VERSION "Version"

NS_ :

BS_:

BU_: Tester IBCS EPS ADC CCU CCU_CCURT1 CCU_CCURT2 EPB_IBCS EBB ZCUF ZCUL ZCUR ZCUT EMS IDM DCDC IPS NIDU NIDUF DCUR OBC OPC LPC CPC EMCM GCU DCUF IPU BMS EOPF EOPR EVCC DCDC2 EDL SRS ECS EPB RBM ICM IID IDC PHUDD AMP WHUD IMR INU IFC FAPA RRR RLR PAS PCS SCMR SCMRL SCMRR HVSMR SCMRM MFS WSM DRM IDU FCP LBMSAD AVAS ATSS DLPFL FBLCM FLISD FLLCM FRLCM RLLCMA RLLCMB RRLCMA RRLCMB RLISD DLPML DLPMR TRM PSDL PSDR HVSPRL HVSPRR RFR SBM WCM ETC TBOX2 TBOX CCURT1 CCURT2 RT1_C0 RT1_C1 RT2_C3 CBM RAS TMC SCMT PLGM LBMS RLBMS IDUR OTAWL RCICP WCMFR WCMRL LPC2 SAS CD RCP RRISD

BO_ 371 ADC_13_B: 64 ADC
 SG_ ADC_13_B_CRC : 7|16@0+ (1,0) [0|65535] ""  CCU,EPS,IBCS
 SG_ ADC_13_B_Counter : 23|8@0+ (1,0) [0|255] ""  CCU,EPS,IBCS
 SG_ ADC_DycEscTarTq : 63|16@0+ (1,-32768) [-32768|32767] "Nm"  IBCS
 SG_ ADC_DycEscTarTqfactor : 79|8@0+ (0.01,0) [0|1] ""  IBCS
 SG_ ADC_SteerTqReq : 87|12@0+ (0.01,-20) [-20|20] "Nm"  EPS
 SG_ ADC_SteerTqSt : 157|2@0+ (1,0) [0|3] ""  EPS
 SG_ ADC_TqEvsSteerReq : 152|1@0+ (1,0) [0|1] ""  EPS
 SG_ ADC_SteerTqAvl : 153|1@0+ (1,0) [0|1] ""  EPS
 SG_ ADC_DycEscTarTqVld : 166|1@0+ (1,0) [0|1] ""  IBCS
 SG_ ADC_DycEscTarTqEna : 167|1@0+ (1,0) [0|1] ""  IBCS
 SG_ ADC_RoadTyp : 162|3@0+ (1,0) [0|7] ""  CCU,ECS
 SG_ ADC_LeWhlLgtDst : 175|12@0+ (0.01,0) [0|30] "m"  CCU,ECS
 SG_ ADC_LeWhlRoadHei : 179|12@0+ (0.001,-0.5) [-0.5|0.523] "m"  CCU,ECS
 SG_ ADC_RiWhlLgtDst : 199|12@0+ (0.01,0) [0|30] "m"  CCU,ECS
 SG_ ADC_RiWhlRoadHei : 203|12@0+ (0.001,-0.5) [-0.5|0.523] "m"  CCU,ECS
 SG_ ADC_RiWhlRoadFeature : 223|5@0+ (1,0) [0|15] ""  CCU,ECS
 SG_ ADC_SuspensionStatus : 218|3@0+ (1,0) [0|7] ""  CCU,ECS
 SG_ ADC_LeWhlRoadSts : 231|2@0+ (1,0) [0|3] ""  CCU,ECS
 SG_ ADC_LeWhlRoadFeature : 229|4@0+ (1,0) [0|15] ""  CCU,ECS
 SG_ ADC_RiWhlRoadSts : 225|2@0+ (1,0) [0|3] ""  CCU,ECS
 SG_ ADC_CDCCtrlEnable : 239|1@0+ (1,0) [0|1] ""  CCU,ECS
 SG_ ADC_RoadInfoAvl : 238|1@0+ (1,0) [0|1] ""  CCU,ECS
 SG_ ADC_RoadFeatureDetFalutSts : 295|1@0+ (1,0) [0|1] ""  CCU,ECS
 SG_ ADC_RoadFeatureDetWorkSts : 247|2@0+ (1,0) [0|3] ""  CCU,ECS
 SG_ ADC_LeWhlRoadFeature2 : 251|4@0+ (1,0) [0|15] ""  CCU,ECS
 SG_ ADC_LeWhlRoadFeature3 : 255|4@0+ (1,0) [0|15] ""  CCU,ECS
 SG_ ADC_RiWhlRoadFeature2 : 259|4@0+ (1,0) [0|15] ""  CCU,ECS
 SG_ ADC_RiWhlRoadFeature3 : 263|4@0+ (1,0) [0|15] ""  CCU,ECS
 SG_ ADC_LeWhlRoadHei2 : 271|3@0+ (1,0) [0|7] ""  CCU,ECS
 SG_ ADC_LeWhlRoadHei3 : 268|3@0+ (1,0) [0|7] ""  CCU,ECS
 SG_ ADC_RiWhlRoadHei2 : 265|3@0+ (1,0) [0|7] ""  CCU,ECS
 SG_ ADC_RiWhlRoadHei3 : 278|3@0+ (1,0) [0|7] ""  CCU,ECS
 SG_ ADC_LeWhlLgtDst2 : 237|6@0+ (0.25,0) [0|15] "m"  CCU,ECS
 SG_ ADC_LeWhlLgtDst3 : 245|6@0+ (0.25,0) [0|15] "m"  CCU,ECS
 SG_ ADC_RiWhlLgtDst2 : 275|6@0+ (0.25,0) [0|15] "m"  CCU,ECS
 SG_ ADC_RiWhlLgtDst3 : 285|6@0+ (0.25,0) [0|15] "m"  CCU,ECS
 SG_ ADC_AS_SuspHeiAdj : 290|3@0+ (1,0) [0|7] ""  CCU,ECS
 SG_ ADC_AS_SuspHeiAdjVld : 291|1@0+ (1,0) [0|1] ""  CCU,ECS
 SG_ ADC_AS_SusStfnAdj : 300|3@0+ (1,0) [0|7] ""  CCU,ECS
 SG_ ADC_AS_SusStfnAdjVld : 292|1@0+ (1,0) [0|1] ""  CCU,ECS
 SG_ ADC_CDCModReq : 303|3@0+ (1,0) [0|7] ""  CCU,ECS
 SG_ ADC_CDCModReqVld : 294|1@0+ (1,0) [0|1] ""  CCU,ECS
 SG_ ADC_AS_LevelingAdj : 297|2@0+ (1,0) [0|3] ""  CCU,ECS
 SG_ ADC_AS_LevelingAdjVld : 293|1@0+ (1,0) [0|1] ""  CCU,ECS
 SG_ ADC_SdcPreAdjFL1 : 306|3@0+ (1,0) [0|7] ""  CCU,ECS
 SG_ ADC_SdcPreAdjFR1 : 314|3@0+ (1,0) [0|7] ""  CCU,ECS
 SG_ ADC_SdcPreAdjVld : 311|1@0+ (1,0) [0|1] ""  CCU,ECS
 SG_ ADC_SteerGainLevelTqCtrl : 359|8@0+ (1,0) [0|254] "%"  EPS

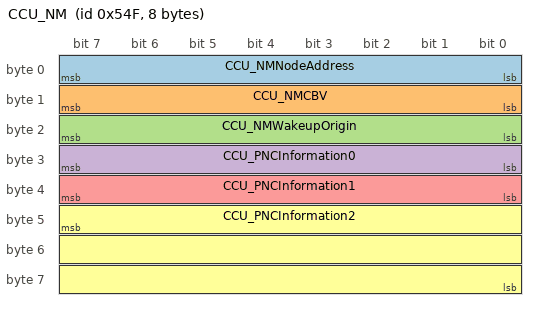
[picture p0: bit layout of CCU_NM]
BO_ 1359 CCU_NM: 8 CCU
 SG_ CCU_NMNodeAddress : 7|8@0+ (1,0) [0|255] ""  CCURT1,TMC,ZCUF,ZCUL,ZCUR,ZCUT,EMS,IPS,NIDU,NIDUF,BMS,EVCC,ECS,CBM,EPB,RBM,IBCS,ICM,IID,IDC,PHUDD,AMP,ADC,FAPA,SCMR,SCMRL,SCMRR,SCMRM,SCMT,IDU,LBMSAD,PLGM,TRM,PSDL,PSDR,LBMS,RLBMS,TBOX
 SG_ CCU_NMCBV : 15|8@0+ (1,0) [0|0] ""  CCURT1,TMC,ZCUF,ZCUL,ZCUR,ZCUT,EMS,IPS,NIDU,NIDUF,BMS,EVCC,ECS,CBM,EPB,RBM,IBCS,ICM,IID,IDC,PHUDD,AMP,ADC,FAPA,SCMR,SCMRL,SCMRR,SCMRM,SCMT,IDU,LBMSAD,PLGM,TRM,PSDL,PSDR,LBMS,RLBMS,TBOX
 SG_ CCU_NMWakeupOrigin : 23|8@0+ (1,0) [0|255] ""  CCURT1,TMC,ZCUF,ZCUL,ZCUR,ZCUT,EMS,IPS,NIDU,NIDUF,BMS,EVCC,ECS,CBM,RBM,IBCS,ICM,IID,IDC,PHUDD,AMP,ADC,FAPA,SCMR,SCMRL,SCMRR,SCMRM,SCMT,IDU,LBMSAD,PLGM,TRM,PSDL,PSDR,LBMS,RLBMS,TBOX
 SG_ CCU_PNCInformation0 : 31|8@0+ (1,0) [0|255] ""  CCURT1,TMC,ZCUF,ZCUL,ZCUR,ZCUT,EMS,IPS,NIDU,NIDUF,BMS,EVCC,ECS,CBM,EPB,RBM,IBCS,ICM,IID,IDC,PHUDD,AMP,ADC,FAPA,SCMR,SCMRL,SCMRR,SCMRM,SCMT,IDU,LBMSAD,PLGM,TRM,PSDL,PSDR,LBMS,RLBMS,TBOX
 SG_ CCU_PNCInformation1 : 39|8@0+ (1,0) [0|255] ""  CCURT1,TMC,ZCUF,ZCUL,ZCUR,ZCUT,EMS,IPS,NIDU,NIDUF,BMS,EVCC,ECS,CBM,EPB,RBM,IBCS,ICM,IID,IDC,PHUDD,AMP,ADC,FAPA,SCMR,SCMRL,SCMRR,SCMRM,SCMT,IDU,LBMSAD,PLGM,TRM,PSDL,PSDR,LBMS,RLBMS,TBOX
 SG_ CCU_PNCInformation2 : 47|24@0+ (1,0) [0|0] ""  CCURT1,TMC,ZCUF,ZCUL,ZCUR,ZCUT,EMS,IPS,NIDU,NIDUF,BMS,EVCC,ECS,CBM,EPB,RBM,IBCS,ICM,IID,IDC,PHUDD,AMP,ADC,FAPA,SCMR,SCMRL,SCMRR,SCMRM,SCMT,IDU,LBMSAD,PLGM,TRM,PSDL,PSDR,LBMS,RLBMS,TBOX

BO_ 905 CCU_IDC_ICM_1: 64 CCU
 SG_ ICM_SetIACCSt : 27|1@0+ (1,0) [0|1] ""  ADC,IFC,FAPA
 SG_ ICM_TotalOdometer : 35|20@0+ (1,0) [0|999999] "km"  ZCUF,ZCUL,ZCUR,ZCUT,EMS,NIDU,NIDUF,DCUR,IDUR,GCU,DCUF,IPU,ECS,EPS,EPB,IBCS,ADC,IFC,FAPA,RRR,RLR,PCS
 SG_ ICM_VehInsSpd : 103|8@0+ (1,0) [0|254] "km/h"  ADC,IFC,FAPA,RRR,RLR
 SG_ ICM_VehInsSpd_accurate : 272|11@0+ (0.1,0) [0|204.6] "km/h"  ECS,WHUD,ADC,IFC,FAPA,RRR,RLR
 SG_ ICM_FuelAvaibleDriveDistance : 311|11@0+ (1,0) [0|2046] "km"  ADC,FAPA
 SG_ ICM_TotalAvaibleDriveDistance : 316|11@0+ (1,0) [0|2046] "km"  ADC,FAPA

BO_ 516 CCU_VCU_9: 64 CCU_CCURT1
 SG_ VCU_9_CRC : 7|16@0+ (1,0) [0|65535] ""  CCURT2,RT2_C3,ZCUF,ZCUL,ZCUR,ZCUT,EMS,NIDU,DCUR,IDUR,EDL,ECS,EPB,IBCS,ICM,IDC,INU,ADC,IFC,FAPA,RRR,RLR,PAS
 SG_ VCU_9_Counter : 23|8@0+ (1,0) [0|255] ""  CCURT2,RT2_C3,ZCUF,ZCUL,ZCUR,ZCUT,EMS,NIDU,DCUR,IDUR,EDL,ECS,EPB,IBCS,ICM,IDC,INU,ADC,IFC,FAPA,RRR,RLR,PAS
 SG_ VCU_MaxDriveTorqVD : 25|1@0+ (1,0) [0|1] ""  ADC,IFC,FAPA
 SG_ VCU_RecpTorqVD : 74|1@0+ (1,0) [0|1] ""  IBCS,ADC,IFC,FAPA
 SG_ VCU_MaxRecpTorqVD : 72|1@0+ (1,0) [0|1] ""  IBCS,ADC,IFC,FAPA
 SG_ VCU_CrntGearLvl : 92|3@0+ (1,0) [0|7] ""  CCURT2,RT2_C3,OTAWL,ZCUF,ZCUL,ZCUR,ZCUT,NIDU,NIDUF,DCUR,IDUR,DCUF,IPU,SRS,ECS,RAS,EPS,EPB,IBCS,IDC,AMP,INU,ADC,IFC,FAPA,RRR,RLR,PAS,WSM,DLPML,DLPMR,TBOX
 SG_ VCU_CrntGearLvlVD : 88|1@0+ (1,0) [0|1] ""  ZCUF,ZCUL,ZCUR,ZCUT,SRS,ECS,EPS,EPB,IBCS,AMP,INU,ADC,IFC,FAPA,RRR,RLR,PAS
 SG_ VCU_BrkPedPstVD : 89|1@0+ (1,0) [0|1] ""  CCURT2,RT2_C3,NIDU,DCUR,IDUR,SRS,ECS,IBCS,IDC,ADC,IFC,FAPA,TBOX
 SG_ VCU_BrkPedPst : 103|8@0+ (0.392,0) [0|99.96] "%"  CCURT2,RT2_C3,NIDU,DCUR,IDUR,SRS,ECS,IBCS,IDC,ADC,IFC,FAPA,TBOX
 SG_ VCU_GearIntervern : 137|1@0+ (1,0) [0|1] ""  IBCS,ADC,IFC,FAPA
 SG_ VCU_AccPedalVirtPstVD : 136|1@0+ (1,0) [0|1] ""  CCURT2,RT2_C3,EMS,NIDU,DCUR,IDUR,SRS,ECS,IBCS,IDC,AMP,ADC,IFC,FAPA,TBOX
 SG_ VCU_ActVehWheelTorq : 378|15@0+ (1,-16000) [-16000|16000] "Nm"  ECS,IBCS,AMP,ADC
 SG_ VCU_MaxRecpTorq : 135|14@0+ (1,0) [0|16000] "Nm"  IBCS,ADC,IFC,FAPA
 SG_ VCU_AccPedalVirtPst : 146|9@0+ (0.2,0) [0|100] "%"  CCURT2,RT2_C3,EMS,NIDU,DCUR,IDUR,SRS,ECS,IBCS,IDC,AMP,ADC,IFC,FAPA,RRR,RLR,TBOX
 SG_ VCU_BrkPedalSt : 189|1@0+ (1,0) [0|1] ""  CCURT2,RT2_C3,EMS,SRS,ECS,IDC,ADC,IFC,FAPA,RRR,RLR,TBOX
 SG_ VCU_BrkPedalStVD : 188|1@0+ (1,0) [0|1] ""  CCURT2,RT2_C3,EMS,SRS,ECS,IDC,ADC,IFC,FAPA,TBOX
 SG_ VCU_ACCLimitOperatingSt : 186|1@0+ (1,0) [0|1] ""  ADC,IFC,FAPA
 SG_ VCU_AccButtInfo : 199|8@0+ (1,0) [0|255] ""  IDC,ADC,IFC,FAPA
 SG_ VCU_ACCmaxSpdLimit : 215|4@0+ (1,0) [0|15] ""  ADC,IFC,FAPA
 SG_ VCU_RecpTorqFAVD : 208|1@0+ (1,0) [0|1] ""  IBCS,ADC,IFC,FAPA
 SG_ VCU_RecpTorqRAVD : 209|1@0+ (1,0) [0|1] ""  IBCS,ADC,IFC,FAPA
 SG_ VCU_MaxRecpTorqFAVD : 152|1@0+ (1,0) [0|1] ""  IBCS,ADC,IFC,FAPA
 SG_ VCU_MaxRecpTorqRAVD : 153|1@0+ (1,0) [0|1] ""  IBCS,ADC,IFC,FAPA
 SG_ VCU_RecpTorq : 359|14@0+ (1,0) [0|16000] "Nm"  IBCS,ADC,IFC,FAPA
 SG_ VCU_MaxDriveTorq : 167|14@0+ (1,0) [0|16000] "Nm"  ECS,IBCS,ADC,IFC,FAPA
 SG_ VCU_RecpTorqFA : 231|14@0+ (1,0) [0|16000] "Nm"  IBCS,ADC,IFC,FAPA
 SG_ VCU_RecpTorqRA : 233|14@0+ (1,0) [0|16000] "Nm"  IBCS,ADC,IFC,FAPA
 SG_ VCU_MaxRecpTorqFA : 251|14@0+ (1,0) [0|16000] "Nm"  IBCS,ADC,IFC,FAPA
 SG_ VCU_MaxRecpTorqRA : 269|14@0+ (1,0) [0|16000] "Nm"  IBCS,ADC,IFC,FAPA
 SG_ VCU_BcsDecelEnable : 305|1@0+ (1,0) [0|1] ""  IBCS,IDC,ADC,IFC,FAPA
 SG_ VCU_CrntGearNoTrans : 317|3@0+ (1,0) [0|7] ""  ADC,IFC,FAPA
 SG_ VCU_EzTSt : 314|2@0+ (1,0) [0|3] ""  IBCS,IDC,ADC,FAPA
 SG_ VCU_ITASSt : 444|3@0+ (1,0) [0|7] ""  IBCS,IDC,ADC,FAPA

BO_ 909 CCU_ZCU_1: 64 CCU_CCURT2
 SG_ LCK_HoodAjarSt : 37|1@0+ (1,0) [0|1] ""  OTAWL,ZCUR,EMS,ECS,ICM,IID,IDC,PHUDD,AMP,ADC,IFC,FAPA,RRR,RLR,PCS
 SG_ LCK_FrontLeftDoorAjarSt : 36|1@0+ (1,0) [0|1] ""  OTAWL,ZCUF,ZCUR,ZCUT,EPB,IBCS,ICM,IID,IDC,PHUDD,AMP,IMR,ADC,IFC,FAPA,RRR,RLR,WSM,DLPML,DLPMR,PLGM
 SG_ LCK_FrontRightDoorAjarSt : 35|1@0+ (1,0) [0|1] ""  ZCUT,IBCS,ICM,IID,IDC,PHUDD,AMP,IMR,ADC,IFC,FAPA,RRR,RLR,WSM,DLPML,DLPMR,PLGM
 SG_ LCK_RearLeftDoorAjarSt : 34|1@0+ (1,0) [0|1] ""  OTAWL,ZCUL,ZCUR,ECS,IBCS,ICM,IID,IDC,PHUDD,AMP,IMR,ADC,IFC,FAPA,RRR,RLR,PCS,SCMR,SCMRL,SCMRR,SCMRM,DLPML,DLPMR,PLGM
 SG_ LCK_RearRightDoorAjarSt : 33|1@0+ (1,0) [0|1] ""  OTAWL,ZCUL,ZCUR,ECS,IBCS,ICM,IID,IDC,PHUDD,AMP,IMR,ADC,IFC,FAPA,RRR,RLR,PCS,SCMR,SCMRL,SCMRR,SCMRM,DLPML,DLPMR,PLGM
 SG_ LCK_TrunkAjarSt : 32|1@0+ (1,0) [0|1] ""  OTAWL,ZCUF,ZCUL,ZCUR,ECS,ICM,IID,IDC,PHUDD,AMP,IMR,ADC,IFC,FAPA,RRR,RLR,PCS
 SG_ LCK_FrontLeftDoorLockSt : 47|1@0+ (1,0) [0|1] ""  OTAWL,ZCUR,CBM,ICM,IDC,ADC,IFC,FAPA,RRR,RLR
 SG_ LCK_FrontRightDoorLockSt : 46|1@0+ (1,0) [0|1] ""  CBM,ICM,IDC,ADC,IFC,FAPA,RRR,RLR
 SG_ LCK_RearLeftDoorLockSt : 45|1@0+ (1,0) [0|1] ""  OTAWL,ZCUL,ZCUR,ECS,CBM,ICM,IDC,ADC,IFC,FAPA,RRR,RLR
 SG_ LCK_RearRightDoorLockSt : 44|1@0+ (1,0) [0|1] ""  OTAWL,ZCUL,ZCUR,ECS,CBM,ICM,IDC,ADC,IFC,FAPA,RRR,RLR
 SG_ LCK_RearLeftChildSaftyLockSt : 43|1@0+ (1,0) [0|1] ""  ZCUL,ZCUR,CBM,ICM,IDC,ADC,IFC,FAPA,RRR,RLR
 SG_ LCK_RearRightChildSaftyLockSt : 42|1@0+ (1,0) [0|1] ""  OTAWL,ZCUL,ZCUR,CBM,ICM,IDC,ADC,IFC,FAPA,RRR,RLR
 SG_ EMS_EngStForPHEV : 79|3@0+ (1,0) [0|7] ""  NIDU,BMS,IDC,ADC,FAPA
 SG_ WCM_Reminder : 103|1@0+ (1,0) [0|1] ""  ADC,FAPA
 SG_ WCM_ChargingSt : 89|2@0+ (1,0) [0|3] ""  ADC,FAPA
 SG_ LCK_FrontLeftDoorHandlePosition : 135|8@0+ (1,0) [0|255] ""  CBM,ICM,IDC,ADC,FAPA
 SG_ LCK_FrontRightDoorHandlePosition : 143|8@0+ (1,0) [0|255] ""  CBM,ICM,IDC,ADC,FAPA
 SG_ LCK_RearLeftDoorHandlePosition : 151|8@0+ (1,0) [0|255] ""  ZCUL,ZCUR,CBM,ICM,IDC,ADC,FAPA
 SG_ LCK_RearRightDoorHandlePosition : 159|8@0+ (1,0) [0|255] ""  ZCUL,ZCUR,CBM,ICM,IDC,ADC,FAPA
 SG_ WW_RWPMotorSt : 226|3@0+ (1,0) [0|7] ""  ADC,IFC,FAPA
 SG_ LCK_FillerCapASt : 239|1@0+ (1,0) [0|1] ""  ZCUL,ZCUR,EMS,ICM,IDC,ADC,FAPA
 SG_ LCK_FillerCapBSt : 238|1@0+ (1,0) [0|1] ""  ZCUL,ZCUR,EMS,ICM,IDC,ADC,FAPA
 SG_ MR_LeftMirrorFoldUnfoldSt : 233|2@0+ (1,0) [0|3] ""  ADC,IFC,FAPA,RRR,RLR,PCS,WSM,DLPML,DLPMR
 SG_ SBM_SwapHvBattModeSt : 247|4@0+ (1,0) [0|15] ""  ADC,FAPA
 SG_ SBM_SwapStaDiagCode : 243|4@0+ (1,0) [0|15] ""  ADC,FAPA
 SG_ SBM_SwapVehDiagCode : 255|4@0+ (1,0) [0|15] ""  ADC,FAPA
 SG_ SBM_SwapHvBattModeFaultSt : 251|3@0+ (1,0) [0|7] ""  ADC,FAPA
 SG_ IPDS_HDMapPowerSt : 271|1@0+ (1,0) [0|1] ""  ADC,IFC,FAPA
 SG_ IPDS_KL15L1PowerSt : 270|1@0+ (1,0) [0|1] ""  EBB,IBCS,ADC,IFC,FAPA,RRR,RLR
 SG_ IPDS_SRSECUPowerSt : 269|1@0+ (1,0) [0|1] ""  EPS,IBCS,ADC,IFC,FAPA
 SG_ IPDS_HODPowerSt : 268|1@0+ (1,0) [0|1] ""  ADC,IFC,FAPA
 SG_ KAE_BLEOption : 265|1@0+ (1,0) [0|1] ""  ADC,FAPA
 SG_ KAE_UWBOption : 264|1@0+ (1,0) [0|1] ""  ADC,FAPA
 SG_ PWL_WinCurrentPos_FLWinPst : 470|8@0+ (0.5,0) [0|100] "%"  ZCUT,ADC,FAPA,PLGM
 SG_ UINM_FrontLeftPowerReleaseReq : 456|1@0+ (1,0) [0|1] ""  ADC,FAPA
 SG_ UINM_FrontLeftPowerReleaseFaultSt : 457|1@0+ (1,0) [0|1] ""  ADC,FAPA
 SG_ UINM_FrontRightPowerReleaseReq : 458|1@0+ (1,0) [0|1] ""  ADC,FAPA
 SG_ UINM_FrontRightPowerReleaseFaultSt : 459|1@0+ (1,0) [0|1] ""  ADC,FAPA
 SG_ UINM_RearLeftPowerReleaseFaultSt : 460|1@0+ (1,0) [0|1] ""  ADC,FAPA
 SG_ UINM_RearLeftPowerReleaseReq : 461|1@0+ (1,0) [0|1] ""  ADC,FAPA
 SG_ UINM_RearRightPowerReleaseFaultSt : 462|1@0+ (1,0) [0|1] ""  ADC,FAPA
 SG_ UINM_RearRightPowerReleaseReq : 471|1@0+ (1,0) [0|1] ""  ADC,FAPA
 SG_ BMS_BattSOCAccurate : 478|14@0+ (0.01,0) [0|100] "%"  ADC,FAPA
 SG_ PWL_WinCurrentPos_RRWinPst : 503|8@0+ (0.5,0) [0|100] "％"  IDC,RCICP,AMP,IMR,ADC,FAPA,PLGM,HVSPRL,HVSPRR
 SG_ PWL_WinCurrentPos_RLWinPst : 511|8@0+ (0.5,0) [0|100] "％"  ZCUR,IDC,RCICP,AMP,IMR,ADC,FAPA,PLGM,HVSPRL,HVSPRR
 SG_ ACEleclocksSt : 282|3@0+ (1,0) [0|7] ""  ADC,FAPA
 SG_ DSASBM_MotResp : 375|4@0+ (1,0) [0|15] ""  ADC,FAPA

BO_ 792 CCU_ZCU_4: 64 CCU_CCURT2
 SG_ UMM_SecondRHSeatSt : 37|2@0+ (1,0) [0|3] ""  ICM,IDC,ADC,IFC
 SG_ UMM_SecondLHSeatSt : 39|2@0+ (1,0) [0|3] ""  ICM,IDC,ADC,IFC
 SG_ LCK_PowerFillerCapAngle : 103|8@0+ (1,0) [0|255] "deg"  ICM,IDC,ADC,FAPA
 SG_ EL_ReverseLightSt : 111|1@0+ (1,0) [0|1] ""  IDC,ADC,IFC,FAPA,PCS
 SG_ EL_ReverseLightFaultSt : 110|1@0+ (1,0) [0|1] ""  ICM,IDC,ADC,IFC,FAPA
 SG_ EL_RLPositionLightSt : 105|1@0+ (1,0) [0|1] ""  ICM,IDC,ADC,IFC,FAPA
 SG_ EL_RLPositionLightFaultSt : 104|1@0+ (1,0) [0|1] ""  ICM,IDC,ADC,IFC,FAPA
 SG_ EL_RRPositionLightSt : 119|1@0+ (1,0) [0|1] ""  ICM,IDC,ADC,IFC,FAPA
 SG_ EL_RRPositionLightFaultSt : 118|1@0+ (1,0) [0|1] ""  ICM,IDC,ADC,IFC,FAPA
 SG_ EL_RearFogLightSt : 117|1@0+ (1,0) [0|1] ""  ICM,IDC,ADC,IFC,FAPA
 SG_ EL_RearFogLightFaultSt : 116|1@0+ (1,0) [0|1] ""  ICM,IDC,ADC,IFC,FAPA

BO_ 860 CCU_VCU_7: 64 CCU_CCURT1
 SG_ VCU_7_CRC : 7|16@0+ (1,0) [0|65535] ""  CCURT2,RT2_C3,ZCUF,ZCUL,ZCUR,ZCUT,EPB,IDC,ADC,IFC,FAPA,RRR,RLR,DRM
 SG_ VCU_7_Counter : 23|8@0+ (1,0) [0|255] ""  CCURT2,RT2_C3,ZCUF,ZCUL,ZCUR,ZCUT,EPB,IDC,ADC,IFC,FAPA,RRR,RLR,DRM
 SG_ VCU_RoadMod : 27|3@0+ (1,0) [0|7] ""  ECS,IBCS,IDC,ADC,FAPA
 SG_ VCU_GearLvl : 31|4@0+ (1,0) [0|15] ""  CCURT2,RT2_C3,ZCUF,ZCUL,ZCUR,ZCUT,EMS,EPB,IBCS,ADC,IFC,FAPA,RRR,RLR,DRM
 SG_ VCU_VehDrvMod : 38|3@0+ (1,0) [0|7] ""  ZCUL,ZCUR,EMS,ECS,IBCS,ICM,IDC,AMP,ADC,IFC,FAPA,ATSS,WCM,WCMFR,WCMRL
 SG_ VCU_VehRdySt : 39|1@0+ (1,0) [0|1] ""  CCURT2,RT2_C3,OTAWL,ZCUF,ZCUL,ZCUR,ZCUT,EMS,IDM,IPS,NIDU,NIDUF,DCUR,IDUR,OBC,GCU,DCUF,IPU,BMS,ECS,EPB,IBCS,ICM,IID,IDC,PHUDD,ADC,IFC,FAPA,RRR,RLR,TBOX
 SG_ VCU_PlgConnSt : 91|1@0+ (1,0) [0|1] ""  CCURT2,RT2_C3,ZCUR,ZCUT,NIDU,NIDUF,DCUR,IDUR,GCU,DCUF,IPU,ECS,ICM,IID,IDC,PHUDD,ADC,IFC,FAPA
 SG_ VCU_GearLvlDisp : 155|4@0+ (1,0) [0|15] ""  ICM,IID,IDC,PHUDD,WHUD,IMR,ADC,IFC,FAPA,PCS
 SG_ VCU_SuspModeReq : 257|2@0+ (1,0) [0|3] ""  ECS,ADC,IFC,FAPA
 SG_ VCU_SuspModeReqEnable : 316|1@0+ (1,0) [0|1] ""  ECS,ADC,IFC,FAPA
 SG_ VCU_GearPosition : 315|3@0+ (1,0) [0|7] ""  CCURT2,RT2_C3,BMS,ADC,IFC,FAPA
 SG_ VCU_EcoPlusMod : 341|2@0+ (1,0) [0|3] ""  CCURT2,RT2_C3,IDC,WHUD,ADC
 SG_ ICC_RoadMod : 339|4@0+ (1,0) [0|8] ""  CCURT2,RT2_C3,NIDU,BMS,ECS,IBCS,IDC,AMP,ADC,WSM,ATSS
 SG_ VCU_TrailerModeSt : 396|3@0+ (1,0) [0|7] ""  ECS,IBCS,IDC,ADC
 SG_ VCU_BMS_BattSocDisp : 405|14@0+ (0.01,0) [0|100] "%"  CCURT2,RT2_C3,ZCUL,ZCUR,EMS,BMS,ICM,IID,IDC,PHUDD,ADC
 SG_ VCU_VehElcConspAccumAvg : 429|10@0+ (0.1,-51) [-51|51.2] "kWh/100km"  CCURT2,RT2_C3,BMS,IDC,ADC
 SG_ ICC_360Switch : 435|2@0+ (1,0) [0|3] ""  IDC,ADC

BO_ 431 CCU_VCU_8: 64 CCU_CCURT1
 SG_ VCU_TargetRecpTorqVD : 132|1@0+ (1,0) [0|1] ""  IBCS,ADC,IFC,FAPA
 SG_ VCU_AccDriverOrvd : 150|1@0+ (1,0) [0|1] ""  ADC,IFC,FAPA
 SG_ VCU_AccDriverOrvdVD : 154|1@0+ (1,0) [0|1] ""  IBCS,ADC
 SG_ VCU_TargetRecpTorq : 423|14@0+ (1,0) [0|16000] "Nm"  IBCS,ADC,IFC,FAPA
 SG_ VCU_TargetRecpTorqFA : 153|14@0+ (1,0) [0|16000] "Nm"  IBCS,ADC,IFC,FAPA
 SG_ VCU_TargetRecpTorqRA : 171|14@0+ (1,0) [0|16000] "Nm"  IBCS,ADC,IFC,FAPA
 SG_ VCU_TorqDriverReqFA : 189|14@0+ (1,0) [0|16000] "Nm"  ECS,IBCS,ADC,IFC,FAPA
 SG_ VCU_TorqDriverReqRA : 207|14@0+ (1,0) [0|16000] "Nm"  ECS,IBCS,ADC,IFC,FAPA
 SG_ VCU_VehActDrvTorqFA : 209|14@0+ (1,0) [0|16000] "Nm"  ECS,EPS,IBCS,IDC,ADC,IFC,FAPA
 SG_ VCU_VehActDrvTorqRA : 227|14@0+ (1,0) [0|16000] "Nm"  IDM,ECS,EPS,IBCS,IDC,ADC,IFC,FAPA
 SG_ VCU_TargetRecpTorqFAVD : 104|1@0+ (1,0) [0|1] ""  IBCS,ADC,IFC,FAPA
 SG_ VCU_TargetRecpTorqRAVD : 105|1@0+ (1,0) [0|1] ""  IBCS,ADC,IFC,FAPA
 SG_ VCU_TorqDriverReqFAVD : 128|1@0+ (1,0) [0|1] ""  ECS,IBCS,ADC,IFC,FAPA
 SG_ VCU_TorqDriverReqRAVD : 129|1@0+ (1,0) [0|1] ""  ECS,IBCS,ADC,IFC,FAPA
 SG_ VCU_VehActDrvTorqFAVD : 244|1@0+ (1,0) [0|1] ""  ECS,EPS,IBCS,ADC,IFC,FAPA
 SG_ VCU_VehActDrvTorqRAVD : 245|1@0+ (1,0) [0|1] ""  IDM,ECS,EPS,IBCS,ADC,IFC,FAPA
 SG_ VCU_BcsDecelReq : 243|4@0+ (0.066,-0.99) [-0.99|0] "m/s2"  IBCS,ADC,IFC,FAPA
 SG_ VCU_BcsDecelVD : 255|1@0+ (1,0) [0|1] ""  IBCS,ADC,IFC,FAPA
 SG_ VCU_RecpTorqRL : 261|14@0+ (1,0) [0|16000] ""  IBCS,ADC,FAPA
 SG_ VCU_RecpTorqRLVD : 262|1@0+ (1,0) [0|1] ""  IBCS,ADC,FAPA
 SG_ VCU_RecpTorqRR : 277|14@0+ (1,0) [0|16000] ""  IBCS,ADC,FAPA
 SG_ VCU_RecpTorqRRVD : 278|1@0+ (1,0) [0|1] ""  IBCS,ADC,FAPA
 SG_ VCU_ADSNetErrorFb : 159|3@0+ (1,0) [0|7] ""  ADC,IFC,FAPA
 SG_ VCU_NetModeResp : 156|2@0+ (1,0) [0|3] ""  ADC,FAPA
 SG_ VCU_PwrLimDrv_kW : 322|11@0+ (1,-1024) [-1024|1023] "kW"  ADC
 SG_ VCU_PwrLimRegen_kW : 343|11@0+ (1,-1024) [-1024|1023] "kW"  ADC
 SG_ VCU_PwrLimDrv_kWVD : 346|1@0+ (1,0) [0|1] ""  ADC
 SG_ VCU_PwrLimRegen_kWVD : 347|1@0+ (1,0) [0|1] ""  ADC
 SG_ VCU_PtTqActvStsFL : 348|1@0+ (1,0) [0|1] ""  ADC
 SG_ VCU_PtTqActvStsFR : 441|1@0+ (1,0) [0|1] ""  ADC
 SG_ VCU_PtTqActvStsRL : 442|1@0+ (1,0) [0|1] ""  ADC
 SG_ VCU_PtTqActvStsRR : 443|1@0+ (1,0) [0|1] ""  ADC

BO_ 430 CCU_SRS_1: 64 CCU
 SG_ SRS_1_CRC_1 : 7|16@0+ (1,0) [0|65535] ""  ZCUF,ZCUL,ZCUR,ZCUT,EMS,CBM,EPS,EPB,IDC,ADC,IFC,FAPA,RRR,RLR,LBMSAD,PSDL,PSDR,LBMS,TBOX2,TBOX
 SG_ SRS_1_Counter_1 : 23|8@0+ (1,0) [0|255] ""  ZCUF,ZCUL,ZCUR,ZCUT,EMS,CBM,EPS,EPB,IDC,ADC,IFC,FAPA,RRR,RLR,LBMSAD,PSDL,PSDR,LBMS,TBOX2,TBOX
 SG_ SRS_CrashOutputSt : 31|8@0+ (1,0) [0|160] ""  ZCUF,ZCUL,ZCUR,ZCUT,EMS,CBM,IDC,ADC,IFC,FAPA,LBMSAD,PSDL,PSDR,LBMS,TBOX2,TBOX
 SG_ SRS_Front_CrashOutputSt : 39|1@0+ (1,0) [0|1] ""  ZCUF,ZCUL,ZCUR,IDC,ADC,IFC,FAPA,PSDL,PSDR,TBOX2,TBOX
 SG_ SRS_DriverSide_CrashOutputSt : 38|1@0+ (1,0) [0|1] ""  ZCUF,ZCUL,ZCUR,IDC,ADC,IFC,FAPA,PSDL,PSDR,TBOX2,TBOX
 SG_ SRS_PassengerSide_CrashOutputSt : 37|1@0+ (1,0) [0|1] ""  ZCUF,ZCUL,ZCUR,IDC,ADC,IFC,FAPA,PSDL,PSDR,TBOX2,TBOX
 SG_ SRS_Rear_CrashOutputSt : 36|1@0+ (1,0) [0|1] ""  ZCUF,ZCUL,ZCUR,IDC,ADC,IFC,FAPA,PSDL,PSDR,TBOX2,TBOX
 SG_ SRS_RolloverCrashOutputSt : 35|1@0+ (1,0) [0|1] ""  ZCUF,ZCUL,ZCUR,IDC,ADC,IFC,FAPA,PSDL,PSDR,TBOX2,TBOX
 SG_ SRS_NearCrashOutputSt : 34|1@0+ (1,0) [0|1] ""  ZCUF,ZCUL,ZCUR,IDC,ADC,IFC,FAPA,PSDL,PSDR,TBOX2,TBOX
 SG_ SRS_YawSnsCalibSt : 135|1@0+ (1,0) [0|1] ""  ZCUF,ZCUL,ZCUR,IDC,ADC,IFC,FAPA,RRR,RLR,TBOX
 SG_ SRS_VehLongAccelVD : 134|2@0+ (1,0) [0|3] ""  ZCUF,ZCUL,ZCUR,ZCUT,EPS,EPB,IDC,ADC,IFC,FAPA,RRR,RLR,PCS,TBOX
 SG_ SRS_VehLatrlAccelVD : 132|2@0+ (1,0) [0|3] ""  ZCUF,ZCUL,ZCUR,EPS,IDC,ADC,IFC,FAPA,RRR,RLR,PCS,TBOX
 SG_ SRS_YawRateVD : 130|2@0+ (1,0) [0|3] ""  ZCUF,ZCUL,ZCUR,EPS,IDC,ADC,IFC,FAPA,RRR,RLR,PCS,TBOX
 SG_ SRS_VehLongAccel : 143|12@0+ (0.001,-2) [-2|2] "g"  ZCUF,ZCUL,ZCUR,ZCUT,EPS,EPB,IDC,ADC,IFC,FAPA,RRR,RLR,PCS,TBOX
 SG_ SRS_VehLatrlAccel : 147|12@0+ (0.001,-2) [-2|2] "g"  ZCUF,ZCUL,ZCUR,EPS,IDC,ADC,IFC,FAPA,RRR,RLR,PCS,TBOX
 SG_ SRS_YawRate : 167|16@0+ (0.01,-180) [-180|180] "deg/s"  ZCUF,ZCUL,ZCUR,EPS,IDC,ADC,IFC,FAPA,RRR,RLR,PCS,TBOX

BO_ 831 CCU_VCU_4_New: 64 CCU_CCURT1
 SG_ VCU_ChgActiveSt : 183|1@0+ (1,0) [0|1] ""  ZCUL,ICM,IDC,ADC

BO_ 290 CCU_PowerOn: 64 CCU_CCURT1
 SG_ IPDS_FrontRadarPowerSup : 33|2@0+ (1,0) [0|3] ""  CCURT2,RT2_C3,ZCUF,ZCUL,ADC
 SG_ IPDS_FLRadarPowerSup : 47|2@0+ (1,0) [0|3] ""  CCURT2,RT2_C3,ZCUF,ZCUL,ADC
 SG_ IPDS_FRRadarPowerSup : 45|2@0+ (1,0) [0|3] ""  CCURT2,RT2_C3,ZCUF,ZCUL,ADC
 SG_ IPDS_HDMapPowerSup : 79|2@0+ (1,0) [0|3] ""  CCURT2,RT2_C3,ZCUL,ADC
 SG_ IPDS_Lidar1PowerSup : 77|2@0+ (1,0) [0|3] ""  CCURT2,RT2_C3,ZCUL,ADC
 SG_ IPDS_RearRadarPowerSup : 129|2@0+ (1,0) [0|3] ""  CCURT2,RT2_C3,ZCUR,ZCUT,ADC

CM_ SG_ 371 ADC_13_B_CRC "E2E Profile 5 CRC";
CM_ SG_ 371 ADC_13_B_Counter "E2E Profile 5 Counter";
CM_ SG_ 371 ADC_DycEscTarTq "The total target torque of the DYC(Direct  yaw moment control).";
CM_ SG_ 371 ADC_DycEscTarTqfactor "Partition coefficient of  total target torque of the DYC:front axle/total";
CM_ SG_ 371 ADC_SteerTqReq "Steering torque request value";
CM_ SG_ 371 ADC_SteerTqSt "Steering torque request  enable state";
CM_ SG_ 371 ADC_TqEvsSteerReq "Emergency Collision avoidance steering mode request";
CM_ SG_ 371 ADC_SteerTqAvl "Steering torque request avaliable state";
CM_ SG_ 371 ADC_DycEscTarTqVld "The validity of total target torque of the DYC.";
CM_ SG_ 371 ADC_DycEscTarTqEna "The enable status  of total target torque of the DYC.";
CM_ SG_ 371 ADC_RoadTyp "Pavement condition type";
CM_ SG_ 371 ADC_LeWhlLgtDst "The distance from the projection point of the left front wheel center on the ground to the edge of the road feature area";
CM_ SG_ 371 ADC_LeWhlRoadHei "Left front wheel front feature road bump height (or dip depth)";
CM_ SG_ 371 ADC_RiWhlLgtDst "The distance from the projection point of the right front wheel center on the ground to the edge of the road feature area";
CM_ SG_ 371 ADC_RiWhlRoadHei "Right front wheel front feature road bump height (or dip depth)";
CM_ SG_ 371 ADC_RiWhlRoadFeature "Right wheel single road feature type";
CM_ SG_ 371 ADC_SuspensionStatus "ADS air suspension status request";
CM_ SG_ 371 ADC_LeWhlRoadSts "Left wheel pavement uneven (concave/convex) condition";
CM_ SG_ 371 ADC_LeWhlRoadFeature "Left-wheel single road feature type";
CM_ SG_ 371 ADC_RiWhlRoadSts "Uneven (concave/convex) condition of the right wheel pavement";
CM_ SG_ 371 ADC_CDCCtrlEnable "ADS Enable signal";
CM_ SG_ 371 ADC_RoadInfoAvl "Road information significance";
CM_ SG_ 371 ADC_RoadFeatureDetFalutSts "Road feature Dettion Fault Status";
CM_ SG_ 371 ADC_RoadFeatureDetWorkSts "Road feature Dettion Work Status";
CM_ SG_ 371 ADC_LeWhlRoadFeature2 "Left-wheel single road feature2 type";
CM_ SG_ 371 ADC_LeWhlRoadFeature3 "Left-wheel single road feature3 type";
CM_ SG_ 371 ADC_RiWhlRoadFeature2 "Right wheel single road feature2 type";
CM_ SG_ 371 ADC_RiWhlRoadFeature3 "Right wheel single road feature3 type";
CM_ SG_ 371 ADC_LeWhlRoadHei2 "Left front wheel front feature2 road bump height (or dip depth)";
CM_ SG_ 371 ADC_LeWhlRoadHei3 "Left front wheel front feature3 road bump height (or dip depth)";
CM_ SG_ 371 ADC_RiWhlRoadHei2 "Right front wheel front feature2 road bump height (or dip depth)";
CM_ SG_ 371 ADC_RiWhlRoadHei3 "Right front wheel front feature3 road bump height (or dip depth)";
CM_ SG_ 371 ADC_LeWhlLgtDst2 "The distance from the projection point of the left front wheel center on the ground to the edge of the road feature2 area";
CM_ SG_ 371 ADC_LeWhlLgtDst3 "The distance from the projection point of the left front wheel center on the ground to the edge of the road feature3 area";
CM_ SG_ 371 ADC_RiWhlLgtDst2 "The distance from the projection point of the right front wheel center on the ground to the edge of the road feature2 area";
CM_ SG_ 371 ADC_RiWhlLgtDst3 "The distance from the projection point of the right front wheel center on the ground to the edge of the road feature3 area";
CM_ SG_ 371 ADC_AS_SuspHeiAdj "Request suspension adjustment control signal";
CM_ SG_ 371 ADC_AS_SuspHeiAdjVld "Request?suspension?adjustment?control?significant?signal";
CM_ SG_ 371 ADC_AS_SusStfnAdj "Request suspension stiffness adjustment control signal";
CM_ SG_ 371 ADC_AS_SusStfnAdjVld "Request suspension stiffness adjustment to control the significant signal";
CM_ SG_ 371 ADC_CDCModReq "Request?shock?absorber?damper?adjustment?control?signal";
CM_ SG_ 371 ADC_CDCModReqVld "Request damper damper regulation control significant signal";
CM_ SG_ 371 ADC_AS_LevelingAdj "ADS requests dynamic leveling of the suspension";
CM_ SG_ 371 ADC_AS_LevelingAdjVld "ADS requests dynamic leveling of the suspension significant?signal";
CM_ SG_ 371 ADC_SdcPreAdjFL1 "Based on the unevenness of the road ahead, ADC sends a pre-adjustment gear signal, and the actuator adjusts the damping according to the pre-adjustment gear signal from ADC.";
CM_ SG_ 371 ADC_SdcPreAdjFR1 "Based on the unevenness of the road ahead, ADC sends a pre-adjustment gear signal, and the actuator adjusts the damping according to the pre-adjustment gear signal from ADC.";
CM_ SG_ 371 ADC_SdcPreAdjVld "The valid bit signal of the pre-regulation function";
CM_ SG_ 371 ADC_SteerGainLevelTqCtrl "Driver steering torque gain request value";
CM_ SG_ 1359 CCU_NMNodeAddress "CCU node address";
CM_ SG_ 1359 CCU_NMCBV "CCU Network management control bit vector";
CM_ SG_ 1359 CCU_NMWakeupOrigin "Origin of the wake up";
CM_ SG_ 1359 CCU_PNCInformation0 "PNC Information";
CM_ SG_ 1359 CCU_PNCInformation1 "PNC Information";
CM_ SG_ 1359 CCU_PNCInformation2 "PNC Information";
CM_ SG_ 905 ICM_SetIACCSt "ICM set IACC status";
CM_ SG_ 905 ICM_TotalOdometer "Total odometer";
CM_ SG_ 905 ICM_VehInsSpd "Vehicle instantaneous speed";
CM_ SG_ 905 ICM_VehInsSpd_accurate "Vehicle instantaneous speed";
CM_ SG_ 905 ICM_FuelAvaibleDriveDistance "The available driving distance according to the fuel";
CM_ SG_ 905 ICM_TotalAvaibleDriveDistance "The available driving distance according to the total";
CM_ SG_ 516 VCU_9_CRC "E2E Profile 5 CRC";
CM_ SG_ 516 VCU_9_Counter "E2E Profile 5 Counter";
CM_ SG_ 516 VCU_MaxDriveTorqVD "Actual effective maximum adjustable torque on wheel level validity";
CM_ SG_ 516 VCU_RecpTorqVD "Status of recuperation torque of generator";
CM_ SG_ 516 VCU_MaxRecpTorqVD "Status of target recuperation torque request by BCS to generator";
CM_ SG_ 516 VCU_CrntGearLvl "VCU current carry out gear level";
CM_ SG_ 516 VCU_CrntGearLvlVD "Valid bit for ActualGearPosition.";
CM_ SG_ 516 VCU_BrkPedPstVD "Current brake pedal position valid data";
CM_ SG_ 516 VCU_BrkPedPst "Current brake pedal position";
CM_ SG_ 516 VCU_GearIntervern "During parking, If there is a request from GSM to change the gearlevel, this signal will be set to 1:with intervention (GSM gearlevel invalid will also be regard as a gearlevel request)";
CM_ SG_ 516 VCU_AccPedalVirtPstVD "Current accelerate pedal actual position validity";
CM_ SG_ 516 VCU_ActVehWheelTorq "Actual effective engine torque on wheel level";
CM_ SG_ 516 VCU_MaxRecpTorq "Current maximum available recuperation torque of generator";
CM_ SG_ 516 VCU_AccPedalVirtPst "Current accelerate pedal actual position";
CM_ SG_ 516 VCU_BrkPedalSt " Brake pedal status";
CM_ SG_ 516 VCU_BrkPedalStVD "VCU_EMS_BrakePedSt valid data";
CM_ SG_ 516 VCU_ACCLimitOperatingSt "Operation status of ACC Limit mode, When VCU Enter the power-saving mode";
CM_ SG_ 516 VCU_AccButtInfo "ACC Button Information";
CM_ SG_ 516 VCU_ACCmaxSpdLimit "When VCU Enter the power-saving mode，the maximum ACC target speed limited by VCU";
CM_ SG_ 516 VCU_RecpTorqFAVD "Status of front axel maximum recuperation torque of generator";
CM_ SG_ 516 VCU_RecpTorqRAVD "Status of rear axel maximum recuperation torque of generator";
CM_ SG_ 516 VCU_MaxRecpTorqFAVD "Status of front axel maximum recuperation torque of generator";
CM_ SG_ 516 VCU_MaxRecpTorqRAVD "Status of front axel maximum recuperation torque of generator";
CM_ SG_ 516 VCU_RecpTorq "Current recuperation torque of generator";
CM_ SG_ 516 VCU_MaxDriveTorq "Actual effective maximum adjustable torque on wheel level";
CM_ SG_ 516 VCU_RecpTorqFA "Current recuperation torque of generator FA";
CM_ SG_ 516 VCU_RecpTorqRA "Current recuperation torque of generator RA";
CM_ SG_ 516 VCU_MaxRecpTorqFA "Current maximum available recuperation torque of generator FA";
CM_ SG_ 516 VCU_MaxRecpTorqRA "Current maximum available recuperation torque of generator RA";
CM_ SG_ 516 VCU_BcsDecelEnable "AVDC deceleration to BCS enable";
CM_ SG_ 516 VCU_CrntGearNoTrans "VCU Gear Lever send to ADS without trans";
CM_ SG_ 516 VCU_EzTSt "This signal indicates VCU-Easy turn state";
CM_ SG_ 516 VCU_ITASSt "This signal indicates VCU state that can enter iTAS or not";
CM_ SG_ 909 LCK_HoodAjarSt "HoodAjarSt";
CM_ SG_ 909 LCK_FrontLeftDoorAjarSt "FrontLeftDoorAjarSt";
CM_ SG_ 909 LCK_FrontRightDoorAjarSt "FrontRightDoorAjarSt";
CM_ SG_ 909 LCK_RearLeftDoorAjarSt "RearLeftDoorAjarSt";
CM_ SG_ 909 LCK_RearRightDoorAjarSt "RearRightDoorAjarSt";
CM_ SG_ 909 LCK_TrunkAjarSt "TrunkAjarSt";
CM_ SG_ 909 LCK_FrontLeftDoorLockSt "FrontLeftDoorLockSt";
CM_ SG_ 909 LCK_FrontRightDoorLockSt "FrontRightDoorLockSt";
CM_ SG_ 909 LCK_RearLeftDoorLockSt "RearLeftDoorLockSt";
CM_ SG_ 909 LCK_RearRightDoorLockSt "RearRightDoorLockSt";
CM_ SG_ 909 LCK_RearLeftChildSaftyLockSt "RearLeftChildSaftyLockSt";
CM_ SG_ 909 LCK_RearRightChildSaftyLockSt "RearRightChildSaftyLockSt";
CM_ SG_ 909 EMS_EngStForPHEV "Engine running status for PHEV";
CM_ SG_ 909 WCM_Reminder "Reminder the Phone lft";
CM_ SG_ 909 WCM_ChargingSt "Changing is ongoing or stopped";
CM_ SG_ 909 LCK_FrontLeftDoorHandlePosition "FrontLeftDoorHandlePosition";
CM_ SG_ 909 LCK_FrontRightDoorHandlePosition "FrontRightDoorHandlePosition";
CM_ SG_ 909 LCK_RearLeftDoorHandlePosition "RearLeftDoorHandlePosition";
CM_ SG_ 909 LCK_RearRightDoorHandlePosition "RearRightDoorHandlePosition";
CM_ SG_ 909 WW_RWPMotorSt "RearWiper Motor status";
CM_ SG_ 909 LCK_FillerCapASt "FillerCapASt";
CM_ SG_ 909 LCK_FillerCapBSt "FillerCapBSt";
CM_ SG_ 909 MR_LeftMirrorFoldUnfoldSt "Left Mirror Fold Unfold Status";
CM_ SG_ 909 SBM_SwapHvBattModeSt "Swap station mode statue";
CM_ SG_ 909 SBM_SwapStaDiagCode "Swap station erroe";
CM_ SG_ 909 SBM_SwapVehDiagCode "vehicl erroe in swap station";
CM_ SG_ 909 SBM_SwapHvBattModeFaultSt "Swap station mode fault statue";
CM_ SG_ 909 IPDS_HDMapPowerSt "HD map power state";
CM_ SG_ 909 IPDS_KL15L1PowerSt "KL15 L1 power state";
CM_ SG_ 909 IPDS_SRSECUPowerSt "SRS ECU power state";
CM_ SG_ 909 IPDS_HODPowerSt "HOD power state";
CM_ SG_ 909 KAE_BLEOption "BLEOption";
CM_ SG_ 909 KAE_UWBOption "UWB Option";
CM_ SG_ 909 PWL_WinCurrentPos_FLWinPst "Window Current Position Front left Window";
CM_ SG_ 909 UINM_FrontLeftPowerReleaseReq "FrontLeftPowerReleaseReq";
CM_ SG_ 909 UINM_FrontLeftPowerReleaseFaultSt "Front Left Power Release Swtich fault state";
CM_ SG_ 909 UINM_FrontRightPowerReleaseReq "FrontRightPowerReleaseReq";
CM_ SG_ 909 UINM_FrontRightPowerReleaseFaultSt "Front Right Power Release Swtich fault state";
CM_ SG_ 909 UINM_RearLeftPowerReleaseFaultSt "RearLeftPowerReleaseReq";
CM_ SG_ 909 UINM_RearLeftPowerReleaseReq "RearLeftPowerReleaseReq";
CM_ SG_ 909 UINM_RearRightPowerReleaseFaultSt "RearRightPowerReleaseReq";
CM_ SG_ 909 UINM_RearRightPowerReleaseReq "RearRightPowerReleaseReq";
CM_ SG_ 909 BMS_BattSOCAccurate "Accurate SOC Value sent to other contoller";
CM_ SG_ 909 PWL_WinCurrentPos_RRWinPst "Rear Right Window Current Position";
CM_ SG_ 909 PWL_WinCurrentPos_RLWinPst "Rear Left Window Current Position";
CM_ SG_ 909 ACEleclocksSt "AC gun electronic lock status feedback";
CM_ SG_ 909 DSASBM_MotResp "Driver Side Active Seat Belt Motor Response";
CM_ SG_ 792 UMM_SecondRHSeatSt "Second Right Seat Sensor Status";
CM_ SG_ 792 UMM_SecondLHSeatSt "Second Left Seat Sensor Status";
CM_ SG_ 792 LCK_PowerFillerCapAngle "PowerFillerCapOpenAngle";
CM_ SG_ 792 EL_ReverseLightSt "Reverse light status";
CM_ SG_ 792 EL_ReverseLightFaultSt "Reverse light fault status";
CM_ SG_ 792 EL_RLPositionLightSt "Rear left position light status";
CM_ SG_ 792 EL_RLPositionLightFaultSt "Rear left position light fault status";
CM_ SG_ 792 EL_RRPositionLightSt "Rear right position light status";
CM_ SG_ 792 EL_RRPositionLightFaultSt "Rear right position light fault status";
CM_ SG_ 792 EL_RearFogLightSt "Rear fog light status";
CM_ SG_ 792 EL_RearFogLightFaultSt "Rear fog light fault status";
CM_ SG_ 860 VCU_7_CRC "E2E Profile 5 CRC";
CM_ SG_ 860 VCU_7_Counter "E2E Profile 5 Counter";
CM_ SG_ 860 VCU_RoadMod "Road mode for display";
CM_ SG_ 860 VCU_GearLvl "Gear lever for PEPS";
CM_ SG_ 860 VCU_VehDrvMod "Drive mode for display";
CM_ SG_ 860 VCU_VehRdySt "HEV system ready status";
CM_ SG_ 860 VCU_PlgConnSt "Charge connector  connected Status";
CM_ SG_ 860 VCU_GearLvlDisp "Gear lever for display";
CM_ SG_ 860 VCU_SuspModeReq "VCU to SDC  AVDC mode request ";
CM_ SG_ 860 VCU_SuspModeReqEnable "VCU to SDC AVDC  mode request enable status ";
CM_ SG_ 860 VCU_GearPosition "Gear lever for PEPS TCC";
CM_ SG_ 860 VCU_EcoPlusMod "EcoPlus mode is activated";
CM_ SG_ 860 ICC_RoadMod "Cross-Country Road Mode for Display";
CM_ SG_ 860 VCU_TrailerModeSt "VCU Trailer Mode Status";
CM_ SG_ 860 VCU_BMS_BattSocDisp "Average SOC of battery pack for display";
CM_ SG_ 860 VCU_VehElcConspAccumAvg "Accumulated average electric consumption to A";
CM_ SG_ 860 ICC_360Switch "Switch of 360 under off-road terrain";
CM_ SG_ 431 VCU_TargetRecpTorqVD "Status of  Target cuperation torque of generator";
CM_ SG_ 431 VCU_AccDriverOrvd "Indicating the torque demanded by the driver is higher than the torque demanded by ACC";
CM_ SG_ 431 VCU_AccDriverOrvdVD "Indicating the torque demanded by the driver is higher than the torque demanded by ACC.";
CM_ SG_ 431 VCU_TargetRecpTorq "Current target recuperation torque of generator";
CM_ SG_ 431 VCU_TargetRecpTorqFA "Target cuperation torque of generator for front axel";
CM_ SG_ 431 VCU_TargetRecpTorqRA "Target cuperation torque of generator for rear axel";
CM_ SG_ 431 VCU_TorqDriverReqFA "the driver torque request for front axel";
CM_ SG_ 431 VCU_TorqDriverReqRA "the driver torque request for rear axel or left rear wheel hub motor";
CM_ SG_ 431 VCU_VehActDrvTorqFA "Vehicle actual drive torque for front axel";
CM_ SG_ 431 VCU_VehActDrvTorqRA "Vehicle actual drive torque for  rear axel or  left rear wheel hub motor";
CM_ SG_ 431 VCU_TargetRecpTorqFAVD "Status of? Target cuperation torque of generator for front axel";
CM_ SG_ 431 VCU_TargetRecpTorqRAVD "Status of? Target cuperation torque of generator for rear axel";
CM_ SG_ 431 VCU_TorqDriverReqFAVD "Status of the driver torque request for front axel";
CM_ SG_ 431 VCU_TorqDriverReqRAVD "Status of the driver torque request for rear axel or  left rear wheel hub motor";
CM_ SG_ 431 VCU_VehActDrvTorqFAVD "Vehicle actual drive torque valid data for front axel";
CM_ SG_ 431 VCU_VehActDrvTorqRAVD "Vehicle actual drive torque valid data for rear axel or  left rear wheel hub motor";
CM_ SG_ 431 VCU_BcsDecelReq "target deceleration to BCS by AVDC";
CM_ SG_ 431 VCU_BcsDecelVD "Quality/Fault of AVDC deceleration to BCS";
CM_ SG_ 431 VCU_RecpTorqRL "Current recuperation torque of left rear wheel hub motor";
CM_ SG_ 431 VCU_RecpTorqRLVD "Status ofCurrent recuperation torque of left rear wheel hub motor";
CM_ SG_ 431 VCU_RecpTorqRR "Current recuperation torque of Right rear wheel hub motor";
CM_ SG_ 431 VCU_RecpTorqRRVD "Status ofCurrent recuperation torque of Right rear wheel hub motor";
CM_ SG_ 431 VCU_ADSNetErrorFb "ADS Net Error Feedback";
CM_ SG_ 431 VCU_NetModeResp "VCU Use Net Feedback";
CM_ SG_ 431 VCU_PwrLimDrv_kW "整车分配给驱动系统的最大驱动功率限制（电池可用功率扣除非动力系统功率后的总功率）";
CM_ SG_ 431 VCU_PwrLimRegen_kW "整车分配给驱动系统的最大回馈功率限制（电池可用功率扣除非动力系统功率后的总功率）";
CM_ SG_ 431 VCU_PwrLimDrv_kWVD "整车分配给驱动系统的最大驱动功率限制（电池可用功率扣除非动力系统功率后的总功率）";
CM_ SG_ 431 VCU_PwrLimRegen_kWVD "整车分配给驱动系统的最大回馈功率限制（电池可用功率扣除非动力系统功率后的总功率）";
CM_ SG_ 431 VCU_PtTqActvStsFL "VCU扭矩响应状态";
CM_ SG_ 431 VCU_PtTqActvStsFR "VCU扭矩响应状态";
CM_ SG_ 431 VCU_PtTqActvStsRL "VCU扭矩响应状态";
CM_ SG_ 431 VCU_PtTqActvStsRR "VCU扭矩响应状态";
CM_ SG_ 430 SRS_1_CRC_1 "E2E Profile 5 CRC";
CM_ SG_ 430 SRS_1_Counter_1 "E2E Profile 5 Counter";
CM_ SG_ 430 SRS_CrashOutputSt "To inform there's crash event happened in last 2 seconds.After 2 seconds, the signal will turn to 0(crash here means any one of the 5 status defined below)";
CM_ SG_ 430 SRS_Front_CrashOutputSt "To inform there's front crash event happened in last 2 seconds. After 2 seconds, the signal will turn to 0.";
CM_ SG_ 430 SRS_DriverSide_CrashOutputSt "To inform there's driver side crash event happened in last 2 seconds. After 2 seconds, the signal will turn to 0.(Driver side is the left side for the left-hand-drive vehicle, the right side for the right-hand-drive one. )";
CM_ SG_ 430 SRS_PassengerSide_CrashOutputSt "To inform there's passenger side crash event happened in last 2 seconds. After 2 seconds, the signal will turn to 0.(Passenger side is the right side for the left-hand-drive vehicle, the left side for the right-hand-drive one. )";
CM_ SG_ 430 SRS_Rear_CrashOutputSt "To inform there's rear crash event happened in last 2 seconds. After 2 seconds, the signal will turn to 0.";
CM_ SG_ 430 SRS_RolloverCrashOutputSt "To inform there's rollover crash event happened in last 2 seconds. After 2 seconds, the signal will turn to 0.";
CM_ SG_ 430 SRS_NearCrashOutputSt "To inform there's near crash event happened in last 2 seconds.After 2 seconds, the signal will turn to 0";
CM_ SG_ 430 SRS_YawSnsCalibSt "To indicates  yaw sensor calibration state";
CM_ SG_ 430 SRS_VehLongAccelVD "To indicate vehicle longitudinal acceleration valid state";
CM_ SG_ 430 SRS_VehLatrlAccelVD "To indicate vehicle lateral acceleration valid state";
CM_ SG_ 430 SRS_YawRateVD "To indicate yaw rate valid state";
CM_ SG_ 430 SRS_VehLongAccel "To indicate vehicle longitudinal acceleration";
CM_ SG_ 430 SRS_VehLatrlAccel "To indicate vehicle lateral acceleration";
CM_ SG_ 430 SRS_YawRate "To indicate vehicle yaw rate";
CM_ SG_ 831 VCU_ChgActiveSt "Charge active status";
CM_ SG_ 290 IPDS_FrontRadarPowerSup "Front radar power supply";
CM_ SG_ 290 IPDS_FLRadarPowerSup "Front left radar power supply";
CM_ SG_ 290 IPDS_FRRadarPowerSup "Front right radar power supply";
CM_ SG_ 290 IPDS_HDMapPowerSup "HD map power supply";
CM_ SG_ 290 IPDS_Lidar1PowerSup "Lidar1 power supply";
CM_ SG_ 290 IPDS_RearRadarPowerSup "Rear radar power supply";

BA_DEF_ BO_  "GenMsgCycleTime" INT 0 0;
BA_DEF_ BO_  "GenMsgCycleTimeFast" INT 0 0;
BA_DEF_ BO_  "GenMsgSendType" ENUM  "Periodic","Event","IfActive","POE","PA","FixedPeriodic","Event","EnabledPeriodic","NotUsed","NotUsed","EventPeriodic","NotUsed","NotUsed","NoMsgSendType";
BA_DEF_ BO_  "VFrameFormat" ENUM  "StandardCAN","ExtendedCAN","reserved","reserved","reserved","reserved","reserved","reserved","reserved","reserved","reserved","reserved","reserved","reserved","StandardCAN_FD","ExtendedCAN_FD";
BA_DEF_ BO_  "CANFD_BRS" ENUM  "0","1";
BA_DEF_ SG_  "EventCommandSignal" ENUM  "No","Yes";
BA_DEF_ SG_  "GatewayedSignals" ENUM  "No","Yes";
BA_DEF_ SG_  "GenSigInactiveValue" HEX 0 0;
BA_DEF_ SG_  "GenSigInvalidValue" HEX 0 0;
BA_DEF_ SG_  "GenSigSendType" ENUM  "Trigger","Passive","Cyclic","OnWrite","OnWriteWithRepetition","OnChange","OnChangeWithRepetition","IfActive","IfActiveWithRepetition","NoSigSendType";
BA_DEF_ SG_  "GenSigStartValue" HEX 0 0;
BA_DEF_ SG_  "GenSigTimeoutValue" HEX 0 0;
BA_DEF_ SG_  "Remark" STRING ;
BA_ "GenMsgCycleTime" BO_ 371 10;
BA_ "GenMsgCycleTimeFast" BO_ 371 0;
BA_ "GenMsgSendType" BO_ 371 0;
BA_ "VFrameFormat" BO_ 371 14;
BA_ "CANFD_BRS" BO_ 371 1;
BA_ "GenMsgCycleTime" BO_ 371 10;
BA_ "GenMsgCycleTimeFast" BO_ 371 0;
BA_ "GenMsgSendType" BO_ 371 0;
BA_ "VFrameFormat" BO_ 371 14;
BA_ "CANFD_BRS" BO_ 371 1;
BA_ "GenMsgCycleTime" BO_ 371 10;
BA_ "GenMsgCycleTimeFast" BO_ 371 0;
BA_ "GenMsgSendType" BO_ 371 0;
BA_ "VFrameFormat" BO_ 371 14;
BA_ "CANFD_BRS" BO_ 371 1;
BA_ "GenMsgCycleTime" BO_ 371 10;
BA_ "GenMsgCycleTimeFast" BO_ 371 0;
BA_ "GenMsgSendType" BO_ 371 0;
BA_ "VFrameFormat" BO_ 371 14;
BA_ "CANFD_BRS" BO_ 371 1;
BA_ "GenMsgCycleTime" BO_ 371 10;
BA_ "GenMsgCycleTimeFast" BO_ 371 0;
BA_ "GenMsgSendType" BO_ 371 0;
BA_ "VFrameFormat" BO_ 371 14;
BA_ "CANFD_BRS" BO_ 371 1;
BA_ "GenMsgCycleTime" BO_ 371 10;
BA_ "GenMsgCycleTimeFast" BO_ 371 0;
BA_ "GenMsgSendType" BO_ 371 0;
BA_ "VFrameFormat" BO_ 371 14;
BA_ "CANFD_BRS" BO_ 371 1;
BA_ "GenMsgCycleTime" BO_ 371 10;
BA_ "GenMsgCycleTimeFast" BO_ 371 0;
BA_ "GenMsgSendType" BO_ 371 0;
BA_ "VFrameFormat" BO_ 371 14;
BA_ "CANFD_BRS" BO_ 371 1;
BA_ "GenMsgCycleTime" BO_ 371 10;
BA_ "GenMsgCycleTimeFast" BO_ 371 0;
BA_ "GenMsgSendType" BO_ 371 0;
BA_ "VFrameFormat" BO_ 371 14;
BA_ "CANFD_BRS" BO_ 371 1;
BA_ "GenMsgCycleTime" BO_ 371 10;
BA_ "GenMsgCycleTimeFast" BO_ 371 0;
BA_ "GenMsgSendType" BO_ 371 0;
BA_ "VFrameFormat" BO_ 371 14;
BA_ "CANFD_BRS" BO_ 371 1;
BA_ "GenMsgCycleTime" BO_ 371 10;
BA_ "GenMsgCycleTimeFast" BO_ 371 0;
BA_ "GenMsgSendType" BO_ 371 0;
BA_ "VFrameFormat" BO_ 371 14;
BA_ "CANFD_BRS" BO_ 371 1;
BA_ "GenMsgCycleTime" BO_ 371 10;
BA_ "GenMsgCycleTimeFast" BO_ 371 0;
BA_ "GenMsgSendType" BO_ 371 0;
BA_ "VFrameFormat" BO_ 371 14;
BA_ "CANFD_BRS" BO_ 371 1;
BA_ "GenMsgCycleTime" BO_ 371 10;
BA_ "GenMsgCycleTimeFast" BO_ 371 0;
BA_ "GenMsgSendType" BO_ 371 0;
BA_ "VFrameFormat" BO_ 371 14;
BA_ "CANFD_BRS" BO_ 371 1;
BA_ "GenMsgCycleTime" BO_ 371 10;
BA_ "GenMsgCycleTimeFast" BO_ 371 0;
BA_ "GenMsgSendType" BO_ 371 0;
BA_ "VFrameFormat" BO_ 371 14;
BA_ "CANFD_BRS" BO_ 371 1;
BA_ "GenMsgCycleTime" BO_ 371 10;
BA_ "GenMsgCycleTimeFast" BO_ 371 0;
BA_ "GenMsgSendType" BO_ 371 0;
BA_ "VFrameFormat" BO_ 371 14;
BA_ "CANFD_BRS" BO_ 371 1;
BA_ "GenMsgCycleTime" BO_ 371 10;
BA_ "GenMsgCycleTimeFast" BO_ 371 0;
BA_ "GenMsgSendType" BO_ 371 0;
BA_ "VFrameFormat" BO_ 371 14;
BA_ "CANFD_BRS" BO_ 371 1;
BA_ "GenMsgCycleTime" BO_ 371 10;
BA_ "GenMsgCycleTimeFast" BO_ 371 0;
BA_ "GenMsgSendType" BO_ 371 0;
BA_ "VFrameFormat" BO_ 371 14;
BA_ "CANFD_BRS" BO_ 371 1;
BA_ "GenMsgCycleTime" BO_ 371 10;
BA_ "GenMsgCycleTimeFast" BO_ 371 0;
BA_ "GenMsgSendType" BO_ 371 0;
BA_ "VFrameFormat" BO_ 371 14;
BA_ "CANFD_BRS" BO_ 371 1;
BA_ "GenMsgCycleTime" BO_ 371 10;
BA_ "GenMsgCycleTimeFast" BO_ 371 0;
BA_ "GenMsgSendType" BO_ 371 0;
BA_ "VFrameFormat" BO_ 371 14;
BA_ "CANFD_BRS" BO_ 371 1;
BA_ "GenMsgCycleTime" BO_ 371 10;
BA_ "GenMsgCycleTimeFast" BO_ 371 0;
BA_ "GenMsgSendType" BO_ 371 0;
BA_ "VFrameFormat" BO_ 371 14;
BA_ "CANFD_BRS" BO_ 371 1;
BA_ "GenMsgCycleTime" BO_ 371 10;
BA_ "GenMsgCycleTimeFast" BO_ 371 0;
BA_ "GenMsgSendType" BO_ 371 0;
BA_ "VFrameFormat" BO_ 371 14;
BA_ "CANFD_BRS" BO_ 371 1;
BA_ "GenMsgCycleTime" BO_ 371 10;
BA_ "GenMsgCycleTimeFast" BO_ 371 0;
BA_ "GenMsgSendType" BO_ 371 0;
BA_ "VFrameFormat" BO_ 371 14;
BA_ "CANFD_BRS" BO_ 371 1;
BA_ "GenMsgCycleTime" BO_ 371 10;
BA_ "GenMsgCycleTimeFast" BO_ 371 0;
BA_ "GenMsgSendType" BO_ 371 0;
BA_ "VFrameFormat" BO_ 371 14;
BA_ "CANFD_BRS" BO_ 371 1;
BA_ "GenMsgCycleTime" BO_ 371 10;
BA_ "GenMsgCycleTimeFast" BO_ 371 0;
BA_ "GenMsgSendType" BO_ 371 0;
BA_ "VFrameFormat" BO_ 371 14;
BA_ "CANFD_BRS" BO_ 371 1;
BA_ "GenMsgCycleTime" BO_ 371 10;
BA_ "GenMsgCycleTimeFast" BO_ 371 0;
BA_ "GenMsgSendType" BO_ 371 0;
BA_ "VFrameFormat" BO_ 371 14;
BA_ "CANFD_BRS" BO_ 371 1;
BA_ "GenMsgCycleTime" BO_ 371 10;
BA_ "GenMsgCycleTimeFast" BO_ 371 0;
BA_ "GenMsgSendType" BO_ 371 0;
BA_ "VFrameFormat" BO_ 371 14;
BA_ "CANFD_BRS" BO_ 371 1;
BA_ "GenMsgCycleTime" BO_ 371 10;
BA_ "GenMsgCycleTimeFast" BO_ 371 0;
BA_ "GenMsgSendType" BO_ 371 0;
BA_ "VFrameFormat" BO_ 371 14;
BA_ "CANFD_BRS" BO_ 371 1;
BA_ "GenMsgCycleTime" BO_ 371 10;
BA_ "GenMsgCycleTimeFast" BO_ 371 0;
BA_ "GenMsgSendType" BO_ 371 0;
BA_ "VFrameFormat" BO_ 371 14;
BA_ "CANFD_BRS" BO_ 371 1;
BA_ "GenMsgCycleTime" BO_ 371 10;
BA_ "GenMsgCycleTimeFast" BO_ 371 0;
BA_ "GenMsgSendType" BO_ 371 0;
BA_ "VFrameFormat" BO_ 371 14;
BA_ "CANFD_BRS" BO_ 371 1;
BA_ "GenMsgCycleTime" BO_ 371 10;
BA_ "GenMsgCycleTimeFast" BO_ 371 0;
BA_ "GenMsgSendType" BO_ 371 0;
BA_ "VFrameFormat" BO_ 371 14;
BA_ "CANFD_BRS" BO_ 371 1;
BA_ "GenMsgCycleTime" BO_ 371 10;
BA_ "GenMsgCycleTimeFast" BO_ 371 0;
BA_ "GenMsgSendType" BO_ 371 0;
BA_ "VFrameFormat" BO_ 371 14;
BA_ "CANFD_BRS" BO_ 371 1;
BA_ "GenMsgCycleTime" BO_ 371 10;
BA_ "GenMsgCycleTimeFast" BO_ 371 0;
BA_ "GenMsgSendType" BO_ 371 0;
BA_ "VFrameFormat" BO_ 371 14;
BA_ "CANFD_BRS" BO_ 371 1;
BA_ "GenMsgCycleTime" BO_ 371 10;
BA_ "GenMsgCycleTimeFast" BO_ 371 0;
BA_ "GenMsgSendType" BO_ 371 0;
BA_ "VFrameFormat" BO_ 371 14;
BA_ "CANFD_BRS" BO_ 371 1;
BA_ "GenMsgCycleTime" BO_ 371 10;
BA_ "GenMsgCycleTimeFast" BO_ 371 0;
BA_ "GenMsgSendType" BO_ 371 0;
BA_ "VFrameFormat" BO_ 371 14;
BA_ "CANFD_BRS" BO_ 371 1;
BA_ "GenMsgCycleTime" BO_ 371 10;
BA_ "GenMsgCycleTimeFast" BO_ 371 0;
BA_ "GenMsgSendType" BO_ 371 0;
BA_ "VFrameFormat" BO_ 371 14;
BA_ "CANFD_BRS" BO_ 371 1;
BA_ "GenMsgCycleTime" BO_ 371 10;
BA_ "GenMsgCycleTimeFast" BO_ 371 0;
BA_ "GenMsgSendType" BO_ 371 0;
BA_ "VFrameFormat" BO_ 371 14;
BA_ "CANFD_BRS" BO_ 371 1;
BA_ "GenMsgCycleTime" BO_ 371 10;
BA_ "GenMsgCycleTimeFast" BO_ 371 0;
BA_ "GenMsgSendType" BO_ 371 0;
BA_ "VFrameFormat" BO_ 371 14;
BA_ "CANFD_BRS" BO_ 371 1;
BA_ "GenMsgCycleTime" BO_ 371 10;
BA_ "GenMsgCycleTimeFast" BO_ 371 0;
BA_ "GenMsgSendType" BO_ 371 0;
BA_ "VFrameFormat" BO_ 371 14;
BA_ "CANFD_BRS" BO_ 371 1;
BA_ "GenMsgCycleTime" BO_ 371 10;
BA_ "GenMsgCycleTimeFast" BO_ 371 0;
BA_ "GenMsgSendType" BO_ 371 0;
BA_ "VFrameFormat" BO_ 371 14;
BA_ "CANFD_BRS" BO_ 371 1;
BA_ "GenMsgCycleTime" BO_ 371 10;
BA_ "GenMsgCycleTimeFast" BO_ 371 0;
BA_ "GenMsgSendType" BO_ 371 0;
BA_ "VFrameFormat" BO_ 371 14;
BA_ "CANFD_BRS" BO_ 371 1;
BA_ "GenMsgCycleTime" BO_ 371 10;
BA_ "GenMsgCycleTimeFast" BO_ 371 0;
BA_ "GenMsgSendType" BO_ 371 0;
BA_ "VFrameFormat" BO_ 371 14;
BA_ "CANFD_BRS" BO_ 371 1;
BA_ "GenMsgCycleTime" BO_ 371 10;
BA_ "GenMsgCycleTimeFast" BO_ 371 0;
BA_ "GenMsgSendType" BO_ 371 0;
BA_ "VFrameFormat" BO_ 371 14;
BA_ "CANFD_BRS" BO_ 371 1;
BA_ "GenMsgCycleTime" BO_ 371 10;
BA_ "GenMsgCycleTimeFast" BO_ 371 0;
BA_ "GenMsgSendType" BO_ 371 0;
BA_ "VFrameFormat" BO_ 371 14;
BA_ "CANFD_BRS" BO_ 371 1;
BA_ "GenMsgCycleTime" BO_ 371 10;
BA_ "GenMsgCycleTimeFast" BO_ 371 0;
BA_ "GenMsgSendType" BO_ 371 0;
BA_ "VFrameFormat" BO_ 371 14;
BA_ "CANFD_BRS" BO_ 371 1;
BA_ "GenMsgCycleTime" BO_ 371 10;
BA_ "GenMsgCycleTimeFast" BO_ 371 0;
BA_ "GenMsgSendType" BO_ 371 0;
BA_ "VFrameFormat" BO_ 371 14;
BA_ "CANFD_BRS" BO_ 371 1;
BA_ "GenMsgCycleTime" BO_ 371 10;
BA_ "GenMsgCycleTimeFast" BO_ 371 0;
BA_ "GenMsgSendType" BO_ 371 0;
BA_ "VFrameFormat" BO_ 371 14;
BA_ "CANFD_BRS" BO_ 371 1;
BA_ "GenMsgCycleTime" BO_ 371 10;
BA_ "GenMsgCycleTimeFast" BO_ 371 0;
BA_ "GenMsgSendType" BO_ 371 0;
BA_ "VFrameFormat" BO_ 371 14;
BA_ "CANFD_BRS" BO_ 371 1;
BA_ "GenMsgCycleTime" BO_ 371 10;
BA_ "GenMsgCycleTimeFast" BO_ 371 0;
BA_ "GenMsgSendType" BO_ 371 0;
BA_ "VFrameFormat" BO_ 371 14;
BA_ "CANFD_BRS" BO_ 371 1;
BA_ "GenMsgCycleTime" BO_ 371 10;
BA_ "GenMsgCycleTimeFast" BO_ 371 0;
BA_ "GenMsgSendType" BO_ 371 0;
BA_ "VFrameFormat" BO_ 371 14;
BA_ "CANFD_BRS" BO_ 371 1;
BA_ "GenMsgCycleTime" BO_ 1359 200;
BA_ "GenMsgCycleTimeFast" BO_ 1359 0;
BA_ "GenMsgSendType" BO_ 1359 0;
BA_ "VFrameFormat" BO_ 1359 0;
BA_ "CANFD_BRS" BO_ 1359 1;
BA_ "GenMsgCycleTime" BO_ 1359 200;
BA_ "GenMsgCycleTimeFast" BO_ 1359 0;
BA_ "GenMsgSendType" BO_ 1359 0;
BA_ "VFrameFormat" BO_ 1359 0;
BA_ "CANFD_BRS" BO_ 1359 1;
BA_ "GenMsgCycleTime" BO_ 1359 200;
BA_ "GenMsgCycleTimeFast" BO_ 1359 0;
BA_ "GenMsgSendType" BO_ 1359 0;
BA_ "VFrameFormat" BO_ 1359 0;
BA_ "CANFD_BRS" BO_ 1359 1;
BA_ "GenMsgCycleTime" BO_ 1359 200;
BA_ "GenMsgCycleTimeFast" BO_ 1359 0;
BA_ "GenMsgSendType" BO_ 1359 0;
BA_ "VFrameFormat" BO_ 1359 0;
BA_ "CANFD_BRS" BO_ 1359 1;
BA_ "GenMsgCycleTime" BO_ 1359 200;
BA_ "GenMsgCycleTimeFast" BO_ 1359 0;
BA_ "GenMsgSendType" BO_ 1359 0;
BA_ "VFrameFormat" BO_ 1359 0;
BA_ "CANFD_BRS" BO_ 1359 1;
BA_ "GenMsgCycleTime" BO_ 1359 200;
BA_ "GenMsgCycleTimeFast" BO_ 1359 0;
BA_ "GenMsgSendType" BO_ 1359 0;
BA_ "VFrameFormat" BO_ 1359 0;
BA_ "CANFD_BRS" BO_ 1359 1;
BA_ "GenMsgCycleTime" BO_ 905 100;
BA_ "GenMsgCycleTimeFast" BO_ 905 0;
BA_ "GenMsgSendType" BO_ 905 0;
BA_ "VFrameFormat" BO_ 905 14;
BA_ "CANFD_BRS" BO_ 905 1;
BA_ "GenMsgCycleTime" BO_ 905 100;
BA_ "GenMsgCycleTimeFast" BO_ 905 0;
BA_ "GenMsgSendType" BO_ 905 0;
BA_ "VFrameFormat" BO_ 905 14;
BA_ "CANFD_BRS" BO_ 905 1;
BA_ "GenMsgCycleTime" BO_ 905 100;
BA_ "GenMsgCycleTimeFast" BO_ 905 0;
BA_ "GenMsgSendType" BO_ 905 0;
BA_ "VFrameFormat" BO_ 905 14;
BA_ "CANFD_BRS" BO_ 905 1;
BA_ "GenMsgCycleTime" BO_ 905 100;
BA_ "GenMsgCycleTimeFast" BO_ 905 0;
BA_ "GenMsgSendType" BO_ 905 0;
BA_ "VFrameFormat" BO_ 905 14;
BA_ "CANFD_BRS" BO_ 905 1;
BA_ "GenMsgCycleTime" BO_ 905 100;
BA_ "GenMsgCycleTimeFast" BO_ 905 0;
BA_ "GenMsgSendType" BO_ 905 0;
BA_ "VFrameFormat" BO_ 905 14;
BA_ "CANFD_BRS" BO_ 905 1;
BA_ "GenMsgCycleTime" BO_ 905 100;
BA_ "GenMsgCycleTimeFast" BO_ 905 0;
BA_ "GenMsgSendType" BO_ 905 0;
BA_ "VFrameFormat" BO_ 905 14;
BA_ "CANFD_BRS" BO_ 905 1;
BA_ "GenMsgCycleTime" BO_ 516 20;
BA_ "GenMsgCycleTimeFast" BO_ 516 0;
BA_ "GenMsgSendType" BO_ 516 0;
BA_ "VFrameFormat" BO_ 516 14;
BA_ "CANFD_BRS" BO_ 516 1;
BA_ "GenMsgCycleTime" BO_ 516 20;
BA_ "GenMsgCycleTimeFast" BO_ 516 0;
BA_ "GenMsgSendType" BO_ 516 0;
BA_ "VFrameFormat" BO_ 516 14;
BA_ "CANFD_BRS" BO_ 516 1;
BA_ "GenMsgCycleTime" BO_ 516 20;
BA_ "GenMsgCycleTimeFast" BO_ 516 0;
BA_ "GenMsgSendType" BO_ 516 0;
BA_ "VFrameFormat" BO_ 516 14;
BA_ "CANFD_BRS" BO_ 516 1;
BA_ "GenMsgCycleTime" BO_ 516 20;
BA_ "GenMsgCycleTimeFast" BO_ 516 0;
BA_ "GenMsgSendType" BO_ 516 0;
BA_ "VFrameFormat" BO_ 516 14;
BA_ "CANFD_BRS" BO_ 516 1;
BA_ "GenMsgCycleTime" BO_ 516 20;
BA_ "GenMsgCycleTimeFast" BO_ 516 0;
BA_ "GenMsgSendType" BO_ 516 0;
BA_ "VFrameFormat" BO_ 516 14;
BA_ "CANFD_BRS" BO_ 516 1;
BA_ "GenMsgCycleTime" BO_ 516 20;
BA_ "GenMsgCycleTimeFast" BO_ 516 0;
BA_ "GenMsgSendType" BO_ 516 0;
BA_ "VFrameFormat" BO_ 516 14;
BA_ "CANFD_BRS" BO_ 516 1;
BA_ "GenMsgCycleTime" BO_ 516 20;
BA_ "GenMsgCycleTimeFast" BO_ 516 0;
BA_ "GenMsgSendType" BO_ 516 0;
BA_ "VFrameFormat" BO_ 516 14;
BA_ "CANFD_BRS" BO_ 516 1;
BA_ "GenMsgCycleTime" BO_ 516 20;
BA_ "GenMsgCycleTimeFast" BO_ 516 0;
BA_ "GenMsgSendType" BO_ 516 0;
BA_ "VFrameFormat" BO_ 516 14;
BA_ "CANFD_BRS" BO_ 516 1;
BA_ "GenMsgCycleTime" BO_ 516 20;
BA_ "GenMsgCycleTimeFast" BO_ 516 0;
BA_ "GenMsgSendType" BO_ 516 0;
BA_ "VFrameFormat" BO_ 516 14;
BA_ "CANFD_BRS" BO_ 516 1;
BA_ "GenMsgCycleTime" BO_ 516 20;
BA_ "GenMsgCycleTimeFast" BO_ 516 0;
BA_ "GenMsgSendType" BO_ 516 0;
BA_ "VFrameFormat" BO_ 516 14;
BA_ "CANFD_BRS" BO_ 516 1;
BA_ "GenMsgCycleTime" BO_ 516 20;
BA_ "GenMsgCycleTimeFast" BO_ 516 0;
BA_ "GenMsgSendType" BO_ 516 0;
BA_ "VFrameFormat" BO_ 516 14;
BA_ "CANFD_BRS" BO_ 516 1;
BA_ "GenMsgCycleTime" BO_ 516 20;
BA_ "GenMsgCycleTimeFast" BO_ 516 0;
BA_ "GenMsgSendType" BO_ 516 0;
BA_ "VFrameFormat" BO_ 516 14;
BA_ "CANFD_BRS" BO_ 516 1;
BA_ "GenMsgCycleTime" BO_ 516 20;
BA_ "GenMsgCycleTimeFast" BO_ 516 0;
BA_ "GenMsgSendType" BO_ 516 0;
BA_ "VFrameFormat" BO_ 516 14;
BA_ "CANFD_BRS" BO_ 516 1;
BA_ "GenMsgCycleTime" BO_ 516 20;
BA_ "GenMsgCycleTimeFast" BO_ 516 0;
BA_ "GenMsgSendType" BO_ 516 0;
BA_ "VFrameFormat" BO_ 516 14;
BA_ "CANFD_BRS" BO_ 516 1;
BA_ "GenMsgCycleTime" BO_ 516 20;
BA_ "GenMsgCycleTimeFast" BO_ 516 0;
BA_ "GenMsgSendType" BO_ 516 0;
BA_ "VFrameFormat" BO_ 516 14;
BA_ "CANFD_BRS" BO_ 516 1;
BA_ "GenMsgCycleTime" BO_ 516 20;
BA_ "GenMsgCycleTimeFast" BO_ 516 0;
BA_ "GenMsgSendType" BO_ 516 0;
BA_ "VFrameFormat" BO_ 516 14;
BA_ "CANFD_BRS" BO_ 516 1;
BA_ "GenMsgCycleTime" BO_ 516 20;
BA_ "GenMsgCycleTimeFast" BO_ 516 0;
BA_ "GenMsgSendType" BO_ 516 0;
BA_ "VFrameFormat" BO_ 516 14;
BA_ "CANFD_BRS" BO_ 516 1;
BA_ "GenMsgCycleTime" BO_ 516 20;
BA_ "GenMsgCycleTimeFast" BO_ 516 0;
BA_ "GenMsgSendType" BO_ 516 0;
BA_ "VFrameFormat" BO_ 516 14;
BA_ "CANFD_BRS" BO_ 516 1;
BA_ "GenMsgCycleTime" BO_ 516 20;
BA_ "GenMsgCycleTimeFast" BO_ 516 0;
BA_ "GenMsgSendType" BO_ 516 0;
BA_ "VFrameFormat" BO_ 516 14;
BA_ "CANFD_BRS" BO_ 516 1;
BA_ "GenMsgCycleTime" BO_ 516 20;
BA_ "GenMsgCycleTimeFast" BO_ 516 0;
BA_ "GenMsgSendType" BO_ 516 0;
BA_ "VFrameFormat" BO_ 516 14;
BA_ "CANFD_BRS" BO_ 516 1;
BA_ "GenMsgCycleTime" BO_ 516 20;
BA_ "GenMsgCycleTimeFast" BO_ 516 0;
BA_ "GenMsgSendType" BO_ 516 0;
BA_ "VFrameFormat" BO_ 516 14;
BA_ "CANFD_BRS" BO_ 516 1;
BA_ "GenMsgCycleTime" BO_ 516 20;
BA_ "GenMsgCycleTimeFast" BO_ 516 0;
BA_ "GenMsgSendType" BO_ 516 0;
BA_ "VFrameFormat" BO_ 516 14;
BA_ "CANFD_BRS" BO_ 516 1;
BA_ "GenMsgCycleTime" BO_ 516 20;
BA_ "GenMsgCycleTimeFast" BO_ 516 0;
BA_ "GenMsgSendType" BO_ 516 0;
BA_ "VFrameFormat" BO_ 516 14;
BA_ "CANFD_BRS" BO_ 516 1;
BA_ "GenMsgCycleTime" BO_ 516 20;
BA_ "GenMsgCycleTimeFast" BO_ 516 0;
BA_ "GenMsgSendType" BO_ 516 0;
BA_ "VFrameFormat" BO_ 516 14;
BA_ "CANFD_BRS" BO_ 516 1;
BA_ "GenMsgCycleTime" BO_ 516 20;
BA_ "GenMsgCycleTimeFast" BO_ 516 0;
BA_ "GenMsgSendType" BO_ 516 0;
BA_ "VFrameFormat" BO_ 516 14;
BA_ "CANFD_BRS" BO_ 516 1;
BA_ "GenMsgCycleTime" BO_ 516 20;
BA_ "GenMsgCycleTimeFast" BO_ 516 0;
BA_ "GenMsgSendType" BO_ 516 0;
BA_ "VFrameFormat" BO_ 516 14;
BA_ "CANFD_BRS" BO_ 516 1;
BA_ "GenMsgCycleTime" BO_ 516 20;
BA_ "GenMsgCycleTimeFast" BO_ 516 0;
BA_ "GenMsgSendType" BO_ 516 0;
BA_ "VFrameFormat" BO_ 516 14;
BA_ "CANFD_BRS" BO_ 516 1;
BA_ "GenMsgCycleTime" BO_ 516 20;
BA_ "GenMsgCycleTimeFast" BO_ 516 0;
BA_ "GenMsgSendType" BO_ 516 0;
BA_ "VFrameFormat" BO_ 516 14;
BA_ "CANFD_BRS" BO_ 516 1;
BA_ "GenMsgCycleTime" BO_ 516 20;
BA_ "GenMsgCycleTimeFast" BO_ 516 0;
BA_ "GenMsgSendType" BO_ 516 0;
BA_ "VFrameFormat" BO_ 516 14;
BA_ "CANFD_BRS" BO_ 516 1;
BA_ "GenMsgCycleTime" BO_ 516 20;
BA_ "GenMsgCycleTimeFast" BO_ 516 0;
BA_ "GenMsgSendType" BO_ 516 0;
BA_ "VFrameFormat" BO_ 516 14;
BA_ "CANFD_BRS" BO_ 516 1;
BA_ "GenMsgCycleTime" BO_ 516 20;
BA_ "GenMsgCycleTimeFast" BO_ 516 0;
BA_ "GenMsgSendType" BO_ 516 0;
BA_ "VFrameFormat" BO_ 516 14;
BA_ "CANFD_BRS" BO_ 516 1;
BA_ "GenMsgCycleTime" BO_ 516 20;
BA_ "GenMsgCycleTimeFast" BO_ 516 0;
BA_ "GenMsgSendType" BO_ 516 0;
BA_ "VFrameFormat" BO_ 516 14;
BA_ "CANFD_BRS" BO_ 516 1;
BA_ "GenMsgCycleTime" BO_ 516 20;
BA_ "GenMsgCycleTimeFast" BO_ 516 0;
BA_ "GenMsgSendType" BO_ 516 0;
BA_ "VFrameFormat" BO_ 516 14;
BA_ "CANFD_BRS" BO_ 516 1;
BA_ "GenMsgCycleTime" BO_ 909 100;
BA_ "GenMsgCycleTimeFast" BO_ 909 0;
BA_ "GenMsgSendType" BO_ 909 0;
BA_ "VFrameFormat" BO_ 909 14;
BA_ "CANFD_BRS" BO_ 909 1;
BA_ "GenMsgCycleTime" BO_ 909 100;
BA_ "GenMsgCycleTimeFast" BO_ 909 0;
BA_ "GenMsgSendType" BO_ 909 0;
BA_ "VFrameFormat" BO_ 909 14;
BA_ "CANFD_BRS" BO_ 909 1;
BA_ "GenMsgCycleTime" BO_ 909 100;
BA_ "GenMsgCycleTimeFast" BO_ 909 0;
BA_ "GenMsgSendType" BO_ 909 0;
BA_ "VFrameFormat" BO_ 909 14;
BA_ "CANFD_BRS" BO_ 909 1;
BA_ "GenMsgCycleTime" BO_ 909 100;
BA_ "GenMsgCycleTimeFast" BO_ 909 0;
BA_ "GenMsgSendType" BO_ 909 0;
BA_ "VFrameFormat" BO_ 909 14;
BA_ "CANFD_BRS" BO_ 909 1;
BA_ "GenMsgCycleTime" BO_ 909 100;
BA_ "GenMsgCycleTimeFast" BO_ 909 0;
BA_ "GenMsgSendType" BO_ 909 0;
BA_ "VFrameFormat" BO_ 909 14;
BA_ "CANFD_BRS" BO_ 909 1;
BA_ "GenMsgCycleTime" BO_ 909 100;
BA_ "GenMsgCycleTimeFast" BO_ 909 0;
BA_ "GenMsgSendType" BO_ 909 0;
BA_ "VFrameFormat" BO_ 909 14;
BA_ "CANFD_BRS" BO_ 909 1;
BA_ "GenMsgCycleTime" BO_ 909 100;
BA_ "GenMsgCycleTimeFast" BO_ 909 0;
BA_ "GenMsgSendType" BO_ 909 0;
BA_ "VFrameFormat" BO_ 909 14;
BA_ "CANFD_BRS" BO_ 909 1;
BA_ "GenMsgCycleTime" BO_ 909 100;
BA_ "GenMsgCycleTimeFast" BO_ 909 0;
BA_ "GenMsgSendType" BO_ 909 0;
BA_ "VFrameFormat" BO_ 909 14;
BA_ "CANFD_BRS" BO_ 909 1;
BA_ "GenMsgCycleTime" BO_ 909 100;
BA_ "GenMsgCycleTimeFast" BO_ 909 0;
BA_ "GenMsgSendType" BO_ 909 0;
BA_ "VFrameFormat" BO_ 909 14;
BA_ "CANFD_BRS" BO_ 909 1;
BA_ "GenMsgCycleTime" BO_ 909 100;
BA_ "GenMsgCycleTimeFast" BO_ 909 0;
BA_ "GenMsgSendType" BO_ 909 0;
BA_ "VFrameFormat" BO_ 909 14;
BA_ "CANFD_BRS" BO_ 909 1;
BA_ "GenMsgCycleTime" BO_ 909 100;
BA_ "GenMsgCycleTimeFast" BO_ 909 0;
BA_ "GenMsgSendType" BO_ 909 0;
BA_ "VFrameFormat" BO_ 909 14;
BA_ "CANFD_BRS" BO_ 909 1;
BA_ "GenMsgCycleTime" BO_ 909 100;
BA_ "GenMsgCycleTimeFast" BO_ 909 0;
BA_ "GenMsgSendType" BO_ 909 0;
BA_ "VFrameFormat" BO_ 909 14;
BA_ "CANFD_BRS" BO_ 909 1;
BA_ "GenMsgCycleTime" BO_ 909 100;
BA_ "GenMsgCycleTimeFast" BO_ 909 0;
BA_ "GenMsgSendType" BO_ 909 0;
BA_ "VFrameFormat" BO_ 909 14;
BA_ "CANFD_BRS" BO_ 909 1;
BA_ "GenMsgCycleTime" BO_ 909 100;
BA_ "GenMsgCycleTimeFast" BO_ 909 0;
BA_ "GenMsgSendType" BO_ 909 0;
BA_ "VFrameFormat" BO_ 909 14;
BA_ "CANFD_BRS" BO_ 909 1;
BA_ "GenMsgCycleTime" BO_ 909 100;
BA_ "GenMsgCycleTimeFast" BO_ 909 0;
BA_ "GenMsgSendType" BO_ 909 0;
BA_ "VFrameFormat" BO_ 909 14;
BA_ "CANFD_BRS" BO_ 909 1;
BA_ "GenMsgCycleTime" BO_ 909 100;
BA_ "GenMsgCycleTimeFast" BO_ 909 0;
BA_ "GenMsgSendType" BO_ 909 0;
BA_ "VFrameFormat" BO_ 909 14;
BA_ "CANFD_BRS" BO_ 909 1;
BA_ "GenMsgCycleTime" BO_ 909 100;
BA_ "GenMsgCycleTimeFast" BO_ 909 0;
BA_ "GenMsgSendType" BO_ 909 0;
BA_ "VFrameFormat" BO_ 909 14;
BA_ "CANFD_BRS" BO_ 909 1;
BA_ "GenMsgCycleTime" BO_ 909 100;
BA_ "GenMsgCycleTimeFast" BO_ 909 0;
BA_ "GenMsgSendType" BO_ 909 0;
BA_ "VFrameFormat" BO_ 909 14;
BA_ "CANFD_BRS" BO_ 909 1;
BA_ "GenMsgCycleTime" BO_ 909 100;
BA_ "GenMsgCycleTimeFast" BO_ 909 0;
BA_ "GenMsgSendType" BO_ 909 0;
BA_ "VFrameFormat" BO_ 909 14;
BA_ "CANFD_BRS" BO_ 909 1;
BA_ "GenMsgCycleTime" BO_ 909 100;
BA_ "GenMsgCycleTimeFast" BO_ 909 0;
BA_ "GenMsgSendType" BO_ 909 0;
BA_ "VFrameFormat" BO_ 909 14;
BA_ "CANFD_BRS" BO_ 909 1;
BA_ "GenMsgCycleTime" BO_ 909 100;
BA_ "GenMsgCycleTimeFast" BO_ 909 0;
BA_ "GenMsgSendType" BO_ 909 0;
BA_ "VFrameFormat" BO_ 909 14;
BA_ "CANFD_BRS" BO_ 909 1;
BA_ "GenMsgCycleTime" BO_ 909 100;
BA_ "GenMsgCycleTimeFast" BO_ 909 0;
BA_ "GenMsgSendType" BO_ 909 0;
BA_ "VFrameFormat" BO_ 909 14;
BA_ "CANFD_BRS" BO_ 909 1;
BA_ "GenMsgCycleTime" BO_ 909 100;
BA_ "GenMsgCycleTimeFast" BO_ 909 0;
BA_ "GenMsgSendType" BO_ 909 0;
BA_ "VFrameFormat" BO_ 909 14;
BA_ "CANFD_BRS" BO_ 909 1;
BA_ "GenMsgCycleTime" BO_ 909 100;
BA_ "GenMsgCycleTimeFast" BO_ 909 0;
BA_ "GenMsgSendType" BO_ 909 0;
BA_ "VFrameFormat" BO_ 909 14;
BA_ "CANFD_BRS" BO_ 909 1;
BA_ "GenMsgCycleTime" BO_ 909 100;
BA_ "GenMsgCycleTimeFast" BO_ 909 0;
BA_ "GenMsgSendType" BO_ 909 0;
BA_ "VFrameFormat" BO_ 909 14;
BA_ "CANFD_BRS" BO_ 909 1;
BA_ "GenMsgCycleTime" BO_ 909 100;
BA_ "GenMsgCycleTimeFast" BO_ 909 0;
BA_ "GenMsgSendType" BO_ 909 0;
BA_ "VFrameFormat" BO_ 909 14;
BA_ "CANFD_BRS" BO_ 909 1;
BA_ "GenMsgCycleTime" BO_ 909 100;
BA_ "GenMsgCycleTimeFast" BO_ 909 0;
BA_ "GenMsgSendType" BO_ 909 0;
BA_ "VFrameFormat" BO_ 909 14;
BA_ "CANFD_BRS" BO_ 909 1;
BA_ "GenMsgCycleTime" BO_ 909 100;
BA_ "GenMsgCycleTimeFast" BO_ 909 0;
BA_ "GenMsgSendType" BO_ 909 0;
BA_ "VFrameFormat" BO_ 909 14;
BA_ "CANFD_BRS" BO_ 909 1;
BA_ "GenMsgCycleTime" BO_ 909 100;
BA_ "GenMsgCycleTimeFast" BO_ 909 0;
BA_ "GenMsgSendType" BO_ 909 0;
BA_ "VFrameFormat" BO_ 909 14;
BA_ "CANFD_BRS" BO_ 909 1;
BA_ "GenMsgCycleTime" BO_ 909 100;
BA_ "GenMsgCycleTimeFast" BO_ 909 0;
BA_ "GenMsgSendType" BO_ 909 0;
BA_ "VFrameFormat" BO_ 909 14;
BA_ "CANFD_BRS" BO_ 909 1;
BA_ "GenMsgCycleTime" BO_ 909 100;
BA_ "GenMsgCycleTimeFast" BO_ 909 0;
BA_ "GenMsgSendType" BO_ 909 0;
BA_ "VFrameFormat" BO_ 909 14;
BA_ "CANFD_BRS" BO_ 909 1;
BA_ "GenMsgCycleTime" BO_ 909 100;
BA_ "GenMsgCycleTimeFast" BO_ 909 0;
BA_ "GenMsgSendType" BO_ 909 0;
BA_ "VFrameFormat" BO_ 909 14;
BA_ "CANFD_BRS" BO_ 909 1;
BA_ "GenMsgCycleTime" BO_ 909 100;
BA_ "GenMsgCycleTimeFast" BO_ 909 0;
BA_ "GenMsgSendType" BO_ 909 0;
BA_ "VFrameFormat" BO_ 909 14;
BA_ "CANFD_BRS" BO_ 909 1;
BA_ "GenMsgCycleTime" BO_ 909 100;
BA_ "GenMsgCycleTimeFast" BO_ 909 0;
BA_ "GenMsgSendType" BO_ 909 0;
BA_ "VFrameFormat" BO_ 909 14;
BA_ "CANFD_BRS" BO_ 909 1;
BA_ "GenMsgCycleTime" BO_ 909 100;
BA_ "GenMsgCycleTimeFast" BO_ 909 0;
BA_ "GenMsgSendType" BO_ 909 0;
BA_ "VFrameFormat" BO_ 909 14;
BA_ "CANFD_BRS" BO_ 909 1;
BA_ "GenMsgCycleTime" BO_ 909 100;
BA_ "GenMsgCycleTimeFast" BO_ 909 0;
BA_ "GenMsgSendType" BO_ 909 0;
BA_ "VFrameFormat" BO_ 909 14;
BA_ "CANFD_BRS" BO_ 909 1;
BA_ "GenMsgCycleTime" BO_ 909 100;
BA_ "GenMsgCycleTimeFast" BO_ 909 0;
BA_ "GenMsgSendType" BO_ 909 0;
BA_ "VFrameFormat" BO_ 909 14;
BA_ "CANFD_BRS" BO_ 909 1;
BA_ "GenMsgCycleTime" BO_ 909 100;
BA_ "GenMsgCycleTimeFast" BO_ 909 0;
BA_ "GenMsgSendType" BO_ 909 0;
BA_ "VFrameFormat" BO_ 909 14;
BA_ "CANFD_BRS" BO_ 909 1;
BA_ "GenMsgCycleTime" BO_ 909 100;
BA_ "GenMsgCycleTimeFast" BO_ 909 0;
BA_ "GenMsgSendType" BO_ 909 0;
BA_ "VFrameFormat" BO_ 909 14;
BA_ "CANFD_BRS" BO_ 909 1;
BA_ "GenMsgCycleTime" BO_ 909 100;
BA_ "GenMsgCycleTimeFast" BO_ 909 0;
BA_ "GenMsgSendType" BO_ 909 0;
BA_ "VFrameFormat" BO_ 909 14;
BA_ "CANFD_BRS" BO_ 909 1;
BA_ "GenMsgCycleTime" BO_ 909 100;
BA_ "GenMsgCycleTimeFast" BO_ 909 0;
BA_ "GenMsgSendType" BO_ 909 0;
BA_ "VFrameFormat" BO_ 909 14;
BA_ "CANFD_BRS" BO_ 909 1;
BA_ "GenMsgCycleTime" BO_ 909 100;
BA_ "GenMsgCycleTimeFast" BO_ 909 0;
BA_ "GenMsgSendType" BO_ 909 0;
BA_ "VFrameFormat" BO_ 909 14;
BA_ "CANFD_BRS" BO_ 909 1;
BA_ "GenMsgCycleTime" BO_ 909 100;
BA_ "GenMsgCycleTimeFast" BO_ 909 0;
BA_ "GenMsgSendType" BO_ 909 0;
BA_ "VFrameFormat" BO_ 909 14;
BA_ "CANFD_BRS" BO_ 909 1;
BA_ "GenMsgCycleTime" BO_ 909 100;
BA_ "GenMsgCycleTimeFast" BO_ 909 0;
BA_ "GenMsgSendType" BO_ 909 0;
BA_ "VFrameFormat" BO_ 909 14;
BA_ "CANFD_BRS" BO_ 909 1;
BA_ "GenMsgCycleTime" BO_ 909 100;
BA_ "GenMsgCycleTimeFast" BO_ 909 0;
BA_ "GenMsgSendType" BO_ 909 0;
BA_ "VFrameFormat" BO_ 909 14;
BA_ "CANFD_BRS" BO_ 909 1;
BA_ "GenMsgCycleTime" BO_ 909 100;
BA_ "GenMsgCycleTimeFast" BO_ 909 0;
BA_ "GenMsgSendType" BO_ 909 0;
BA_ "VFrameFormat" BO_ 909 14;
BA_ "CANFD_BRS" BO_ 909 1;
BA_ "GenMsgCycleTime" BO_ 909 100;
BA_ "GenMsgCycleTimeFast" BO_ 909 0;
BA_ "GenMsgSendType" BO_ 909 0;
BA_ "VFrameFormat" BO_ 909 14;
BA_ "CANFD_BRS" BO_ 909 1;
BA_ "GenMsgCycleTime" BO_ 792 100;
BA_ "GenMsgCycleTimeFast" BO_ 792 0;
BA_ "GenMsgSendType" BO_ 792 0;
BA_ "VFrameFormat" BO_ 792 14;
BA_ "CANFD_BRS" BO_ 792 1;
BA_ "GenMsgCycleTime" BO_ 792 100;
BA_ "GenMsgCycleTimeFast" BO_ 792 0;
BA_ "GenMsgSendType" BO_ 792 0;
BA_ "VFrameFormat" BO_ 792 14;
BA_ "CANFD_BRS" BO_ 792 1;
BA_ "GenMsgCycleTime" BO_ 792 100;
BA_ "GenMsgCycleTimeFast" BO_ 792 0;
BA_ "GenMsgSendType" BO_ 792 0;
BA_ "VFrameFormat" BO_ 792 14;
BA_ "CANFD_BRS" BO_ 792 1;
BA_ "GenMsgCycleTime" BO_ 792 100;
BA_ "GenMsgCycleTimeFast" BO_ 792 0;
BA_ "GenMsgSendType" BO_ 792 0;
BA_ "VFrameFormat" BO_ 792 14;
BA_ "CANFD_BRS" BO_ 792 1;
BA_ "GenMsgCycleTime" BO_ 792 100;
BA_ "GenMsgCycleTimeFast" BO_ 792 0;
BA_ "GenMsgSendType" BO_ 792 0;
BA_ "VFrameFormat" BO_ 792 14;
BA_ "CANFD_BRS" BO_ 792 1;
BA_ "GenMsgCycleTime" BO_ 792 100;
BA_ "GenMsgCycleTimeFast" BO_ 792 0;
BA_ "GenMsgSendType" BO_ 792 0;
BA_ "VFrameFormat" BO_ 792 14;
BA_ "CANFD_BRS" BO_ 792 1;
BA_ "GenMsgCycleTime" BO_ 792 100;
BA_ "GenMsgCycleTimeFast" BO_ 792 0;
BA_ "GenMsgSendType" BO_ 792 0;
BA_ "VFrameFormat" BO_ 792 14;
BA_ "CANFD_BRS" BO_ 792 1;
BA_ "GenMsgCycleTime" BO_ 792 100;
BA_ "GenMsgCycleTimeFast" BO_ 792 0;
BA_ "GenMsgSendType" BO_ 792 0;
BA_ "VFrameFormat" BO_ 792 14;
BA_ "CANFD_BRS" BO_ 792 1;
BA_ "GenMsgCycleTime" BO_ 792 100;
BA_ "GenMsgCycleTimeFast" BO_ 792 0;
BA_ "GenMsgSendType" BO_ 792 0;
BA_ "VFrameFormat" BO_ 792 14;
BA_ "CANFD_BRS" BO_ 792 1;
BA_ "GenMsgCycleTime" BO_ 792 100;
BA_ "GenMsgCycleTimeFast" BO_ 792 0;
BA_ "GenMsgSendType" BO_ 792 0;
BA_ "VFrameFormat" BO_ 792 14;
BA_ "CANFD_BRS" BO_ 792 1;
BA_ "GenMsgCycleTime" BO_ 792 100;
BA_ "GenMsgCycleTimeFast" BO_ 792 0;
BA_ "GenMsgSendType" BO_ 792 0;
BA_ "VFrameFormat" BO_ 792 14;
BA_ "CANFD_BRS" BO_ 792 1;
BA_ "GenMsgCycleTime" BO_ 860 100;
BA_ "GenMsgCycleTimeFast" BO_ 860 0;
BA_ "GenMsgSendType" BO_ 860 0;
BA_ "VFrameFormat" BO_ 860 14;
BA_ "CANFD_BRS" BO_ 860 1;
BA_ "GenMsgCycleTime" BO_ 860 100;
BA_ "GenMsgCycleTimeFast" BO_ 860 0;
BA_ "GenMsgSendType" BO_ 860 0;
BA_ "VFrameFormat" BO_ 860 14;
BA_ "CANFD_BRS" BO_ 860 1;
BA_ "GenMsgCycleTime" BO_ 860 100;
BA_ "GenMsgCycleTimeFast" BO_ 860 0;
BA_ "GenMsgSendType" BO_ 860 0;
BA_ "VFrameFormat" BO_ 860 14;
BA_ "CANFD_BRS" BO_ 860 1;
BA_ "GenMsgCycleTime" BO_ 860 100;
BA_ "GenMsgCycleTimeFast" BO_ 860 0;
BA_ "GenMsgSendType" BO_ 860 0;
BA_ "VFrameFormat" BO_ 860 14;
BA_ "CANFD_BRS" BO_ 860 1;
BA_ "GenMsgCycleTime" BO_ 860 100;
BA_ "GenMsgCycleTimeFast" BO_ 860 0;
BA_ "GenMsgSendType" BO_ 860 0;
BA_ "VFrameFormat" BO_ 860 14;
BA_ "CANFD_BRS" BO_ 860 1;
BA_ "GenMsgCycleTime" BO_ 860 100;
BA_ "GenMsgCycleTimeFast" BO_ 860 0;
BA_ "GenMsgSendType" BO_ 860 0;
BA_ "VFrameFormat" BO_ 860 14;
BA_ "CANFD_BRS" BO_ 860 1;
BA_ "GenMsgCycleTime" BO_ 860 100;
BA_ "GenMsgCycleTimeFast" BO_ 860 0;
BA_ "GenMsgSendType" BO_ 860 0;
BA_ "VFrameFormat" BO_ 860 14;
BA_ "CANFD_BRS" BO_ 860 1;
BA_ "GenMsgCycleTime" BO_ 860 100;
BA_ "GenMsgCycleTimeFast" BO_ 860 0;
BA_ "GenMsgSendType" BO_ 860 0;
BA_ "VFrameFormat" BO_ 860 14;
BA_ "CANFD_BRS" BO_ 860 1;
BA_ "GenMsgCycleTime" BO_ 860 100;
BA_ "GenMsgCycleTimeFast" BO_ 860 0;
BA_ "GenMsgSendType" BO_ 860 0;
BA_ "VFrameFormat" BO_ 860 14;
BA_ "CANFD_BRS" BO_ 860 1;
BA_ "GenMsgCycleTime" BO_ 860 100;
BA_ "GenMsgCycleTimeFast" BO_ 860 0;
BA_ "GenMsgSendType" BO_ 860 0;
BA_ "VFrameFormat" BO_ 860 14;
BA_ "CANFD_BRS" BO_ 860 1;
BA_ "GenMsgCycleTime" BO_ 860 100;
BA_ "GenMsgCycleTimeFast" BO_ 860 0;
BA_ "GenMsgSendType" BO_ 860 0;
BA_ "VFrameFormat" BO_ 860 14;
BA_ "CANFD_BRS" BO_ 860 1;
BA_ "GenMsgCycleTime" BO_ 860 100;
BA_ "GenMsgCycleTimeFast" BO_ 860 0;
BA_ "GenMsgSendType" BO_ 860 0;
BA_ "VFrameFormat" BO_ 860 14;
BA_ "CANFD_BRS" BO_ 860 1;
BA_ "GenMsgCycleTime" BO_ 860 100;
BA_ "GenMsgCycleTimeFast" BO_ 860 0;
BA_ "GenMsgSendType" BO_ 860 0;
BA_ "VFrameFormat" BO_ 860 14;
BA_ "CANFD_BRS" BO_ 860 1;
BA_ "GenMsgCycleTime" BO_ 860 100;
BA_ "GenMsgCycleTimeFast" BO_ 860 0;
BA_ "GenMsgSendType" BO_ 860 0;
BA_ "VFrameFormat" BO_ 860 14;
BA_ "CANFD_BRS" BO_ 860 1;
BA_ "GenMsgCycleTime" BO_ 860 100;
BA_ "GenMsgCycleTimeFast" BO_ 860 0;
BA_ "GenMsgSendType" BO_ 860 0;
BA_ "VFrameFormat" BO_ 860 14;
BA_ "CANFD_BRS" BO_ 860 1;
BA_ "GenMsgCycleTime" BO_ 860 100;
BA_ "GenMsgCycleTimeFast" BO_ 860 0;
BA_ "GenMsgSendType" BO_ 860 0;
BA_ "VFrameFormat" BO_ 860 14;
BA_ "CANFD_BRS" BO_ 860 1;
BA_ "GenMsgCycleTime" BO_ 860 100;
BA_ "GenMsgCycleTimeFast" BO_ 860 0;
BA_ "GenMsgSendType" BO_ 860 0;
BA_ "VFrameFormat" BO_ 860 14;
BA_ "CANFD_BRS" BO_ 860 1;
BA_ "GenMsgCycleTime" BO_ 431 10;
BA_ "GenMsgCycleTimeFast" BO_ 431 0;
BA_ "GenMsgSendType" BO_ 431 0;
BA_ "VFrameFormat" BO_ 431 14;
BA_ "CANFD_BRS" BO_ 431 1;
BA_ "GenMsgCycleTime" BO_ 431 10;
BA_ "GenMsgCycleTimeFast" BO_ 431 0;
BA_ "GenMsgSendType" BO_ 431 0;
BA_ "VFrameFormat" BO_ 431 14;
BA_ "CANFD_BRS" BO_ 431 1;
BA_ "GenMsgCycleTime" BO_ 431 10;
BA_ "GenMsgCycleTimeFast" BO_ 431 0;
BA_ "GenMsgSendType" BO_ 431 0;
BA_ "VFrameFormat" BO_ 431 14;
BA_ "CANFD_BRS" BO_ 431 1;
BA_ "GenMsgCycleTime" BO_ 431 10;
BA_ "GenMsgCycleTimeFast" BO_ 431 0;
BA_ "GenMsgSendType" BO_ 431 0;
BA_ "VFrameFormat" BO_ 431 14;
BA_ "CANFD_BRS" BO_ 431 1;
BA_ "GenMsgCycleTime" BO_ 431 10;
BA_ "GenMsgCycleTimeFast" BO_ 431 0;
BA_ "GenMsgSendType" BO_ 431 0;
BA_ "VFrameFormat" BO_ 431 14;
BA_ "CANFD_BRS" BO_ 431 1;
BA_ "GenMsgCycleTime" BO_ 431 10;
BA_ "GenMsgCycleTimeFast" BO_ 431 0;
BA_ "GenMsgSendType" BO_ 431 0;
BA_ "VFrameFormat" BO_ 431 14;
BA_ "CANFD_BRS" BO_ 431 1;
BA_ "GenMsgCycleTime" BO_ 431 10;
BA_ "GenMsgCycleTimeFast" BO_ 431 0;
BA_ "GenMsgSendType" BO_ 431 0;
BA_ "VFrameFormat" BO_ 431 14;
BA_ "CANFD_BRS" BO_ 431 1;
BA_ "GenMsgCycleTime" BO_ 431 10;
BA_ "GenMsgCycleTimeFast" BO_ 431 0;
BA_ "GenMsgSendType" BO_ 431 0;
BA_ "VFrameFormat" BO_ 431 14;
BA_ "CANFD_BRS" BO_ 431 1;
BA_ "GenMsgCycleTime" BO_ 431 10;
BA_ "GenMsgCycleTimeFast" BO_ 431 0;
BA_ "GenMsgSendType" BO_ 431 0;
BA_ "VFrameFormat" BO_ 431 14;
BA_ "CANFD_BRS" BO_ 431 1;
BA_ "GenMsgCycleTime" BO_ 431 10;
BA_ "GenMsgCycleTimeFast" BO_ 431 0;
BA_ "GenMsgSendType" BO_ 431 0;
BA_ "VFrameFormat" BO_ 431 14;
BA_ "CANFD_BRS" BO_ 431 1;
BA_ "GenMsgCycleTime" BO_ 431 10;
BA_ "GenMsgCycleTimeFast" BO_ 431 0;
BA_ "GenMsgSendType" BO_ 431 0;
BA_ "VFrameFormat" BO_ 431 14;
BA_ "CANFD_BRS" BO_ 431 1;
BA_ "GenMsgCycleTime" BO_ 431 10;
BA_ "GenMsgCycleTimeFast" BO_ 431 0;
BA_ "GenMsgSendType" BO_ 431 0;
BA_ "VFrameFormat" BO_ 431 14;
BA_ "CANFD_BRS" BO_ 431 1;
BA_ "GenMsgCycleTime" BO_ 431 10;
BA_ "GenMsgCycleTimeFast" BO_ 431 0;
BA_ "GenMsgSendType" BO_ 431 0;
BA_ "VFrameFormat" BO_ 431 14;
BA_ "CANFD_BRS" BO_ 431 1;
BA_ "GenMsgCycleTime" BO_ 431 10;
BA_ "GenMsgCycleTimeFast" BO_ 431 0;
BA_ "GenMsgSendType" BO_ 431 0;
BA_ "VFrameFormat" BO_ 431 14;
BA_ "CANFD_BRS" BO_ 431 1;
BA_ "GenMsgCycleTime" BO_ 431 10;
BA_ "GenMsgCycleTimeFast" BO_ 431 0;
BA_ "GenMsgSendType" BO_ 431 0;
BA_ "VFrameFormat" BO_ 431 14;
BA_ "CANFD_BRS" BO_ 431 1;
BA_ "GenMsgCycleTime" BO_ 431 10;
BA_ "GenMsgCycleTimeFast" BO_ 431 0;
BA_ "GenMsgSendType" BO_ 431 0;
BA_ "VFrameFormat" BO_ 431 14;
BA_ "CANFD_BRS" BO_ 431 1;
BA_ "GenMsgCycleTime" BO_ 431 10;
BA_ "GenMsgCycleTimeFast" BO_ 431 0;
BA_ "GenMsgSendType" BO_ 431 0;
BA_ "VFrameFormat" BO_ 431 14;
BA_ "CANFD_BRS" BO_ 431 1;
BA_ "GenMsgCycleTime" BO_ 431 10;
BA_ "GenMsgCycleTimeFast" BO_ 431 0;
BA_ "GenMsgSendType" BO_ 431 0;
BA_ "VFrameFormat" BO_ 431 14;
BA_ "CANFD_BRS" BO_ 431 1;
BA_ "GenMsgCycleTime" BO_ 431 10;
BA_ "GenMsgCycleTimeFast" BO_ 431 0;
BA_ "GenMsgSendType" BO_ 431 0;
BA_ "VFrameFormat" BO_ 431 14;
BA_ "CANFD_BRS" BO_ 431 1;
BA_ "GenMsgCycleTime" BO_ 431 10;
BA_ "GenMsgCycleTimeFast" BO_ 431 0;
BA_ "GenMsgSendType" BO_ 431 0;
BA_ "VFrameFormat" BO_ 431 14;
BA_ "CANFD_BRS" BO_ 431 1;
BA_ "GenMsgCycleTime" BO_ 431 10;
BA_ "GenMsgCycleTimeFast" BO_ 431 0;
BA_ "GenMsgSendType" BO_ 431 0;
BA_ "VFrameFormat" BO_ 431 14;
BA_ "CANFD_BRS" BO_ 431 1;
BA_ "GenMsgCycleTime" BO_ 431 10;
BA_ "GenMsgCycleTimeFast" BO_ 431 0;
BA_ "GenMsgSendType" BO_ 431 0;
BA_ "VFrameFormat" BO_ 431 14;
BA_ "CANFD_BRS" BO_ 431 1;
BA_ "GenMsgCycleTime" BO_ 431 10;
BA_ "GenMsgCycleTimeFast" BO_ 431 0;
BA_ "GenMsgSendType" BO_ 431 0;
BA_ "VFrameFormat" BO_ 431 14;
BA_ "CANFD_BRS" BO_ 431 1;
BA_ "GenMsgCycleTime" BO_ 431 10;
BA_ "GenMsgCycleTimeFast" BO_ 431 0;
BA_ "GenMsgSendType" BO_ 431 0;
BA_ "VFrameFormat" BO_ 431 14;
BA_ "CANFD_BRS" BO_ 431 1;
BA_ "GenMsgCycleTime" BO_ 431 10;
BA_ "GenMsgCycleTimeFast" BO_ 431 0;
BA_ "GenMsgSendType" BO_ 431 0;
BA_ "VFrameFormat" BO_ 431 14;
BA_ "CANFD_BRS" BO_ 431 1;
BA_ "GenMsgCycleTime" BO_ 431 10;
BA_ "GenMsgCycleTimeFast" BO_ 431 0;
BA_ "GenMsgSendType" BO_ 431 0;
BA_ "VFrameFormat" BO_ 431 14;
BA_ "CANFD_BRS" BO_ 431 1;
BA_ "GenMsgCycleTime" BO_ 431 10;
BA_ "GenMsgCycleTimeFast" BO_ 431 0;
BA_ "GenMsgSendType" BO_ 431 0;
BA_ "VFrameFormat" BO_ 431 14;
BA_ "CANFD_BRS" BO_ 431 1;
BA_ "GenMsgCycleTime" BO_ 431 10;
BA_ "GenMsgCycleTimeFast" BO_ 431 0;
BA_ "GenMsgSendType" BO_ 431 0;
BA_ "VFrameFormat" BO_ 431 14;
BA_ "CANFD_BRS" BO_ 431 1;
BA_ "GenMsgCycleTime" BO_ 431 10;
BA_ "GenMsgCycleTimeFast" BO_ 431 0;
BA_ "GenMsgSendType" BO_ 431 0;
BA_ "VFrameFormat" BO_ 431 14;
BA_ "CANFD_BRS" BO_ 431 1;
BA_ "GenMsgCycleTime" BO_ 431 10;
BA_ "GenMsgCycleTimeFast" BO_ 431 0;
BA_ "GenMsgSendType" BO_ 431 0;
BA_ "VFrameFormat" BO_ 431 14;
BA_ "CANFD_BRS" BO_ 431 1;
BA_ "GenMsgCycleTime" BO_ 431 10;
BA_ "GenMsgCycleTimeFast" BO_ 431 0;
BA_ "GenMsgSendType" BO_ 431 0;
BA_ "VFrameFormat" BO_ 431 14;
BA_ "CANFD_BRS" BO_ 431 1;
BA_ "GenMsgCycleTime" BO_ 431 10;
BA_ "GenMsgCycleTimeFast" BO_ 431 0;
BA_ "GenMsgSendType" BO_ 431 0;
BA_ "VFrameFormat" BO_ 431 14;
BA_ "CANFD_BRS" BO_ 431 1;
BA_ "GenMsgCycleTime" BO_ 430 10;
BA_ "GenMsgCycleTimeFast" BO_ 430 0;
BA_ "GenMsgSendType" BO_ 430 0;
BA_ "VFrameFormat" BO_ 430 14;
BA_ "CANFD_BRS" BO_ 430 1;
BA_ "GenMsgCycleTime" BO_ 430 10;
BA_ "GenMsgCycleTimeFast" BO_ 430 0;
BA_ "GenMsgSendType" BO_ 430 0;
BA_ "VFrameFormat" BO_ 430 14;
BA_ "CANFD_BRS" BO_ 430 1;
BA_ "GenMsgCycleTime" BO_ 430 10;
BA_ "GenMsgCycleTimeFast" BO_ 430 0;
BA_ "GenMsgSendType" BO_ 430 0;
BA_ "VFrameFormat" BO_ 430 14;
BA_ "CANFD_BRS" BO_ 430 1;
BA_ "GenMsgCycleTime" BO_ 430 10;
BA_ "GenMsgCycleTimeFast" BO_ 430 0;
BA_ "GenMsgSendType" BO_ 430 0;
BA_ "VFrameFormat" BO_ 430 14;
BA_ "CANFD_BRS" BO_ 430 1;
BA_ "GenMsgCycleTime" BO_ 430 10;
BA_ "GenMsgCycleTimeFast" BO_ 430 0;
BA_ "GenMsgSendType" BO_ 430 0;
BA_ "VFrameFormat" BO_ 430 14;
BA_ "CANFD_BRS" BO_ 430 1;
BA_ "GenMsgCycleTime" BO_ 430 10;
BA_ "GenMsgCycleTimeFast" BO_ 430 0;
BA_ "GenMsgSendType" BO_ 430 0;
BA_ "VFrameFormat" BO_ 430 14;
BA_ "CANFD_BRS" BO_ 430 1;
BA_ "GenMsgCycleTime" BO_ 430 10;
BA_ "GenMsgCycleTimeFast" BO_ 430 0;
BA_ "GenMsgSendType" BO_ 430 0;
BA_ "VFrameFormat" BO_ 430 14;
BA_ "CANFD_BRS" BO_ 430 1;
BA_ "GenMsgCycleTime" BO_ 430 10;
BA_ "GenMsgCycleTimeFast" BO_ 430 0;
BA_ "GenMsgSendType" BO_ 430 0;
BA_ "VFrameFormat" BO_ 430 14;
BA_ "CANFD_BRS" BO_ 430 1;
BA_ "GenMsgCycleTime" BO_ 430 10;
BA_ "GenMsgCycleTimeFast" BO_ 430 0;
BA_ "GenMsgSendType" BO_ 430 0;
BA_ "VFrameFormat" BO_ 430 14;
BA_ "CANFD_BRS" BO_ 430 1;
BA_ "GenMsgCycleTime" BO_ 430 10;
BA_ "GenMsgCycleTimeFast" BO_ 430 0;
BA_ "GenMsgSendType" BO_ 430 0;
BA_ "VFrameFormat" BO_ 430 14;
BA_ "CANFD_BRS" BO_ 430 1;
BA_ "GenMsgCycleTime" BO_ 430 10;
BA_ "GenMsgCycleTimeFast" BO_ 430 0;
BA_ "GenMsgSendType" BO_ 430 0;
BA_ "VFrameFormat" BO_ 430 14;
BA_ "CANFD_BRS" BO_ 430 1;
BA_ "GenMsgCycleTime" BO_ 430 10;
BA_ "GenMsgCycleTimeFast" BO_ 430 0;
BA_ "GenMsgSendType" BO_ 430 0;
BA_ "VFrameFormat" BO_ 430 14;
BA_ "CANFD_BRS" BO_ 430 1;
BA_ "GenMsgCycleTime" BO_ 430 10;
BA_ "GenMsgCycleTimeFast" BO_ 430 0;
BA_ "GenMsgSendType" BO_ 430 0;
BA_ "VFrameFormat" BO_ 430 14;
BA_ "CANFD_BRS" BO_ 430 1;
BA_ "GenMsgCycleTime" BO_ 430 10;
BA_ "GenMsgCycleTimeFast" BO_ 430 0;
BA_ "GenMsgSendType" BO_ 430 0;
BA_ "VFrameFormat" BO_ 430 14;
BA_ "CANFD_BRS" BO_ 430 1;
BA_ "GenMsgCycleTime" BO_ 430 10;
BA_ "GenMsgCycleTimeFast" BO_ 430 0;
BA_ "GenMsgSendType" BO_ 430 0;
BA_ "VFrameFormat" BO_ 430 14;
BA_ "CANFD_BRS" BO_ 430 1;
BA_ "GenMsgCycleTime" BO_ 430 10;
BA_ "GenMsgCycleTimeFast" BO_ 430 0;
BA_ "GenMsgSendType" BO_ 430 0;
BA_ "VFrameFormat" BO_ 430 14;
BA_ "CANFD_BRS" BO_ 430 1;
BA_ "GenMsgCycleTime" BO_ 831 100;
BA_ "GenMsgCycleTimeFast" BO_ 831 0;
BA_ "GenMsgSendType" BO_ 831 0;
BA_ "VFrameFormat" BO_ 831 14;
BA_ "CANFD_BRS" BO_ 831 1;
BA_ "GenMsgCycleTime" BO_ 290 500;
BA_ "GenMsgCycleTimeFast" BO_ 290 40;
BA_ "GenMsgSendType" BO_ 290 3;
BA_ "VFrameFormat" BO_ 290 14;
BA_ "CANFD_BRS" BO_ 290 1;
BA_ "GenMsgCycleTime" BO_ 290 500;
BA_ "GenMsgCycleTimeFast" BO_ 290 40;
BA_ "GenMsgSendType" BO_ 290 3;
BA_ "VFrameFormat" BO_ 290 14;
BA_ "CANFD_BRS" BO_ 290 1;
BA_ "GenMsgCycleTime" BO_ 290 500;
BA_ "GenMsgCycleTimeFast" BO_ 290 40;
BA_ "GenMsgSendType" BO_ 290 3;
BA_ "VFrameFormat" BO_ 290 14;
BA_ "CANFD_BRS" BO_ 290 1;
BA_ "GenMsgCycleTime" BO_ 290 500;
BA_ "GenMsgCycleTimeFast" BO_ 290 40;
BA_ "GenMsgSendType" BO_ 290 3;
BA_ "VFrameFormat" BO_ 290 14;
BA_ "CANFD_BRS" BO_ 290 1;
BA_ "GenMsgCycleTime" BO_ 290 500;
BA_ "GenMsgCycleTimeFast" BO_ 290 40;
BA_ "GenMsgSendType" BO_ 290 3;
BA_ "VFrameFormat" BO_ 290 14;
BA_ "CANFD_BRS" BO_ 290 1;
BA_ "GenMsgCycleTime" BO_ 290 500;
BA_ "GenMsgCycleTimeFast" BO_ 290 40;
BA_ "GenMsgSendType" BO_ 290 3;
BA_ "VFrameFormat" BO_ 290 14;
BA_ "CANFD_BRS" BO_ 290 1;
BA_ "EventCommandSignal" SG_ 371 ADC_13_B_CRC 0;
BA_ "GatewayedSignals" SG_ 371 ADC_13_B_CRC 0;
BA_ "GenSigInactiveValue" SG_ 371 ADC_13_B_CRC 0;
BA_ "GenSigInvalidValue" SG_ 371 ADC_13_B_CRC 0;
BA_ "GenSigSendType" SG_ 371 ADC_13_B_CRC 1;
BA_ "GenSigStartValue" SG_ 371 ADC_13_B_CRC 0;
BA_ "GenSigTimeoutValue" SG_ 371 ADC_13_B_CRC 0;
BA_ "Remark" SG_ 371 ADC_13_B_CRC "";
BA_ "EventCommandSignal" SG_ 371 ADC_13_B_Counter 0;
BA_ "GatewayedSignals" SG_ 371 ADC_13_B_Counter 0;
BA_ "GenSigInactiveValue" SG_ 371 ADC_13_B_Counter 0;
BA_ "GenSigInvalidValue" SG_ 371 ADC_13_B_Counter 0;
BA_ "GenSigSendType" SG_ 371 ADC_13_B_Counter 1;
BA_ "GenSigStartValue" SG_ 371 ADC_13_B_Counter 0;
BA_ "GenSigTimeoutValue" SG_ 371 ADC_13_B_Counter 0;
BA_ "Remark" SG_ 371 ADC_13_B_Counter "";
BA_ "EventCommandSignal" SG_ 371 ADC_DycEscTarTq 0;
BA_ "GatewayedSignals" SG_ 371 ADC_DycEscTarTq 0;
BA_ "GenSigInactiveValue" SG_ 371 ADC_DycEscTarTq 0;
BA_ "GenSigInvalidValue" SG_ 371 ADC_DycEscTarTq 0;
BA_ "GenSigSendType" SG_ 371 ADC_DycEscTarTq 1;
BA_ "GenSigStartValue" SG_ 371 ADC_DycEscTarTq 0;
BA_ "GenSigTimeoutValue" SG_ 371 ADC_DycEscTarTq 0;
BA_ "Remark" SG_ 371 ADC_DycEscTarTq "";
BA_ "EventCommandSignal" SG_ 371 ADC_DycEscTarTqfactor 0;
BA_ "GatewayedSignals" SG_ 371 ADC_DycEscTarTqfactor 0;
BA_ "GenSigInactiveValue" SG_ 371 ADC_DycEscTarTqfactor 0;
BA_ "GenSigInvalidValue" SG_ 371 ADC_DycEscTarTqfactor 0;
BA_ "GenSigSendType" SG_ 371 ADC_DycEscTarTqfactor 1;
BA_ "GenSigStartValue" SG_ 371 ADC_DycEscTarTqfactor 0;
BA_ "GenSigTimeoutValue" SG_ 371 ADC_DycEscTarTqfactor 0;
BA_ "Remark" SG_ 371 ADC_DycEscTarTqfactor "";
BA_ "EventCommandSignal" SG_ 371 ADC_SteerTqReq 0;
BA_ "GatewayedSignals" SG_ 371 ADC_SteerTqReq 0;
BA_ "GenSigInactiveValue" SG_ 371 ADC_SteerTqReq 0;
BA_ "GenSigInvalidValue" SG_ 371 ADC_SteerTqReq 4095;
BA_ "GenSigSendType" SG_ 371 ADC_SteerTqReq 1;
BA_ "GenSigStartValue" SG_ 371 ADC_SteerTqReq 2000;
BA_ "GenSigTimeoutValue" SG_ 371 ADC_SteerTqReq 4095;
BA_ "Remark" SG_ 371 ADC_SteerTqReq "";
BA_ "EventCommandSignal" SG_ 371 ADC_SteerTqSt 0;
BA_ "GatewayedSignals" SG_ 371 ADC_SteerTqSt 0;
BA_ "GenSigInactiveValue" SG_ 371 ADC_SteerTqSt 0;
BA_ "GenSigInvalidValue" SG_ 371 ADC_SteerTqSt 0;
BA_ "GenSigSendType" SG_ 371 ADC_SteerTqSt 1;
BA_ "GenSigStartValue" SG_ 371 ADC_SteerTqSt 0;
BA_ "GenSigTimeoutValue" SG_ 371 ADC_SteerTqSt 0;
BA_ "Remark" SG_ 371 ADC_SteerTqSt "";
BA_ "EventCommandSignal" SG_ 371 ADC_TqEvsSteerReq 0;
BA_ "GatewayedSignals" SG_ 371 ADC_TqEvsSteerReq 0;
BA_ "GenSigInactiveValue" SG_ 371 ADC_TqEvsSteerReq 0;
BA_ "GenSigInvalidValue" SG_ 371 ADC_TqEvsSteerReq 0;
BA_ "GenSigSendType" SG_ 371 ADC_TqEvsSteerReq 1;
BA_ "GenSigStartValue" SG_ 371 ADC_TqEvsSteerReq 0;
BA_ "GenSigTimeoutValue" SG_ 371 ADC_TqEvsSteerReq 0;
BA_ "Remark" SG_ 371 ADC_TqEvsSteerReq "";
BA_ "EventCommandSignal" SG_ 371 ADC_SteerTqAvl 0;
BA_ "GatewayedSignals" SG_ 371 ADC_SteerTqAvl 0;
BA_ "GenSigInactiveValue" SG_ 371 ADC_SteerTqAvl 0;
BA_ "GenSigInvalidValue" SG_ 371 ADC_SteerTqAvl 0;
BA_ "GenSigSendType" SG_ 371 ADC_SteerTqAvl 1;
BA_ "GenSigStartValue" SG_ 371 ADC_SteerTqAvl 0;
BA_ "GenSigTimeoutValue" SG_ 371 ADC_SteerTqAvl 0;
BA_ "Remark" SG_ 371 ADC_SteerTqAvl "";
BA_ "EventCommandSignal" SG_ 371 ADC_DycEscTarTqVld 0;
BA_ "GatewayedSignals" SG_ 371 ADC_DycEscTarTqVld 0;
BA_ "GenSigInactiveValue" SG_ 371 ADC_DycEscTarTqVld 0;
BA_ "GenSigInvalidValue" SG_ 371 ADC_DycEscTarTqVld 0;
BA_ "GenSigSendType" SG_ 371 ADC_DycEscTarTqVld 1;
BA_ "GenSigStartValue" SG_ 371 ADC_DycEscTarTqVld 0;
BA_ "GenSigTimeoutValue" SG_ 371 ADC_DycEscTarTqVld 0;
BA_ "Remark" SG_ 371 ADC_DycEscTarTqVld "";
BA_ "EventCommandSignal" SG_ 371 ADC_DycEscTarTqEna 0;
BA_ "GatewayedSignals" SG_ 371 ADC_DycEscTarTqEna 0;
BA_ "GenSigInactiveValue" SG_ 371 ADC_DycEscTarTqEna 0;
BA_ "GenSigInvalidValue" SG_ 371 ADC_DycEscTarTqEna 0;
BA_ "GenSigSendType" SG_ 371 ADC_DycEscTarTqEna 1;
BA_ "GenSigStartValue" SG_ 371 ADC_DycEscTarTqEna 0;
BA_ "GenSigTimeoutValue" SG_ 371 ADC_DycEscTarTqEna 0;
BA_ "Remark" SG_ 371 ADC_DycEscTarTqEna "";
BA_ "EventCommandSignal" SG_ 371 ADC_RoadTyp 0;
BA_ "GatewayedSignals" SG_ 371 ADC_RoadTyp 0;
BA_ "GenSigInactiveValue" SG_ 371 ADC_RoadTyp 0;
BA_ "GenSigInvalidValue" SG_ 371 ADC_RoadTyp 7;
BA_ "GenSigSendType" SG_ 371 ADC_RoadTyp 1;
BA_ "GenSigStartValue" SG_ 371 ADC_RoadTyp 0;
BA_ "GenSigTimeoutValue" SG_ 371 ADC_RoadTyp 0;
BA_ "Remark" SG_ 371 ADC_RoadTyp "";
BA_ "EventCommandSignal" SG_ 371 ADC_LeWhlLgtDst 0;
BA_ "GatewayedSignals" SG_ 371 ADC_LeWhlLgtDst 0;
BA_ "GenSigInactiveValue" SG_ 371 ADC_LeWhlLgtDst 0;
BA_ "GenSigInvalidValue" SG_ 371 ADC_LeWhlLgtDst 0;
BA_ "GenSigSendType" SG_ 371 ADC_LeWhlLgtDst 1;
BA_ "GenSigStartValue" SG_ 371 ADC_LeWhlLgtDst 0;
BA_ "GenSigTimeoutValue" SG_ 371 ADC_LeWhlLgtDst 0;
BA_ "Remark" SG_ 371 ADC_LeWhlLgtDst "";
BA_ "EventCommandSignal" SG_ 371 ADC_LeWhlRoadHei 0;
BA_ "GatewayedSignals" SG_ 371 ADC_LeWhlRoadHei 0;
BA_ "GenSigInactiveValue" SG_ 371 ADC_LeWhlRoadHei 0;
BA_ "GenSigInvalidValue" SG_ 371 ADC_LeWhlRoadHei 0;
BA_ "GenSigSendType" SG_ 371 ADC_LeWhlRoadHei 1;
BA_ "GenSigStartValue" SG_ 371 ADC_LeWhlRoadHei 500;
BA_ "GenSigTimeoutValue" SG_ 371 ADC_LeWhlRoadHei 0;
BA_ "Remark" SG_ 371 ADC_LeWhlRoadHei "";
BA_ "EventCommandSignal" SG_ 371 ADC_RiWhlLgtDst 0;
BA_ "GatewayedSignals" SG_ 371 ADC_RiWhlLgtDst 0;
BA_ "GenSigInactiveValue" SG_ 371 ADC_RiWhlLgtDst 0;
BA_ "GenSigInvalidValue" SG_ 371 ADC_RiWhlLgtDst 0;
BA_ "GenSigSendType" SG_ 371 ADC_RiWhlLgtDst 1;
BA_ "GenSigStartValue" SG_ 371 ADC_RiWhlLgtDst 0;
BA_ "GenSigTimeoutValue" SG_ 371 ADC_RiWhlLgtDst 0;
BA_ "Remark" SG_ 371 ADC_RiWhlLgtDst "";
BA_ "EventCommandSignal" SG_ 371 ADC_RiWhlRoadHei 0;
BA_ "GatewayedSignals" SG_ 371 ADC_RiWhlRoadHei 0;
BA_ "GenSigInactiveValue" SG_ 371 ADC_RiWhlRoadHei 0;
BA_ "GenSigInvalidValue" SG_ 371 ADC_RiWhlRoadHei 0;
BA_ "GenSigSendType" SG_ 371 ADC_RiWhlRoadHei 1;
BA_ "GenSigStartValue" SG_ 371 ADC_RiWhlRoadHei 500;
BA_ "GenSigTimeoutValue" SG_ 371 ADC_RiWhlRoadHei 0;
BA_ "Remark" SG_ 371 ADC_RiWhlRoadHei "";
BA_ "EventCommandSignal" SG_ 371 ADC_RiWhlRoadFeature 0;
BA_ "GatewayedSignals" SG_ 371 ADC_RiWhlRoadFeature 0;
BA_ "GenSigInactiveValue" SG_ 371 ADC_RiWhlRoadFeature 0;
BA_ "GenSigInvalidValue" SG_ 371 ADC_RiWhlRoadFeature 15;
BA_ "GenSigSendType" SG_ 371 ADC_RiWhlRoadFeature 1;
BA_ "GenSigStartValue" SG_ 371 ADC_RiWhlRoadFeature 0;
BA_ "GenSigTimeoutValue" SG_ 371 ADC_RiWhlRoadFeature 0;
BA_ "Remark" SG_ 371 ADC_RiWhlRoadFeature "";
BA_ "EventCommandSignal" SG_ 371 ADC_SuspensionStatus 0;
BA_ "GatewayedSignals" SG_ 371 ADC_SuspensionStatus 0;
BA_ "GenSigInactiveValue" SG_ 371 ADC_SuspensionStatus 0;
BA_ "GenSigInvalidValue" SG_ 371 ADC_SuspensionStatus 0;
BA_ "GenSigSendType" SG_ 371 ADC_SuspensionStatus 1;
BA_ "GenSigStartValue" SG_ 371 ADC_SuspensionStatus 0;
BA_ "GenSigTimeoutValue" SG_ 371 ADC_SuspensionStatus 0;
BA_ "Remark" SG_ 371 ADC_SuspensionStatus "";
BA_ "EventCommandSignal" SG_ 371 ADC_LeWhlRoadSts 0;
BA_ "GatewayedSignals" SG_ 371 ADC_LeWhlRoadSts 0;
BA_ "GenSigInactiveValue" SG_ 371 ADC_LeWhlRoadSts 0;
BA_ "GenSigInvalidValue" SG_ 371 ADC_LeWhlRoadSts 0;
BA_ "GenSigSendType" SG_ 371 ADC_LeWhlRoadSts 1;
BA_ "GenSigStartValue" SG_ 371 ADC_LeWhlRoadSts 0;
BA_ "GenSigTimeoutValue" SG_ 371 ADC_LeWhlRoadSts 0;
BA_ "Remark" SG_ 371 ADC_LeWhlRoadSts "";
BA_ "EventCommandSignal" SG_ 371 ADC_LeWhlRoadFeature 0;
BA_ "GatewayedSignals" SG_ 371 ADC_LeWhlRoadFeature 0;
BA_ "GenSigInactiveValue" SG_ 371 ADC_LeWhlRoadFeature 0;
BA_ "GenSigInvalidValue" SG_ 371 ADC_LeWhlRoadFeature 15;
BA_ "GenSigSendType" SG_ 371 ADC_LeWhlRoadFeature 1;
BA_ "GenSigStartValue" SG_ 371 ADC_LeWhlRoadFeature 0;
BA_ "GenSigTimeoutValue" SG_ 371 ADC_LeWhlRoadFeature 0;
BA_ "Remark" SG_ 371 ADC_LeWhlRoadFeature "";
BA_ "EventCommandSignal" SG_ 371 ADC_RiWhlRoadSts 0;
BA_ "GatewayedSignals" SG_ 371 ADC_RiWhlRoadSts 0;
BA_ "GenSigInactiveValue" SG_ 371 ADC_RiWhlRoadSts 0;
BA_ "GenSigInvalidValue" SG_ 371 ADC_RiWhlRoadSts 0;
BA_ "GenSigSendType" SG_ 371 ADC_RiWhlRoadSts 1;
BA_ "GenSigStartValue" SG_ 371 ADC_RiWhlRoadSts 0;
BA_ "GenSigTimeoutValue" SG_ 371 ADC_RiWhlRoadSts 0;
BA_ "Remark" SG_ 371 ADC_RiWhlRoadSts "";
BA_ "EventCommandSignal" SG_ 371 ADC_CDCCtrlEnable 0;
BA_ "GatewayedSignals" SG_ 371 ADC_CDCCtrlEnable 0;
BA_ "GenSigInactiveValue" SG_ 371 ADC_CDCCtrlEnable 0;
BA_ "GenSigInvalidValue" SG_ 371 ADC_CDCCtrlEnable 0;
BA_ "GenSigSendType" SG_ 371 ADC_CDCCtrlEnable 1;
BA_ "GenSigStartValue" SG_ 371 ADC_CDCCtrlEnable 0;
BA_ "GenSigTimeoutValue" SG_ 371 ADC_CDCCtrlEnable 0;
BA_ "Remark" SG_ 371 ADC_CDCCtrlEnable "";
BA_ "EventCommandSignal" SG_ 371 ADC_RoadInfoAvl 0;
BA_ "GatewayedSignals" SG_ 371 ADC_RoadInfoAvl 0;
BA_ "GenSigInactiveValue" SG_ 371 ADC_RoadInfoAvl 0;
BA_ "GenSigInvalidValue" SG_ 371 ADC_RoadInfoAvl 0;
BA_ "GenSigSendType" SG_ 371 ADC_RoadInfoAvl 1;
BA_ "GenSigStartValue" SG_ 371 ADC_RoadInfoAvl 0;
BA_ "GenSigTimeoutValue" SG_ 371 ADC_RoadInfoAvl 0;
BA_ "Remark" SG_ 371 ADC_RoadInfoAvl "";
BA_ "EventCommandSignal" SG_ 371 ADC_RoadFeatureDetFalutSts 0;
BA_ "GatewayedSignals" SG_ 371 ADC_RoadFeatureDetFalutSts 0;
BA_ "GenSigInactiveValue" SG_ 371 ADC_RoadFeatureDetFalutSts 0;
BA_ "GenSigInvalidValue" SG_ 371 ADC_RoadFeatureDetFalutSts 0;
BA_ "GenSigSendType" SG_ 371 ADC_RoadFeatureDetFalutSts 1;
BA_ "GenSigStartValue" SG_ 371 ADC_RoadFeatureDetFalutSts 0;
BA_ "GenSigTimeoutValue" SG_ 371 ADC_RoadFeatureDetFalutSts 1;
BA_ "Remark" SG_ 371 ADC_RoadFeatureDetFalutSts "";
BA_ "EventCommandSignal" SG_ 371 ADC_RoadFeatureDetWorkSts 0;
BA_ "GatewayedSignals" SG_ 371 ADC_RoadFeatureDetWorkSts 0;
BA_ "GenSigInactiveValue" SG_ 371 ADC_RoadFeatureDetWorkSts 0;
BA_ "GenSigInvalidValue" SG_ 371 ADC_RoadFeatureDetWorkSts 0;
BA_ "GenSigSendType" SG_ 371 ADC_RoadFeatureDetWorkSts 1;
BA_ "GenSigStartValue" SG_ 371 ADC_RoadFeatureDetWorkSts 0;
BA_ "GenSigTimeoutValue" SG_ 371 ADC_RoadFeatureDetWorkSts 0;
BA_ "Remark" SG_ 371 ADC_RoadFeatureDetWorkSts "";
BA_ "EventCommandSignal" SG_ 371 ADC_LeWhlRoadFeature2 0;
BA_ "GatewayedSignals" SG_ 371 ADC_LeWhlRoadFeature2 0;
BA_ "GenSigInactiveValue" SG_ 371 ADC_LeWhlRoadFeature2 0;
BA_ "GenSigInvalidValue" SG_ 371 ADC_LeWhlRoadFeature2 15;
BA_ "GenSigSendType" SG_ 371 ADC_LeWhlRoadFeature2 1;
BA_ "GenSigStartValue" SG_ 371 ADC_LeWhlRoadFeature2 0;
BA_ "GenSigTimeoutValue" SG_ 371 ADC_LeWhlRoadFeature2 0;
BA_ "Remark" SG_ 371 ADC_LeWhlRoadFeature2 "";
BA_ "EventCommandSignal" SG_ 371 ADC_LeWhlRoadFeature3 0;
BA_ "GatewayedSignals" SG_ 371 ADC_LeWhlRoadFeature3 0;
BA_ "GenSigInactiveValue" SG_ 371 ADC_LeWhlRoadFeature3 0;
BA_ "GenSigInvalidValue" SG_ 371 ADC_LeWhlRoadFeature3 15;
BA_ "GenSigSendType" SG_ 371 ADC_LeWhlRoadFeature3 1;
BA_ "GenSigStartValue" SG_ 371 ADC_LeWhlRoadFeature3 0;
BA_ "GenSigTimeoutValue" SG_ 371 ADC_LeWhlRoadFeature3 0;
BA_ "Remark" SG_ 371 ADC_LeWhlRoadFeature3 "";
BA_ "EventCommandSignal" SG_ 371 ADC_RiWhlRoadFeature2 0;
BA_ "GatewayedSignals" SG_ 371 ADC_RiWhlRoadFeature2 0;
BA_ "GenSigInactiveValue" SG_ 371 ADC_RiWhlRoadFeature2 0;
BA_ "GenSigInvalidValue" SG_ 371 ADC_RiWhlRoadFeature2 15;
BA_ "GenSigSendType" SG_ 371 ADC_RiWhlRoadFeature2 1;
BA_ "GenSigStartValue" SG_ 371 ADC_RiWhlRoadFeature2 0;
BA_ "GenSigTimeoutValue" SG_ 371 ADC_RiWhlRoadFeature2 0;
BA_ "Remark" SG_ 371 ADC_RiWhlRoadFeature2 "";
BA_ "EventCommandSignal" SG_ 371 ADC_RiWhlRoadFeature3 0;
BA_ "GatewayedSignals" SG_ 371 ADC_RiWhlRoadFeature3 0;
BA_ "GenSigInactiveValue" SG_ 371 ADC_RiWhlRoadFeature3 0;
BA_ "GenSigInvalidValue" SG_ 371 ADC_RiWhlRoadFeature3 15;
BA_ "GenSigSendType" SG_ 371 ADC_RiWhlRoadFeature3 1;
BA_ "GenSigStartValue" SG_ 371 ADC_RiWhlRoadFeature3 0;
BA_ "GenSigTimeoutValue" SG_ 371 ADC_RiWhlRoadFeature3 0;
BA_ "Remark" SG_ 371 ADC_RiWhlRoadFeature3 "";
BA_ "EventCommandSignal" SG_ 371 ADC_LeWhlRoadHei2 0;
BA_ "GatewayedSignals" SG_ 371 ADC_LeWhlRoadHei2 0;
BA_ "GenSigInactiveValue" SG_ 371 ADC_LeWhlRoadHei2 0;
BA_ "GenSigInvalidValue" SG_ 371 ADC_LeWhlRoadHei2 0;
BA_ "GenSigSendType" SG_ 371 ADC_LeWhlRoadHei2 1;
BA_ "GenSigStartValue" SG_ 371 ADC_LeWhlRoadHei2 0;
BA_ "GenSigTimeoutValue" SG_ 371 ADC_LeWhlRoadHei2 0;
BA_ "Remark" SG_ 371 ADC_LeWhlRoadHei2 "";
BA_ "EventCommandSignal" SG_ 371 ADC_LeWhlRoadHei3 0;
BA_ "GatewayedSignals" SG_ 371 ADC_LeWhlRoadHei3 0;
BA_ "GenSigInactiveValue" SG_ 371 ADC_LeWhlRoadHei3 0;
BA_ "GenSigInvalidValue" SG_ 371 ADC_LeWhlRoadHei3 0;
BA_ "GenSigSendType" SG_ 371 ADC_LeWhlRoadHei3 1;
BA_ "GenSigStartValue" SG_ 371 ADC_LeWhlRoadHei3 0;
BA_ "GenSigTimeoutValue" SG_ 371 ADC_LeWhlRoadHei3 0;
BA_ "Remark" SG_ 371 ADC_LeWhlRoadHei3 "";
BA_ "EventCommandSignal" SG_ 371 ADC_RiWhlRoadHei2 0;
BA_ "GatewayedSignals" SG_ 371 ADC_RiWhlRoadHei2 0;
BA_ "GenSigInactiveValue" SG_ 371 ADC_RiWhlRoadHei2 0;
BA_ "GenSigInvalidValue" SG_ 371 ADC_RiWhlRoadHei2 0;
BA_ "GenSigSendType" SG_ 371 ADC_RiWhlRoadHei2 1;
BA_ "GenSigStartValue" SG_ 371 ADC_RiWhlRoadHei2 0;
BA_ "GenSigTimeoutValue" SG_ 371 ADC_RiWhlRoadHei2 0;
BA_ "Remark" SG_ 371 ADC_RiWhlRoadHei2 "";
BA_ "EventCommandSignal" SG_ 371 ADC_RiWhlRoadHei3 0;
BA_ "GatewayedSignals" SG_ 371 ADC_RiWhlRoadHei3 0;
BA_ "GenSigInactiveValue" SG_ 371 ADC_RiWhlRoadHei3 0;
BA_ "GenSigInvalidValue" SG_ 371 ADC_RiWhlRoadHei3 0;
BA_ "GenSigSendType" SG_ 371 ADC_RiWhlRoadHei3 1;
BA_ "GenSigStartValue" SG_ 371 ADC_RiWhlRoadHei3 0;
BA_ "GenSigTimeoutValue" SG_ 371 ADC_RiWhlRoadHei3 0;
BA_ "Remark" SG_ 371 ADC_RiWhlRoadHei3 "";
BA_ "EventCommandSignal" SG_ 371 ADC_LeWhlLgtDst2 0;
BA_ "GatewayedSignals" SG_ 371 ADC_LeWhlLgtDst2 0;
BA_ "GenSigInactiveValue" SG_ 371 ADC_LeWhlLgtDst2 0;
BA_ "GenSigInvalidValue" SG_ 371 ADC_LeWhlLgtDst2 63;
BA_ "GenSigSendType" SG_ 371 ADC_LeWhlLgtDst2 1;
BA_ "GenSigStartValue" SG_ 371 ADC_LeWhlLgtDst2 63;
BA_ "GenSigTimeoutValue" SG_ 371 ADC_LeWhlLgtDst2 63;
BA_ "Remark" SG_ 371 ADC_LeWhlLgtDst2 "";
BA_ "EventCommandSignal" SG_ 371 ADC_LeWhlLgtDst3 0;
BA_ "GatewayedSignals" SG_ 371 ADC_LeWhlLgtDst3 0;
BA_ "GenSigInactiveValue" SG_ 371 ADC_LeWhlLgtDst3 0;
BA_ "GenSigInvalidValue" SG_ 371 ADC_LeWhlLgtDst3 63;
BA_ "GenSigSendType" SG_ 371 ADC_LeWhlLgtDst3 1;
BA_ "GenSigStartValue" SG_ 371 ADC_LeWhlLgtDst3 63;
BA_ "GenSigTimeoutValue" SG_ 371 ADC_LeWhlLgtDst3 63;
BA_ "Remark" SG_ 371 ADC_LeWhlLgtDst3 "";
BA_ "EventCommandSignal" SG_ 371 ADC_RiWhlLgtDst2 0;
BA_ "GatewayedSignals" SG_ 371 ADC_RiWhlLgtDst2 0;
BA_ "GenSigInactiveValue" SG_ 371 ADC_RiWhlLgtDst2 0;
BA_ "GenSigInvalidValue" SG_ 371 ADC_RiWhlLgtDst2 63;
BA_ "GenSigSendType" SG_ 371 ADC_RiWhlLgtDst2 1;
BA_ "GenSigStartValue" SG_ 371 ADC_RiWhlLgtDst2 63;
BA_ "GenSigTimeoutValue" SG_ 371 ADC_RiWhlLgtDst2 63;
BA_ "Remark" SG_ 371 ADC_RiWhlLgtDst2 "";
BA_ "EventCommandSignal" SG_ 371 ADC_RiWhlLgtDst3 0;
BA_ "GatewayedSignals" SG_ 371 ADC_RiWhlLgtDst3 0;
BA_ "GenSigInactiveValue" SG_ 371 ADC_RiWhlLgtDst3 0;
BA_ "GenSigInvalidValue" SG_ 371 ADC_RiWhlLgtDst3 63;
BA_ "GenSigSendType" SG_ 371 ADC_RiWhlLgtDst3 1;
BA_ "GenSigStartValue" SG_ 371 ADC_RiWhlLgtDst3 63;
BA_ "GenSigTimeoutValue" SG_ 371 ADC_RiWhlLgtDst3 63;
BA_ "Remark" SG_ 371 ADC_RiWhlLgtDst3 "";
BA_ "EventCommandSignal" SG_ 371 ADC_AS_SuspHeiAdj 0;
BA_ "GatewayedSignals" SG_ 371 ADC_AS_SuspHeiAdj 0;
BA_ "GenSigInactiveValue" SG_ 371 ADC_AS_SuspHeiAdj 0;
BA_ "GenSigInvalidValue" SG_ 371 ADC_AS_SuspHeiAdj 0;
BA_ "GenSigSendType" SG_ 371 ADC_AS_SuspHeiAdj 1;
BA_ "GenSigStartValue" SG_ 371 ADC_AS_SuspHeiAdj 0;
BA_ "GenSigTimeoutValue" SG_ 371 ADC_AS_SuspHeiAdj 0;
BA_ "Remark" SG_ 371 ADC_AS_SuspHeiAdj "";
BA_ "EventCommandSignal" SG_ 371 ADC_AS_SuspHeiAdjVld 0;
BA_ "GatewayedSignals" SG_ 371 ADC_AS_SuspHeiAdjVld 0;
BA_ "GenSigInactiveValue" SG_ 371 ADC_AS_SuspHeiAdjVld 0;
BA_ "GenSigInvalidValue" SG_ 371 ADC_AS_SuspHeiAdjVld 0;
BA_ "GenSigSendType" SG_ 371 ADC_AS_SuspHeiAdjVld 1;
BA_ "GenSigStartValue" SG_ 371 ADC_AS_SuspHeiAdjVld 0;
BA_ "GenSigTimeoutValue" SG_ 371 ADC_AS_SuspHeiAdjVld 0;
BA_ "Remark" SG_ 371 ADC_AS_SuspHeiAdjVld "";
BA_ "EventCommandSignal" SG_ 371 ADC_AS_SusStfnAdj 0;
BA_ "GatewayedSignals" SG_ 371 ADC_AS_SusStfnAdj 0;
BA_ "GenSigInactiveValue" SG_ 371 ADC_AS_SusStfnAdj 0;
BA_ "GenSigInvalidValue" SG_ 371 ADC_AS_SusStfnAdj 0;
BA_ "GenSigSendType" SG_ 371 ADC_AS_SusStfnAdj 1;
BA_ "GenSigStartValue" SG_ 371 ADC_AS_SusStfnAdj 0;
BA_ "GenSigTimeoutValue" SG_ 371 ADC_AS_SusStfnAdj 0;
BA_ "Remark" SG_ 371 ADC_AS_SusStfnAdj "";
BA_ "EventCommandSignal" SG_ 371 ADC_AS_SusStfnAdjVld 0;
BA_ "GatewayedSignals" SG_ 371 ADC_AS_SusStfnAdjVld 0;
BA_ "GenSigInactiveValue" SG_ 371 ADC_AS_SusStfnAdjVld 0;
BA_ "GenSigInvalidValue" SG_ 371 ADC_AS_SusStfnAdjVld 0;
BA_ "GenSigSendType" SG_ 371 ADC_AS_SusStfnAdjVld 1;
BA_ "GenSigStartValue" SG_ 371 ADC_AS_SusStfnAdjVld 0;
BA_ "GenSigTimeoutValue" SG_ 371 ADC_AS_SusStfnAdjVld 0;
BA_ "Remark" SG_ 371 ADC_AS_SusStfnAdjVld "";
BA_ "EventCommandSignal" SG_ 371 ADC_CDCModReq 0;
BA_ "GatewayedSignals" SG_ 371 ADC_CDCModReq 0;
BA_ "GenSigInactiveValue" SG_ 371 ADC_CDCModReq 0;
BA_ "GenSigInvalidValue" SG_ 371 ADC_CDCModReq 0;
BA_ "GenSigSendType" SG_ 371 ADC_CDCModReq 1;
BA_ "GenSigStartValue" SG_ 371 ADC_CDCModReq 0;
BA_ "GenSigTimeoutValue" SG_ 371 ADC_CDCModReq 0;
BA_ "Remark" SG_ 371 ADC_CDCModReq "";
BA_ "EventCommandSignal" SG_ 371 ADC_CDCModReqVld 0;
BA_ "GatewayedSignals" SG_ 371 ADC_CDCModReqVld 0;
BA_ "GenSigInactiveValue" SG_ 371 ADC_CDCModReqVld 0;
BA_ "GenSigInvalidValue" SG_ 371 ADC_CDCModReqVld 0;
BA_ "GenSigSendType" SG_ 371 ADC_CDCModReqVld 1;
BA_ "GenSigStartValue" SG_ 371 ADC_CDCModReqVld 0;
BA_ "GenSigTimeoutValue" SG_ 371 ADC_CDCModReqVld 0;
BA_ "Remark" SG_ 371 ADC_CDCModReqVld "";
BA_ "EventCommandSignal" SG_ 371 ADC_AS_LevelingAdj 0;
BA_ "GatewayedSignals" SG_ 371 ADC_AS_LevelingAdj 0;
BA_ "GenSigInactiveValue" SG_ 371 ADC_AS_LevelingAdj 0;
BA_ "GenSigInvalidValue" SG_ 371 ADC_AS_LevelingAdj 0;
BA_ "GenSigSendType" SG_ 371 ADC_AS_LevelingAdj 1;
BA_ "GenSigStartValue" SG_ 371 ADC_AS_LevelingAdj 0;
BA_ "GenSigTimeoutValue" SG_ 371 ADC_AS_LevelingAdj 0;
BA_ "Remark" SG_ 371 ADC_AS_LevelingAdj "";
BA_ "EventCommandSignal" SG_ 371 ADC_AS_LevelingAdjVld 0;
BA_ "GatewayedSignals" SG_ 371 ADC_AS_LevelingAdjVld 0;
BA_ "GenSigInactiveValue" SG_ 371 ADC_AS_LevelingAdjVld 0;
BA_ "GenSigInvalidValue" SG_ 371 ADC_AS_LevelingAdjVld 0;
BA_ "GenSigSendType" SG_ 371 ADC_AS_LevelingAdjVld 1;
BA_ "GenSigStartValue" SG_ 371 ADC_AS_LevelingAdjVld 0;
BA_ "GenSigTimeoutValue" SG_ 371 ADC_AS_LevelingAdjVld 0;
BA_ "Remark" SG_ 371 ADC_AS_LevelingAdjVld "";
BA_ "EventCommandSignal" SG_ 371 ADC_SdcPreAdjFL1 0;
BA_ "GatewayedSignals" SG_ 371 ADC_SdcPreAdjFL1 0;
BA_ "GenSigInactiveValue" SG_ 371 ADC_SdcPreAdjFL1 0;
BA_ "GenSigInvalidValue" SG_ 371 ADC_SdcPreAdjFL1 0;
BA_ "GenSigSendType" SG_ 371 ADC_SdcPreAdjFL1 1;
BA_ "GenSigStartValue" SG_ 371 ADC_SdcPreAdjFL1 0;
BA_ "GenSigTimeoutValue" SG_ 371 ADC_SdcPreAdjFL1 0;
BA_ "Remark" SG_ 371 ADC_SdcPreAdjFL1 "";
BA_ "EventCommandSignal" SG_ 371 ADC_SdcPreAdjFR1 0;
BA_ "GatewayedSignals" SG_ 371 ADC_SdcPreAdjFR1 0;
BA_ "GenSigInactiveValue" SG_ 371 ADC_SdcPreAdjFR1 0;
BA_ "GenSigInvalidValue" SG_ 371 ADC_SdcPreAdjFR1 0;
BA_ "GenSigSendType" SG_ 371 ADC_SdcPreAdjFR1 1;
BA_ "GenSigStartValue" SG_ 371 ADC_SdcPreAdjFR1 0;
BA_ "GenSigTimeoutValue" SG_ 371 ADC_SdcPreAdjFR1 0;
BA_ "Remark" SG_ 371 ADC_SdcPreAdjFR1 "";
BA_ "EventCommandSignal" SG_ 371 ADC_SdcPreAdjVld 0;
BA_ "GatewayedSignals" SG_ 371 ADC_SdcPreAdjVld 0;
BA_ "GenSigInactiveValue" SG_ 371 ADC_SdcPreAdjVld 0;
BA_ "GenSigInvalidValue" SG_ 371 ADC_SdcPreAdjVld 0;
BA_ "GenSigSendType" SG_ 371 ADC_SdcPreAdjVld 1;
BA_ "GenSigStartValue" SG_ 371 ADC_SdcPreAdjVld 0;
BA_ "GenSigTimeoutValue" SG_ 371 ADC_SdcPreAdjVld 0;
BA_ "Remark" SG_ 371 ADC_SdcPreAdjVld "";
BA_ "EventCommandSignal" SG_ 371 ADC_SteerGainLevelTqCtrl 0;
BA_ "GatewayedSignals" SG_ 371 ADC_SteerGainLevelTqCtrl 0;
BA_ "GenSigInactiveValue" SG_ 371 ADC_SteerGainLevelTqCtrl 0;
BA_ "GenSigInvalidValue" SG_ 371 ADC_SteerGainLevelTqCtrl 0;
BA_ "GenSigSendType" SG_ 371 ADC_SteerGainLevelTqCtrl 1;
BA_ "GenSigStartValue" SG_ 371 ADC_SteerGainLevelTqCtrl 0;
BA_ "GenSigTimeoutValue" SG_ 371 ADC_SteerGainLevelTqCtrl 100;
BA_ "Remark" SG_ 371 ADC_SteerGainLevelTqCtrl "";
BA_ "EventCommandSignal" SG_ 1359 CCU_NMNodeAddress 0;
BA_ "GatewayedSignals" SG_ 1359 CCU_NMNodeAddress 0;
BA_ "GenSigInactiveValue" SG_ 1359 CCU_NMNodeAddress 0;
BA_ "GenSigInvalidValue" SG_ 1359 CCU_NMNodeAddress 0;
BA_ "GenSigSendType" SG_ 1359 CCU_NMNodeAddress 1;
BA_ "GenSigStartValue" SG_ 1359 CCU_NMNodeAddress 79;
BA_ "GenSigTimeoutValue" SG_ 1359 CCU_NMNodeAddress 0;
BA_ "Remark" SG_ 1359 CCU_NMNodeAddress "";
BA_ "EventCommandSignal" SG_ 1359 CCU_NMCBV 0;
BA_ "GatewayedSignals" SG_ 1359 CCU_NMCBV 0;
BA_ "GenSigInactiveValue" SG_ 1359 CCU_NMCBV 0;
BA_ "GenSigInvalidValue" SG_ 1359 CCU_NMCBV 0;
BA_ "GenSigSendType" SG_ 1359 CCU_NMCBV 1;
BA_ "GenSigStartValue" SG_ 1359 CCU_NMCBV 0;
BA_ "GenSigTimeoutValue" SG_ 1359 CCU_NMCBV 0;
BA_ "Remark" SG_ 1359 CCU_NMCBV "";
BA_ "EventCommandSignal" SG_ 1359 CCU_NMWakeupOrigin 0;
BA_ "GatewayedSignals" SG_ 1359 CCU_NMWakeupOrigin 0;
BA_ "GenSigInactiveValue" SG_ 1359 CCU_NMWakeupOrigin 0;
BA_ "GenSigInvalidValue" SG_ 1359 CCU_NMWakeupOrigin 0;
BA_ "GenSigSendType" SG_ 1359 CCU_NMWakeupOrigin 1;
BA_ "GenSigStartValue" SG_ 1359 CCU_NMWakeupOrigin 0;
BA_ "GenSigTimeoutValue" SG_ 1359 CCU_NMWakeupOrigin 0;
BA_ "Remark" SG_ 1359 CCU_NMWakeupOrigin "";
BA_ "EventCommandSignal" SG_ 1359 CCU_PNCInformation0 0;
BA_ "GatewayedSignals" SG_ 1359 CCU_PNCInformation0 0;
BA_ "GenSigInactiveValue" SG_ 1359 CCU_PNCInformation0 0;
BA_ "GenSigInvalidValue" SG_ 1359 CCU_PNCInformation0 0;
BA_ "GenSigSendType" SG_ 1359 CCU_PNCInformation0 1;
BA_ "GenSigStartValue" SG_ 1359 CCU_PNCInformation0 0;
BA_ "GenSigTimeoutValue" SG_ 1359 CCU_PNCInformation0 0;
BA_ "Remark" SG_ 1359 CCU_PNCInformation0 "";
BA_ "EventCommandSignal" SG_ 1359 CCU_PNCInformation1 0;
BA_ "GatewayedSignals" SG_ 1359 CCU_PNCInformation1 0;
BA_ "GenSigInactiveValue" SG_ 1359 CCU_PNCInformation1 0;
BA_ "GenSigInvalidValue" SG_ 1359 CCU_PNCInformation1 0;
BA_ "GenSigSendType" SG_ 1359 CCU_PNCInformation1 1;
BA_ "GenSigStartValue" SG_ 1359 CCU_PNCInformation1 0;
BA_ "GenSigTimeoutValue" SG_ 1359 CCU_PNCInformation1 0;
BA_ "Remark" SG_ 1359 CCU_PNCInformation1 "";
BA_ "EventCommandSignal" SG_ 1359 CCU_PNCInformation2 0;
BA_ "GatewayedSignals" SG_ 1359 CCU_PNCInformation2 0;
BA_ "GenSigInactiveValue" SG_ 1359 CCU_PNCInformation2 0;
BA_ "GenSigInvalidValue" SG_ 1359 CCU_PNCInformation2 0;
BA_ "GenSigSendType" SG_ 1359 CCU_PNCInformation2 1;
BA_ "GenSigStartValue" SG_ 1359 CCU_PNCInformation2 0;
BA_ "GenSigTimeoutValue" SG_ 1359 CCU_PNCInformation2 0;
BA_ "Remark" SG_ 1359 CCU_PNCInformation2 "";
BA_ "EventCommandSignal" SG_ 905 ICM_SetIACCSt 0;
BA_ "GatewayedSignals" SG_ 905 ICM_SetIACCSt 0;
BA_ "GenSigInactiveValue" SG_ 905 ICM_SetIACCSt 0;
BA_ "GenSigInvalidValue" SG_ 905 ICM_SetIACCSt 0;
BA_ "GenSigSendType" SG_ 905 ICM_SetIACCSt 1;
BA_ "GenSigStartValue" SG_ 905 ICM_SetIACCSt 0;
BA_ "GenSigTimeoutValue" SG_ 905 ICM_SetIACCSt 0;
BA_ "Remark" SG_ 905 ICM_SetIACCSt "";
BA_ "EventCommandSignal" SG_ 905 ICM_TotalOdometer 0;
BA_ "GatewayedSignals" SG_ 905 ICM_TotalOdometer 0;
BA_ "GenSigInactiveValue" SG_ 905 ICM_TotalOdometer 0;
BA_ "GenSigInvalidValue" SG_ 905 ICM_TotalOdometer 0;
BA_ "GenSigSendType" SG_ 905 ICM_TotalOdometer 1;
BA_ "GenSigStartValue" SG_ 905 ICM_TotalOdometer 0;
BA_ "EventCommandSignal" SG_ 905 ICM_VehInsSpd 0;
BA_ "GatewayedSignals" SG_ 905 ICM_VehInsSpd 0;
BA_ "GenSigInactiveValue" SG_ 905 ICM_VehInsSpd 0;
BA_ "GenSigInvalidValue" SG_ 905 ICM_VehInsSpd 255;
BA_ "GenSigSendType" SG_ 905 ICM_VehInsSpd 1;
BA_ "GenSigStartValue" SG_ 905 ICM_VehInsSpd 0;
BA_ "GenSigTimeoutValue" SG_ 905 ICM_VehInsSpd 0;
BA_ "Remark" SG_ 905 ICM_VehInsSpd "";
BA_ "EventCommandSignal" SG_ 905 ICM_VehInsSpd_accurate 0;
BA_ "GatewayedSignals" SG_ 905 ICM_VehInsSpd_accurate 0;
BA_ "GenSigInactiveValue" SG_ 905 ICM_VehInsSpd_accurate 0;
BA_ "GenSigInvalidValue" SG_ 905 ICM_VehInsSpd_accurate 2047;
BA_ "GenSigSendType" SG_ 905 ICM_VehInsSpd_accurate 1;
BA_ "GenSigStartValue" SG_ 905 ICM_VehInsSpd_accurate 0;
BA_ "GenSigTimeoutValue" SG_ 905 ICM_VehInsSpd_accurate 0;
BA_ "Remark" SG_ 905 ICM_VehInsSpd_accurate "";
BA_ "EventCommandSignal" SG_ 905 ICM_FuelAvaibleDriveDistance 0;
BA_ "GatewayedSignals" SG_ 905 ICM_FuelAvaibleDriveDistance 0;
BA_ "GenSigInactiveValue" SG_ 905 ICM_FuelAvaibleDriveDistance 0;
BA_ "GenSigInvalidValue" SG_ 905 ICM_FuelAvaibleDriveDistance 2047;
BA_ "GenSigSendType" SG_ 905 ICM_FuelAvaibleDriveDistance 1;
BA_ "GenSigStartValue" SG_ 905 ICM_FuelAvaibleDriveDistance 0;
BA_ "GenSigTimeoutValue" SG_ 905 ICM_FuelAvaibleDriveDistance 0;
BA_ "Remark" SG_ 905 ICM_FuelAvaibleDriveDistance "";
BA_ "EventCommandSignal" SG_ 905 ICM_TotalAvaibleDriveDistance 0;
BA_ "GatewayedSignals" SG_ 905 ICM_TotalAvaibleDriveDistance 0;
BA_ "GenSigInactiveValue" SG_ 905 ICM_TotalAvaibleDriveDistance 0;
BA_ "GenSigInvalidValue" SG_ 905 ICM_TotalAvaibleDriveDistance 2047;
BA_ "GenSigSendType" SG_ 905 ICM_TotalAvaibleDriveDistance 1;
BA_ "GenSigStartValue" SG_ 905 ICM_TotalAvaibleDriveDistance 0;
BA_ "GenSigTimeoutValue" SG_ 905 ICM_TotalAvaibleDriveDistance 0;
BA_ "Remark" SG_ 905 ICM_TotalAvaibleDriveDistance "";
BA_ "EventCommandSignal" SG_ 516 VCU_9_CRC 0;
BA_ "GatewayedSignals" SG_ 516 VCU_9_CRC 0;
BA_ "GenSigInactiveValue" SG_ 516 VCU_9_CRC 0;
BA_ "GenSigInvalidValue" SG_ 516 VCU_9_CRC 0;
BA_ "GenSigSendType" SG_ 516 VCU_9_CRC 1;
BA_ "GenSigStartValue" SG_ 516 VCU_9_CRC 0;
BA_ "GenSigTimeoutValue" SG_ 516 VCU_9_CRC 0;
BA_ "Remark" SG_ 516 VCU_9_CRC "涉及ID管理表";
BA_ "EventCommandSignal" SG_ 516 VCU_9_Counter 0;
BA_ "GatewayedSignals" SG_ 516 VCU_9_Counter 0;
BA_ "GenSigInactiveValue" SG_ 516 VCU_9_Counter 0;
BA_ "GenSigInvalidValue" SG_ 516 VCU_9_Counter 0;
BA_ "GenSigSendType" SG_ 516 VCU_9_Counter 1;
BA_ "GenSigStartValue" SG_ 516 VCU_9_Counter 0;
BA_ "GenSigTimeoutValue" SG_ 516 VCU_9_Counter 0;
BA_ "Remark" SG_ 516 VCU_9_Counter "涉及ID管理表";
BA_ "EventCommandSignal" SG_ 516 VCU_MaxDriveTorqVD 0;
BA_ "GatewayedSignals" SG_ 516 VCU_MaxDriveTorqVD 0;
BA_ "GenSigInactiveValue" SG_ 516 VCU_MaxDriveTorqVD 0;
BA_ "GenSigInvalidValue" SG_ 516 VCU_MaxDriveTorqVD 0;
BA_ "GenSigSendType" SG_ 516 VCU_MaxDriveTorqVD 1;
BA_ "GenSigStartValue" SG_ 516 VCU_MaxDriveTorqVD 0;
BA_ "GenSigTimeoutValue" SG_ 516 VCU_MaxDriveTorqVD 0;
BA_ "Remark" SG_ 516 VCU_MaxDriveTorqVD "涉及ID管理表";
BA_ "EventCommandSignal" SG_ 516 VCU_RecpTorqVD 0;
BA_ "GatewayedSignals" SG_ 516 VCU_RecpTorqVD 0;
BA_ "GenSigInactiveValue" SG_ 516 VCU_RecpTorqVD 0;
BA_ "GenSigInvalidValue" SG_ 516 VCU_RecpTorqVD 0;
BA_ "GenSigSendType" SG_ 516 VCU_RecpTorqVD 1;
BA_ "GenSigStartValue" SG_ 516 VCU_RecpTorqVD 0;
BA_ "GenSigTimeoutValue" SG_ 516 VCU_RecpTorqVD 0;
BA_ "Remark" SG_ 516 VCU_RecpTorqVD "涉及ID管理表";
BA_ "EventCommandSignal" SG_ 516 VCU_MaxRecpTorqVD 0;
BA_ "GatewayedSignals" SG_ 516 VCU_MaxRecpTorqVD 0;
BA_ "GenSigInactiveValue" SG_ 516 VCU_MaxRecpTorqVD 0;
BA_ "GenSigInvalidValue" SG_ 516 VCU_MaxRecpTorqVD 0;
BA_ "GenSigSendType" SG_ 516 VCU_MaxRecpTorqVD 1;
BA_ "GenSigStartValue" SG_ 516 VCU_MaxRecpTorqVD 0;
BA_ "GenSigTimeoutValue" SG_ 516 VCU_MaxRecpTorqVD 0;
BA_ "Remark" SG_ 516 VCU_MaxRecpTorqVD "涉及ID管理表";
BA_ "EventCommandSignal" SG_ 516 VCU_CrntGearLvl 0;
BA_ "GatewayedSignals" SG_ 516 VCU_CrntGearLvl 0;
BA_ "GenSigInactiveValue" SG_ 516 VCU_CrntGearLvl 0;
BA_ "GenSigInvalidValue" SG_ 516 VCU_CrntGearLvl 0;
BA_ "GenSigSendType" SG_ 516 VCU_CrntGearLvl 1;
BA_ "GenSigStartValue" SG_ 516 VCU_CrntGearLvl 0;
BA_ "GenSigTimeoutValue" SG_ 516 VCU_CrntGearLvl 0;
BA_ "Remark" SG_ 516 VCU_CrntGearLvl "涉及ID管理表";
BA_ "EventCommandSignal" SG_ 516 VCU_CrntGearLvlVD 0;
BA_ "GatewayedSignals" SG_ 516 VCU_CrntGearLvlVD 0;
BA_ "GenSigInactiveValue" SG_ 516 VCU_CrntGearLvlVD 0;
BA_ "GenSigInvalidValue" SG_ 516 VCU_CrntGearLvlVD 0;
BA_ "GenSigSendType" SG_ 516 VCU_CrntGearLvlVD 1;
BA_ "GenSigStartValue" SG_ 516 VCU_CrntGearLvlVD 0;
BA_ "GenSigTimeoutValue" SG_ 516 VCU_CrntGearLvlVD 0;
BA_ "Remark" SG_ 516 VCU_CrntGearLvlVD "涉及ID管理表";
BA_ "EventCommandSignal" SG_ 516 VCU_BrkPedPstVD 0;
BA_ "GatewayedSignals" SG_ 516 VCU_BrkPedPstVD 0;
BA_ "GenSigInactiveValue" SG_ 516 VCU_BrkPedPstVD 0;
BA_ "GenSigInvalidValue" SG_ 516 VCU_BrkPedPstVD 0;
BA_ "GenSigSendType" SG_ 516 VCU_BrkPedPstVD 1;
BA_ "GenSigStartValue" SG_ 516 VCU_BrkPedPstVD 0;
BA_ "GenSigTimeoutValue" SG_ 516 VCU_BrkPedPstVD 0;
BA_ "Remark" SG_ 516 VCU_BrkPedPstVD "涉及ID管理表";
BA_ "EventCommandSignal" SG_ 516 VCU_BrkPedPst 0;
BA_ "GatewayedSignals" SG_ 516 VCU_BrkPedPst 0;
BA_ "GenSigInactiveValue" SG_ 516 VCU_BrkPedPst 0;
BA_ "GenSigInvalidValue" SG_ 516 VCU_BrkPedPst 0;
BA_ "GenSigSendType" SG_ 516 VCU_BrkPedPst 1;
BA_ "GenSigStartValue" SG_ 516 VCU_BrkPedPst 0;
BA_ "GenSigTimeoutValue" SG_ 516 VCU_BrkPedPst 0;
BA_ "Remark" SG_ 516 VCU_BrkPedPst "涉及ID管理表";
BA_ "EventCommandSignal" SG_ 516 VCU_GearIntervern 0;
BA_ "GatewayedSignals" SG_ 516 VCU_GearIntervern 0;
BA_ "GenSigInactiveValue" SG_ 516 VCU_GearIntervern 0;
BA_ "GenSigInvalidValue" SG_ 516 VCU_GearIntervern 0;
BA_ "GenSigSendType" SG_ 516 VCU_GearIntervern 1;
BA_ "GenSigStartValue" SG_ 516 VCU_GearIntervern 0;
BA_ "GenSigTimeoutValue" SG_ 516 VCU_GearIntervern 0;
BA_ "Remark" SG_ 516 VCU_GearIntervern "涉及ID管理表";
BA_ "EventCommandSignal" SG_ 516 VCU_AccPedalVirtPstVD 0;
BA_ "GatewayedSignals" SG_ 516 VCU_AccPedalVirtPstVD 0;
BA_ "GenSigInactiveValue" SG_ 516 VCU_AccPedalVirtPstVD 0;
BA_ "GenSigInvalidValue" SG_ 516 VCU_AccPedalVirtPstVD 0;
BA_ "GenSigSendType" SG_ 516 VCU_AccPedalVirtPstVD 1;
BA_ "GenSigStartValue" SG_ 516 VCU_AccPedalVirtPstVD 0;
BA_ "GenSigTimeoutValue" SG_ 516 VCU_AccPedalVirtPstVD 0;
BA_ "Remark" SG_ 516 VCU_AccPedalVirtPstVD "涉及ID管理表";
BA_ "EventCommandSignal" SG_ 516 VCU_ActVehWheelTorq 0;
BA_ "GatewayedSignals" SG_ 516 VCU_ActVehWheelTorq 0;
BA_ "GenSigInactiveValue" SG_ 516 VCU_ActVehWheelTorq 0;
BA_ "GenSigInvalidValue" SG_ 516 VCU_ActVehWheelTorq 32767;
BA_ "GenSigSendType" SG_ 516 VCU_ActVehWheelTorq 1;
BA_ "GenSigStartValue" SG_ 516 VCU_ActVehWheelTorq 32766;
BA_ "GenSigTimeoutValue" SG_ 516 VCU_ActVehWheelTorq 0;
BA_ "Remark" SG_ 516 VCU_ActVehWheelTorq "涉及ID管理表";
BA_ "EventCommandSignal" SG_ 516 VCU_MaxRecpTorq 0;
BA_ "GatewayedSignals" SG_ 516 VCU_MaxRecpTorq 0;
BA_ "GenSigInactiveValue" SG_ 516 VCU_MaxRecpTorq 0;
BA_ "GenSigInvalidValue" SG_ 516 VCU_MaxRecpTorq 0;
BA_ "GenSigSendType" SG_ 516 VCU_MaxRecpTorq 1;
BA_ "GenSigStartValue" SG_ 516 VCU_MaxRecpTorq 0;
BA_ "GenSigTimeoutValue" SG_ 516 VCU_MaxRecpTorq 0;
BA_ "Remark" SG_ 516 VCU_MaxRecpTorq "涉及ID管理表";
BA_ "EventCommandSignal" SG_ 516 VCU_AccPedalVirtPst 0;
BA_ "GatewayedSignals" SG_ 516 VCU_AccPedalVirtPst 0;
BA_ "GenSigInactiveValue" SG_ 516 VCU_AccPedalVirtPst 0;
BA_ "GenSigInvalidValue" SG_ 516 VCU_AccPedalVirtPst 0;
BA_ "GenSigSendType" SG_ 516 VCU_AccPedalVirtPst 1;
BA_ "GenSigStartValue" SG_ 516 VCU_AccPedalVirtPst 0;
BA_ "GenSigTimeoutValue" SG_ 516 VCU_AccPedalVirtPst 0;
BA_ "Remark" SG_ 516 VCU_AccPedalVirtPst "涉及ID管理表";
BA_ "EventCommandSignal" SG_ 516 VCU_BrkPedalSt 0;
BA_ "GatewayedSignals" SG_ 516 VCU_BrkPedalSt 0;
BA_ "GenSigInactiveValue" SG_ 516 VCU_BrkPedalSt 0;
BA_ "GenSigInvalidValue" SG_ 516 VCU_BrkPedalSt 0;
BA_ "GenSigSendType" SG_ 516 VCU_BrkPedalSt 1;
BA_ "GenSigStartValue" SG_ 516 VCU_BrkPedalSt 0;
BA_ "GenSigTimeoutValue" SG_ 516 VCU_BrkPedalSt 0;
BA_ "Remark" SG_ 516 VCU_BrkPedalSt "涉及ID管理表";
BA_ "EventCommandSignal" SG_ 516 VCU_BrkPedalStVD 0;
BA_ "GatewayedSignals" SG_ 516 VCU_BrkPedalStVD 0;
BA_ "GenSigInactiveValue" SG_ 516 VCU_BrkPedalStVD 0;
BA_ "GenSigInvalidValue" SG_ 516 VCU_BrkPedalStVD 0;
BA_ "GenSigSendType" SG_ 516 VCU_BrkPedalStVD 1;
BA_ "GenSigStartValue" SG_ 516 VCU_BrkPedalStVD 0;
BA_ "GenSigTimeoutValue" SG_ 516 VCU_BrkPedalStVD 0;
BA_ "Remark" SG_ 516 VCU_BrkPedalStVD "涉及ID管理表";
BA_ "EventCommandSignal" SG_ 516 VCU_ACCLimitOperatingSt 0;
BA_ "GatewayedSignals" SG_ 516 VCU_ACCLimitOperatingSt 0;
BA_ "GenSigInactiveValue" SG_ 516 VCU_ACCLimitOperatingSt 0;
BA_ "GenSigInvalidValue" SG_ 516 VCU_ACCLimitOperatingSt 0;
BA_ "GenSigSendType" SG_ 516 VCU_ACCLimitOperatingSt 1;
BA_ "GenSigStartValue" SG_ 516 VCU_ACCLimitOperatingSt 0;
BA_ "GenSigTimeoutValue" SG_ 516 VCU_ACCLimitOperatingSt 0;
BA_ "Remark" SG_ 516 VCU_ACCLimitOperatingSt "涉及ID管理表";
BA_ "EventCommandSignal" SG_ 516 VCU_AccButtInfo 0;
BA_ "GatewayedSignals" SG_ 516 VCU_AccButtInfo 0;
BA_ "GenSigInactiveValue" SG_ 516 VCU_AccButtInfo 0;
BA_ "GenSigInvalidValue" SG_ 516 VCU_AccButtInfo 0;
BA_ "GenSigSendType" SG_ 516 VCU_AccButtInfo 1;
BA_ "GenSigStartValue" SG_ 516 VCU_AccButtInfo 0;
BA_ "GenSigTimeoutValue" SG_ 516 VCU_AccButtInfo 0;
BA_ "Remark" SG_ 516 VCU_AccButtInfo "涉及ID管理表";
BA_ "EventCommandSignal" SG_ 516 VCU_ACCmaxSpdLimit 0;
BA_ "GatewayedSignals" SG_ 516 VCU_ACCmaxSpdLimit 0;
BA_ "GenSigInactiveValue" SG_ 516 VCU_ACCmaxSpdLimit 0;
BA_ "GenSigInvalidValue" SG_ 516 VCU_ACCmaxSpdLimit 0;
BA_ "GenSigSendType" SG_ 516 VCU_ACCmaxSpdLimit 1;
BA_ "GenSigStartValue" SG_ 516 VCU_ACCmaxSpdLimit 0;
BA_ "GenSigTimeoutValue" SG_ 516 VCU_ACCmaxSpdLimit 0;
BA_ "Remark" SG_ 516 VCU_ACCmaxSpdLimit "涉及ID管理表";
BA_ "EventCommandSignal" SG_ 516 VCU_RecpTorqFAVD 0;
BA_ "GatewayedSignals" SG_ 516 VCU_RecpTorqFAVD 0;
BA_ "GenSigInactiveValue" SG_ 516 VCU_RecpTorqFAVD 0;
BA_ "GenSigInvalidValue" SG_ 516 VCU_RecpTorqFAVD 0;
BA_ "GenSigSendType" SG_ 516 VCU_RecpTorqFAVD 1;
BA_ "GenSigStartValue" SG_ 516 VCU_RecpTorqFAVD 0;
BA_ "GenSigTimeoutValue" SG_ 516 VCU_RecpTorqFAVD 0;
BA_ "Remark" SG_ 516 VCU_RecpTorqFAVD "涉及ID管理表";
BA_ "EventCommandSignal" SG_ 516 VCU_RecpTorqRAVD 0;
BA_ "GatewayedSignals" SG_ 516 VCU_RecpTorqRAVD 0;
BA_ "GenSigInactiveValue" SG_ 516 VCU_RecpTorqRAVD 0;
BA_ "GenSigInvalidValue" SG_ 516 VCU_RecpTorqRAVD 0;
BA_ "GenSigSendType" SG_ 516 VCU_RecpTorqRAVD 1;
BA_ "GenSigStartValue" SG_ 516 VCU_RecpTorqRAVD 0;
BA_ "GenSigTimeoutValue" SG_ 516 VCU_RecpTorqRAVD 0;
BA_ "Remark" SG_ 516 VCU_RecpTorqRAVD "涉及ID管理表";
BA_ "EventCommandSignal" SG_ 516 VCU_MaxRecpTorqFAVD 0;
BA_ "GatewayedSignals" SG_ 516 VCU_MaxRecpTorqFAVD 0;
BA_ "GenSigInactiveValue" SG_ 516 VCU_MaxRecpTorqFAVD 0;
BA_ "GenSigInvalidValue" SG_ 516 VCU_MaxRecpTorqFAVD 0;
BA_ "GenSigSendType" SG_ 516 VCU_MaxRecpTorqFAVD 1;
BA_ "GenSigStartValue" SG_ 516 VCU_MaxRecpTorqFAVD 0;
BA_ "GenSigTimeoutValue" SG_ 516 VCU_MaxRecpTorqFAVD 0;
BA_ "Remark" SG_ 516 VCU_MaxRecpTorqFAVD "涉及ID管理表";
BA_ "EventCommandSignal" SG_ 516 VCU_MaxRecpTorqRAVD 0;
BA_ "GatewayedSignals" SG_ 516 VCU_MaxRecpTorqRAVD 0;
BA_ "GenSigInactiveValue" SG_ 516 VCU_MaxRecpTorqRAVD 0;
BA_ "GenSigInvalidValue" SG_ 516 VCU_MaxRecpTorqRAVD 0;
BA_ "GenSigSendType" SG_ 516 VCU_MaxRecpTorqRAVD 1;
BA_ "GenSigStartValue" SG_ 516 VCU_MaxRecpTorqRAVD 0;
BA_ "GenSigTimeoutValue" SG_ 516 VCU_MaxRecpTorqRAVD 0;
BA_ "Remark" SG_ 516 VCU_MaxRecpTorqRAVD "涉及ID管理表";
BA_ "EventCommandSignal" SG_ 516 VCU_RecpTorq 0;
BA_ "GatewayedSignals" SG_ 516 VCU_RecpTorq 0;
BA_ "GenSigInactiveValue" SG_ 516 VCU_RecpTorq 0;
BA_ "GenSigInvalidValue" SG_ 516 VCU_RecpTorq 0;
BA_ "GenSigSendType" SG_ 516 VCU_RecpTorq 1;
BA_ "GenSigStartValue" SG_ 516 VCU_RecpTorq 0;
BA_ "GenSigTimeoutValue" SG_ 516 VCU_RecpTorq 0;
BA_ "Remark" SG_ 516 VCU_RecpTorq "涉及ID管理表";
BA_ "EventCommandSignal" SG_ 516 VCU_MaxDriveTorq 0;
BA_ "GatewayedSignals" SG_ 516 VCU_MaxDriveTorq 0;
BA_ "GenSigInactiveValue" SG_ 516 VCU_MaxDriveTorq 0;
BA_ "GenSigInvalidValue" SG_ 516 VCU_MaxDriveTorq 16383;
BA_ "GenSigSendType" SG_ 516 VCU_MaxDriveTorq 1;
BA_ "GenSigStartValue" SG_ 516 VCU_MaxDriveTorq 16382;
BA_ "GenSigTimeoutValue" SG_ 516 VCU_MaxDriveTorq 0;
BA_ "Remark" SG_ 516 VCU_MaxDriveTorq "涉及ID管理表";
BA_ "EventCommandSignal" SG_ 516 VCU_RecpTorqFA 0;
BA_ "GatewayedSignals" SG_ 516 VCU_RecpTorqFA 0;
BA_ "GenSigInactiveValue" SG_ 516 VCU_RecpTorqFA 0;
BA_ "GenSigInvalidValue" SG_ 516 VCU_RecpTorqFA 0;
BA_ "GenSigSendType" SG_ 516 VCU_RecpTorqFA 1;
BA_ "GenSigStartValue" SG_ 516 VCU_RecpTorqFA 0;
BA_ "GenSigTimeoutValue" SG_ 516 VCU_RecpTorqFA 0;
BA_ "Remark" SG_ 516 VCU_RecpTorqFA "涉及ID管理表";
BA_ "EventCommandSignal" SG_ 516 VCU_RecpTorqRA 0;
BA_ "GatewayedSignals" SG_ 516 VCU_RecpTorqRA 0;
BA_ "GenSigInactiveValue" SG_ 516 VCU_RecpTorqRA 0;
BA_ "GenSigInvalidValue" SG_ 516 VCU_RecpTorqRA 0;
BA_ "GenSigSendType" SG_ 516 VCU_RecpTorqRA 1;
BA_ "GenSigStartValue" SG_ 516 VCU_RecpTorqRA 0;
BA_ "GenSigTimeoutValue" SG_ 516 VCU_RecpTorqRA 0;
BA_ "Remark" SG_ 516 VCU_RecpTorqRA "涉及ID管理表";
BA_ "EventCommandSignal" SG_ 516 VCU_MaxRecpTorqFA 0;
BA_ "GatewayedSignals" SG_ 516 VCU_MaxRecpTorqFA 0;
BA_ "GenSigInactiveValue" SG_ 516 VCU_MaxRecpTorqFA 0;
BA_ "GenSigInvalidValue" SG_ 516 VCU_MaxRecpTorqFA 0;
BA_ "GenSigSendType" SG_ 516 VCU_MaxRecpTorqFA 1;
BA_ "GenSigStartValue" SG_ 516 VCU_MaxRecpTorqFA 0;
BA_ "GenSigTimeoutValue" SG_ 516 VCU_MaxRecpTorqFA 0;
BA_ "Remark" SG_ 516 VCU_MaxRecpTorqFA "涉及ID管理表";
BA_ "EventCommandSignal" SG_ 516 VCU_MaxRecpTorqRA 0;
BA_ "GatewayedSignals" SG_ 516 VCU_MaxRecpTorqRA 0;
BA_ "GenSigInactiveValue" SG_ 516 VCU_MaxRecpTorqRA 0;
BA_ "GenSigInvalidValue" SG_ 516 VCU_MaxRecpTorqRA 0;
BA_ "GenSigSendType" SG_ 516 VCU_MaxRecpTorqRA 1;
BA_ "GenSigStartValue" SG_ 516 VCU_MaxRecpTorqRA 0;
BA_ "GenSigTimeoutValue" SG_ 516 VCU_MaxRecpTorqRA 0;
BA_ "Remark" SG_ 516 VCU_MaxRecpTorqRA "涉及ID管理表";
BA_ "EventCommandSignal" SG_ 516 VCU_BcsDecelEnable 0;
BA_ "GatewayedSignals" SG_ 516 VCU_BcsDecelEnable 0;
BA_ "GenSigInactiveValue" SG_ 516 VCU_BcsDecelEnable 0;
BA_ "GenSigInvalidValue" SG_ 516 VCU_BcsDecelEnable 0;
BA_ "GenSigSendType" SG_ 516 VCU_BcsDecelEnable 1;
BA_ "GenSigStartValue" SG_ 516 VCU_BcsDecelEnable 0;
BA_ "GenSigTimeoutValue" SG_ 516 VCU_BcsDecelEnable 0;
BA_ "Remark" SG_ 516 VCU_BcsDecelEnable "涉及ID管理表";
BA_ "EventCommandSignal" SG_ 516 VCU_CrntGearNoTrans 0;
BA_ "GatewayedSignals" SG_ 516 VCU_CrntGearNoTrans 0;
BA_ "GenSigInactiveValue" SG_ 516 VCU_CrntGearNoTrans 0;
BA_ "GenSigInvalidValue" SG_ 516 VCU_CrntGearNoTrans 0;
BA_ "GenSigSendType" SG_ 516 VCU_CrntGearNoTrans 1;
BA_ "GenSigStartValue" SG_ 516 VCU_CrntGearNoTrans 0;
BA_ "GenSigTimeoutValue" SG_ 516 VCU_CrntGearNoTrans 0;
BA_ "Remark" SG_ 516 VCU_CrntGearNoTrans "涉及ID管理表";
BA_ "EventCommandSignal" SG_ 516 VCU_EzTSt 0;
BA_ "GatewayedSignals" SG_ 516 VCU_EzTSt 0;
BA_ "GenSigInactiveValue" SG_ 516 VCU_EzTSt 0;
BA_ "GenSigInvalidValue" SG_ 516 VCU_EzTSt 0;
BA_ "GenSigSendType" SG_ 516 VCU_EzTSt 1;
BA_ "GenSigStartValue" SG_ 516 VCU_EzTSt 0;
BA_ "GenSigTimeoutValue" SG_ 516 VCU_EzTSt 0;
BA_ "Remark" SG_ 516 VCU_EzTSt "涉及ID管理表";
BA_ "EventCommandSignal" SG_ 516 VCU_ITASSt 0;
BA_ "GatewayedSignals" SG_ 516 VCU_ITASSt 0;
BA_ "GenSigInactiveValue" SG_ 516 VCU_ITASSt 0;
BA_ "GenSigInvalidValue" SG_ 516 VCU_ITASSt 0;
BA_ "GenSigSendType" SG_ 516 VCU_ITASSt 1;
BA_ "GenSigStartValue" SG_ 516 VCU_ITASSt 0;
BA_ "GenSigTimeoutValue" SG_ 516 VCU_ITASSt 0;
BA_ "Remark" SG_ 516 VCU_ITASSt "涉及ID管理表";
BA_ "EventCommandSignal" SG_ 909 LCK_HoodAjarSt 0;
BA_ "GatewayedSignals" SG_ 909 LCK_HoodAjarSt 0;
BA_ "GenSigInactiveValue" SG_ 909 LCK_HoodAjarSt 0;
BA_ "GenSigInvalidValue" SG_ 909 LCK_HoodAjarSt 0;
BA_ "GenSigSendType" SG_ 909 LCK_HoodAjarSt 0;
BA_ "GenSigStartValue" SG_ 909 LCK_HoodAjarSt 0;
BA_ "GenSigTimeoutValue" SG_ 909 LCK_HoodAjarSt 0;
BA_ "Remark" SG_ 909 LCK_HoodAjarSt "";
BA_ "EventCommandSignal" SG_ 909 LCK_FrontLeftDoorAjarSt 0;
BA_ "GatewayedSignals" SG_ 909 LCK_FrontLeftDoorAjarSt 0;
BA_ "GenSigInactiveValue" SG_ 909 LCK_FrontLeftDoorAjarSt 0;
BA_ "GenSigInvalidValue" SG_ 909 LCK_FrontLeftDoorAjarSt 0;
BA_ "GenSigSendType" SG_ 909 LCK_FrontLeftDoorAjarSt 0;
BA_ "GenSigStartValue" SG_ 909 LCK_FrontLeftDoorAjarSt 0;
BA_ "GenSigTimeoutValue" SG_ 909 LCK_FrontLeftDoorAjarSt 0;
BA_ "Remark" SG_ 909 LCK_FrontLeftDoorAjarSt "";
BA_ "EventCommandSignal" SG_ 909 LCK_FrontRightDoorAjarSt 0;
BA_ "GatewayedSignals" SG_ 909 LCK_FrontRightDoorAjarSt 0;
BA_ "GenSigInactiveValue" SG_ 909 LCK_FrontRightDoorAjarSt 0;
BA_ "GenSigInvalidValue" SG_ 909 LCK_FrontRightDoorAjarSt 0;
BA_ "GenSigSendType" SG_ 909 LCK_FrontRightDoorAjarSt 0;
BA_ "GenSigStartValue" SG_ 909 LCK_FrontRightDoorAjarSt 0;
BA_ "GenSigTimeoutValue" SG_ 909 LCK_FrontRightDoorAjarSt 0;
BA_ "Remark" SG_ 909 LCK_FrontRightDoorAjarSt "";
BA_ "EventCommandSignal" SG_ 909 LCK_RearLeftDoorAjarSt 0;
BA_ "GatewayedSignals" SG_ 909 LCK_RearLeftDoorAjarSt 0;
BA_ "GenSigInactiveValue" SG_ 909 LCK_RearLeftDoorAjarSt 0;
BA_ "GenSigInvalidValue" SG_ 909 LCK_RearLeftDoorAjarSt 0;
BA_ "GenSigSendType" SG_ 909 LCK_RearLeftDoorAjarSt 0;
BA_ "GenSigStartValue" SG_ 909 LCK_RearLeftDoorAjarSt 0;
BA_ "GenSigTimeoutValue" SG_ 909 LCK_RearLeftDoorAjarSt 0;
BA_ "Remark" SG_ 909 LCK_RearLeftDoorAjarSt "";
BA_ "EventCommandSignal" SG_ 909 LCK_RearRightDoorAjarSt 0;
BA_ "GatewayedSignals" SG_ 909 LCK_RearRightDoorAjarSt 0;
BA_ "GenSigInactiveValue" SG_ 909 LCK_RearRightDoorAjarSt 0;
BA_ "GenSigInvalidValue" SG_ 909 LCK_RearRightDoorAjarSt 0;
BA_ "GenSigSendType" SG_ 909 LCK_RearRightDoorAjarSt 0;
BA_ "GenSigStartValue" SG_ 909 LCK_RearRightDoorAjarSt 0;
BA_ "GenSigTimeoutValue" SG_ 909 LCK_RearRightDoorAjarSt 0;
BA_ "Remark" SG_ 909 LCK_RearRightDoorAjarSt "";
BA_ "EventCommandSignal" SG_ 909 LCK_TrunkAjarSt 0;
BA_ "GatewayedSignals" SG_ 909 LCK_TrunkAjarSt 0;
BA_ "GenSigInactiveValue" SG_ 909 LCK_TrunkAjarSt 0;
BA_ "GenSigInvalidValue" SG_ 909 LCK_TrunkAjarSt 0;
BA_ "GenSigSendType" SG_ 909 LCK_TrunkAjarSt 0;
BA_ "GenSigStartValue" SG_ 909 LCK_TrunkAjarSt 0;
BA_ "GenSigTimeoutValue" SG_ 909 LCK_TrunkAjarSt 0;
BA_ "Remark" SG_ 909 LCK_TrunkAjarSt "";
BA_ "EventCommandSignal" SG_ 909 LCK_FrontLeftDoorLockSt 0;
BA_ "GatewayedSignals" SG_ 909 LCK_FrontLeftDoorLockSt 0;
BA_ "GenSigInactiveValue" SG_ 909 LCK_FrontLeftDoorLockSt 0;
BA_ "GenSigInvalidValue" SG_ 909 LCK_FrontLeftDoorLockSt 0;
BA_ "GenSigSendType" SG_ 909 LCK_FrontLeftDoorLockSt 0;
BA_ "GenSigStartValue" SG_ 909 LCK_FrontLeftDoorLockSt 0;
BA_ "GenSigTimeoutValue" SG_ 909 LCK_FrontLeftDoorLockSt 0;
BA_ "Remark" SG_ 909 LCK_FrontLeftDoorLockSt "";
BA_ "EventCommandSignal" SG_ 909 LCK_FrontRightDoorLockSt 0;
BA_ "GatewayedSignals" SG_ 909 LCK_FrontRightDoorLockSt 0;
BA_ "GenSigInactiveValue" SG_ 909 LCK_FrontRightDoorLockSt 0;
BA_ "GenSigInvalidValue" SG_ 909 LCK_FrontRightDoorLockSt 0;
BA_ "GenSigSendType" SG_ 909 LCK_FrontRightDoorLockSt 0;
BA_ "GenSigStartValue" SG_ 909 LCK_FrontRightDoorLockSt 0;
BA_ "GenSigTimeoutValue" SG_ 909 LCK_FrontRightDoorLockSt 0;
BA_ "Remark" SG_ 909 LCK_FrontRightDoorLockSt "";
BA_ "EventCommandSignal" SG_ 909 LCK_RearLeftDoorLockSt 0;
BA_ "GatewayedSignals" SG_ 909 LCK_RearLeftDoorLockSt 0;
BA_ "GenSigInactiveValue" SG_ 909 LCK_RearLeftDoorLockSt 0;
BA_ "GenSigInvalidValue" SG_ 909 LCK_RearLeftDoorLockSt 0;
BA_ "GenSigSendType" SG_ 909 LCK_RearLeftDoorLockSt 0;
BA_ "GenSigStartValue" SG_ 909 LCK_RearLeftDoorLockSt 0;
BA_ "GenSigTimeoutValue" SG_ 909 LCK_RearLeftDoorLockSt 0;
BA_ "Remark" SG_ 909 LCK_RearLeftDoorLockSt "";
BA_ "EventCommandSignal" SG_ 909 LCK_RearRightDoorLockSt 0;
BA_ "GatewayedSignals" SG_ 909 LCK_RearRightDoorLockSt 0;
BA_ "GenSigInactiveValue" SG_ 909 LCK_RearRightDoorLockSt 0;
BA_ "GenSigInvalidValue" SG_ 909 LCK_RearRightDoorLockSt 0;
BA_ "GenSigSendType" SG_ 909 LCK_RearRightDoorLockSt 0;
BA_ "GenSigStartValue" SG_ 909 LCK_RearRightDoorLockSt 0;
BA_ "GenSigTimeoutValue" SG_ 909 LCK_RearRightDoorLockSt 0;
BA_ "Remark" SG_ 909 LCK_RearRightDoorLockSt "";
BA_ "EventCommandSignal" SG_ 909 LCK_RearLeftChildSaftyLockSt 0;
BA_ "GatewayedSignals" SG_ 909 LCK_RearLeftChildSaftyLockSt 0;
BA_ "GenSigInactiveValue" SG_ 909 LCK_RearLeftChildSaftyLockSt 0;
BA_ "GenSigInvalidValue" SG_ 909 LCK_RearLeftChildSaftyLockSt 0;
BA_ "GenSigSendType" SG_ 909 LCK_RearLeftChildSaftyLockSt 0;
BA_ "GenSigStartValue" SG_ 909 LCK_RearLeftChildSaftyLockSt 0;
BA_ "GenSigTimeoutValue" SG_ 909 LCK_RearLeftChildSaftyLockSt 0;
BA_ "Remark" SG_ 909 LCK_RearLeftChildSaftyLockSt "";
BA_ "EventCommandSignal" SG_ 909 LCK_RearRightChildSaftyLockSt 0;
BA_ "GatewayedSignals" SG_ 909 LCK_RearRightChildSaftyLockSt 0;
BA_ "GenSigInactiveValue" SG_ 909 LCK_RearRightChildSaftyLockSt 0;
BA_ "GenSigInvalidValue" SG_ 909 LCK_RearRightChildSaftyLockSt 0;
BA_ "GenSigSendType" SG_ 909 LCK_RearRightChildSaftyLockSt 0;
BA_ "GenSigStartValue" SG_ 909 LCK_RearRightChildSaftyLockSt 0;
BA_ "GenSigTimeoutValue" SG_ 909 LCK_RearRightChildSaftyLockSt 0;
BA_ "Remark" SG_ 909 LCK_RearRightChildSaftyLockSt "";
BA_ "EventCommandSignal" SG_ 909 EMS_EngStForPHEV 0;
BA_ "GatewayedSignals" SG_ 909 EMS_EngStForPHEV 0;
BA_ "GenSigInactiveValue" SG_ 909 EMS_EngStForPHEV 0;
BA_ "GenSigInvalidValue" SG_ 909 EMS_EngStForPHEV 0;
BA_ "GenSigSendType" SG_ 909 EMS_EngStForPHEV 1;
BA_ "GenSigStartValue" SG_ 909 EMS_EngStForPHEV 0;
BA_ "GenSigTimeoutValue" SG_ 909 EMS_EngStForPHEV 0;
BA_ "Remark" SG_ 909 EMS_EngStForPHEV "";
BA_ "EventCommandSignal" SG_ 909 WCM_Reminder 0;
BA_ "GatewayedSignals" SG_ 909 WCM_Reminder 0;
BA_ "GenSigInactiveValue" SG_ 909 WCM_Reminder 0;
BA_ "GenSigInvalidValue" SG_ 909 WCM_Reminder 0;
BA_ "GenSigSendType" SG_ 909 WCM_Reminder 1;
BA_ "GenSigStartValue" SG_ 909 WCM_Reminder 0;
BA_ "GenSigTimeoutValue" SG_ 909 WCM_Reminder 0;
BA_ "Remark" SG_ 909 WCM_Reminder "";
BA_ "EventCommandSignal" SG_ 909 WCM_ChargingSt 0;
BA_ "GatewayedSignals" SG_ 909 WCM_ChargingSt 0;
BA_ "GenSigInactiveValue" SG_ 909 WCM_ChargingSt 0;
BA_ "GenSigInvalidValue" SG_ 909 WCM_ChargingSt 0;
BA_ "GenSigSendType" SG_ 909 WCM_ChargingSt 1;
BA_ "GenSigStartValue" SG_ 909 WCM_ChargingSt 0;
BA_ "GenSigTimeoutValue" SG_ 909 WCM_ChargingSt 0;
BA_ "Remark" SG_ 909 WCM_ChargingSt "";
BA_ "EventCommandSignal" SG_ 909 LCK_FrontLeftDoorHandlePosition 0;
BA_ "GatewayedSignals" SG_ 909 LCK_FrontLeftDoorHandlePosition 0;
BA_ "GenSigInactiveValue" SG_ 909 LCK_FrontLeftDoorHandlePosition 0;
BA_ "GenSigInvalidValue" SG_ 909 LCK_FrontLeftDoorHandlePosition 255;
BA_ "GenSigSendType" SG_ 909 LCK_FrontLeftDoorHandlePosition 0;
BA_ "GenSigStartValue" SG_ 909 LCK_FrontLeftDoorHandlePosition 0;
BA_ "GenSigTimeoutValue" SG_ 909 LCK_FrontLeftDoorHandlePosition 0;
BA_ "Remark" SG_ 909 LCK_FrontLeftDoorHandlePosition "";
BA_ "EventCommandSignal" SG_ 909 LCK_FrontRightDoorHandlePosition 0;
BA_ "GatewayedSignals" SG_ 909 LCK_FrontRightDoorHandlePosition 0;
BA_ "GenSigInactiveValue" SG_ 909 LCK_FrontRightDoorHandlePosition 0;
BA_ "GenSigInvalidValue" SG_ 909 LCK_FrontRightDoorHandlePosition 255;
BA_ "GenSigSendType" SG_ 909 LCK_FrontRightDoorHandlePosition 0;
BA_ "GenSigStartValue" SG_ 909 LCK_FrontRightDoorHandlePosition 0;
BA_ "GenSigTimeoutValue" SG_ 909 LCK_FrontRightDoorHandlePosition 0;
BA_ "Remark" SG_ 909 LCK_FrontRightDoorHandlePosition "";
BA_ "EventCommandSignal" SG_ 909 LCK_RearLeftDoorHandlePosition 0;
BA_ "GatewayedSignals" SG_ 909 LCK_RearLeftDoorHandlePosition 0;
BA_ "GenSigInactiveValue" SG_ 909 LCK_RearLeftDoorHandlePosition 0;
BA_ "GenSigInvalidValue" SG_ 909 LCK_RearLeftDoorHandlePosition 255;
BA_ "GenSigSendType" SG_ 909 LCK_RearLeftDoorHandlePosition 0;
BA_ "GenSigStartValue" SG_ 909 LCK_RearLeftDoorHandlePosition 0;
BA_ "GenSigTimeoutValue" SG_ 909 LCK_RearLeftDoorHandlePosition 0;
BA_ "Remark" SG_ 909 LCK_RearLeftDoorHandlePosition "";
BA_ "EventCommandSignal" SG_ 909 LCK_RearRightDoorHandlePosition 0;
BA_ "GatewayedSignals" SG_ 909 LCK_RearRightDoorHandlePosition 0;
BA_ "GenSigInactiveValue" SG_ 909 LCK_RearRightDoorHandlePosition 0;
BA_ "GenSigInvalidValue" SG_ 909 LCK_RearRightDoorHandlePosition 255;
BA_ "GenSigSendType" SG_ 909 LCK_RearRightDoorHandlePosition 0;
BA_ "GenSigStartValue" SG_ 909 LCK_RearRightDoorHandlePosition 0;
BA_ "GenSigTimeoutValue" SG_ 909 LCK_RearRightDoorHandlePosition 0;
BA_ "Remark" SG_ 909 LCK_RearRightDoorHandlePosition "";
BA_ "EventCommandSignal" SG_ 909 WW_RWPMotorSt 0;
BA_ "GatewayedSignals" SG_ 909 WW_RWPMotorSt 0;
BA_ "GenSigInactiveValue" SG_ 909 WW_RWPMotorSt 0;
BA_ "GenSigInvalidValue" SG_ 909 WW_RWPMotorSt 0;
BA_ "GenSigSendType" SG_ 909 WW_RWPMotorSt 1;
BA_ "GenSigStartValue" SG_ 909 WW_RWPMotorSt 0;
BA_ "GenSigTimeoutValue" SG_ 909 WW_RWPMotorSt 0;
BA_ "Remark" SG_ 909 WW_RWPMotorSt "";
BA_ "EventCommandSignal" SG_ 909 LCK_FillerCapASt 0;
BA_ "GatewayedSignals" SG_ 909 LCK_FillerCapASt 0;
BA_ "GenSigInactiveValue" SG_ 909 LCK_FillerCapASt 0;
BA_ "GenSigInvalidValue" SG_ 909 LCK_FillerCapASt 0;
BA_ "GenSigSendType" SG_ 909 LCK_FillerCapASt 0;
BA_ "GenSigStartValue" SG_ 909 LCK_FillerCapASt 0;
BA_ "GenSigTimeoutValue" SG_ 909 LCK_FillerCapASt 0;
BA_ "Remark" SG_ 909 LCK_FillerCapASt "";
BA_ "EventCommandSignal" SG_ 909 LCK_FillerCapBSt 0;
BA_ "GatewayedSignals" SG_ 909 LCK_FillerCapBSt 0;
BA_ "GenSigInactiveValue" SG_ 909 LCK_FillerCapBSt 0;
BA_ "GenSigInvalidValue" SG_ 909 LCK_FillerCapBSt 0;
BA_ "GenSigSendType" SG_ 909 LCK_FillerCapBSt 0;
BA_ "GenSigStartValue" SG_ 909 LCK_FillerCapBSt 0;
BA_ "GenSigTimeoutValue" SG_ 909 LCK_FillerCapBSt 0;
BA_ "Remark" SG_ 909 LCK_FillerCapBSt "";
BA_ "EventCommandSignal" SG_ 909 MR_LeftMirrorFoldUnfoldSt 0;
BA_ "GatewayedSignals" SG_ 909 MR_LeftMirrorFoldUnfoldSt 0;
BA_ "GenSigInactiveValue" SG_ 909 MR_LeftMirrorFoldUnfoldSt 0;
BA_ "GenSigInvalidValue" SG_ 909 MR_LeftMirrorFoldUnfoldSt 0;
BA_ "GenSigSendType" SG_ 909 MR_LeftMirrorFoldUnfoldSt 1;
BA_ "GenSigStartValue" SG_ 909 MR_LeftMirrorFoldUnfoldSt 0;
BA_ "GenSigTimeoutValue" SG_ 909 MR_LeftMirrorFoldUnfoldSt 0;
BA_ "Remark" SG_ 909 MR_LeftMirrorFoldUnfoldSt "";
BA_ "EventCommandSignal" SG_ 909 SBM_SwapHvBattModeSt 0;
BA_ "GatewayedSignals" SG_ 909 SBM_SwapHvBattModeSt 0;
BA_ "GenSigInactiveValue" SG_ 909 SBM_SwapHvBattModeSt 0;
BA_ "GenSigInvalidValue" SG_ 909 SBM_SwapHvBattModeSt 0;
BA_ "GenSigSendType" SG_ 909 SBM_SwapHvBattModeSt 1;
BA_ "GenSigStartValue" SG_ 909 SBM_SwapHvBattModeSt 0;
BA_ "GenSigTimeoutValue" SG_ 909 SBM_SwapHvBattModeSt 0;
BA_ "Remark" SG_ 909 SBM_SwapHvBattModeSt "";
BA_ "EventCommandSignal" SG_ 909 SBM_SwapStaDiagCode 0;
BA_ "GatewayedSignals" SG_ 909 SBM_SwapStaDiagCode 0;
BA_ "GenSigInactiveValue" SG_ 909 SBM_SwapStaDiagCode 0;
BA_ "GenSigInvalidValue" SG_ 909 SBM_SwapStaDiagCode 0;
BA_ "GenSigSendType" SG_ 909 SBM_SwapStaDiagCode 1;
BA_ "GenSigStartValue" SG_ 909 SBM_SwapStaDiagCode 0;
BA_ "GenSigTimeoutValue" SG_ 909 SBM_SwapStaDiagCode 0;
BA_ "Remark" SG_ 909 SBM_SwapStaDiagCode "";
BA_ "EventCommandSignal" SG_ 909 SBM_SwapVehDiagCode 0;
BA_ "GatewayedSignals" SG_ 909 SBM_SwapVehDiagCode 0;
BA_ "GenSigInactiveValue" SG_ 909 SBM_SwapVehDiagCode 0;
BA_ "GenSigInvalidValue" SG_ 909 SBM_SwapVehDiagCode 0;
BA_ "GenSigSendType" SG_ 909 SBM_SwapVehDiagCode 1;
BA_ "GenSigStartValue" SG_ 909 SBM_SwapVehDiagCode 0;
BA_ "GenSigTimeoutValue" SG_ 909 SBM_SwapVehDiagCode 0;
BA_ "Remark" SG_ 909 SBM_SwapVehDiagCode "";
BA_ "EventCommandSignal" SG_ 909 SBM_SwapHvBattModeFaultSt 0;
BA_ "GatewayedSignals" SG_ 909 SBM_SwapHvBattModeFaultSt 0;
BA_ "GenSigInactiveValue" SG_ 909 SBM_SwapHvBattModeFaultSt 0;
BA_ "GenSigInvalidValue" SG_ 909 SBM_SwapHvBattModeFaultSt 0;
BA_ "GenSigSendType" SG_ 909 SBM_SwapHvBattModeFaultSt 1;
BA_ "GenSigStartValue" SG_ 909 SBM_SwapHvBattModeFaultSt 0;
BA_ "GenSigTimeoutValue" SG_ 909 SBM_SwapHvBattModeFaultSt 0;
BA_ "Remark" SG_ 909 SBM_SwapHvBattModeFaultSt "";
BA_ "EventCommandSignal" SG_ 909 IPDS_HDMapPowerSt 0;
BA_ "GatewayedSignals" SG_ 909 IPDS_HDMapPowerSt 0;
BA_ "GenSigInactiveValue" SG_ 909 IPDS_HDMapPowerSt 0;
BA_ "GenSigInvalidValue" SG_ 909 IPDS_HDMapPowerSt 0;
BA_ "GenSigSendType" SG_ 909 IPDS_HDMapPowerSt 1;
BA_ "GenSigStartValue" SG_ 909 IPDS_HDMapPowerSt 0;
BA_ "GenSigTimeoutValue" SG_ 909 IPDS_HDMapPowerSt 0;
BA_ "Remark" SG_ 909 IPDS_HDMapPowerSt "";
BA_ "EventCommandSignal" SG_ 909 IPDS_KL15L1PowerSt 0;
BA_ "GatewayedSignals" SG_ 909 IPDS_KL15L1PowerSt 0;
BA_ "GenSigInactiveValue" SG_ 909 IPDS_KL15L1PowerSt 0;
BA_ "GenSigInvalidValue" SG_ 909 IPDS_KL15L1PowerSt 0;
BA_ "GenSigSendType" SG_ 909 IPDS_KL15L1PowerSt 1;
BA_ "GenSigStartValue" SG_ 909 IPDS_KL15L1PowerSt 0;
BA_ "GenSigTimeoutValue" SG_ 909 IPDS_KL15L1PowerSt 0;
BA_ "Remark" SG_ 909 IPDS_KL15L1PowerSt "";
BA_ "EventCommandSignal" SG_ 909 IPDS_SRSECUPowerSt 0;
BA_ "GatewayedSignals" SG_ 909 IPDS_SRSECUPowerSt 0;
BA_ "GenSigInactiveValue" SG_ 909 IPDS_SRSECUPowerSt 0;
BA_ "GenSigInvalidValue" SG_ 909 IPDS_SRSECUPowerSt 0;
BA_ "GenSigSendType" SG_ 909 IPDS_SRSECUPowerSt 1;
BA_ "GenSigStartValue" SG_ 909 IPDS_SRSECUPowerSt 0;
BA_ "GenSigTimeoutValue" SG_ 909 IPDS_SRSECUPowerSt 0;
BA_ "Remark" SG_ 909 IPDS_SRSECUPowerSt "";
BA_ "EventCommandSignal" SG_ 909 IPDS_HODPowerSt 0;
BA_ "GatewayedSignals" SG_ 909 IPDS_HODPowerSt 0;
BA_ "GenSigInactiveValue" SG_ 909 IPDS_HODPowerSt 0;
BA_ "GenSigInvalidValue" SG_ 909 IPDS_HODPowerSt 0;
BA_ "GenSigSendType" SG_ 909 IPDS_HODPowerSt 1;
BA_ "GenSigStartValue" SG_ 909 IPDS_HODPowerSt 0;
BA_ "GenSigTimeoutValue" SG_ 909 IPDS_HODPowerSt 0;
BA_ "Remark" SG_ 909 IPDS_HODPowerSt "";
BA_ "EventCommandSignal" SG_ 909 KAE_BLEOption 0;
BA_ "GatewayedSignals" SG_ 909 KAE_BLEOption 0;
BA_ "GenSigInactiveValue" SG_ 909 KAE_BLEOption 0;
BA_ "GenSigInvalidValue" SG_ 909 KAE_BLEOption 0;
BA_ "GenSigSendType" SG_ 909 KAE_BLEOption 1;
BA_ "GenSigStartValue" SG_ 909 KAE_BLEOption 0;
BA_ "GenSigTimeoutValue" SG_ 909 KAE_BLEOption 0;
BA_ "Remark" SG_ 909 KAE_BLEOption "";
BA_ "EventCommandSignal" SG_ 909 KAE_UWBOption 0;
BA_ "GatewayedSignals" SG_ 909 KAE_UWBOption 0;
BA_ "GenSigInactiveValue" SG_ 909 KAE_UWBOption 0;
BA_ "GenSigInvalidValue" SG_ 909 KAE_UWBOption 0;
BA_ "GenSigSendType" SG_ 909 KAE_UWBOption 1;
BA_ "GenSigStartValue" SG_ 909 KAE_UWBOption 0;
BA_ "GenSigTimeoutValue" SG_ 909 KAE_UWBOption 0;
BA_ "Remark" SG_ 909 KAE_UWBOption "";
BA_ "EventCommandSignal" SG_ 909 PWL_WinCurrentPos_FLWinPst 0;
BA_ "GatewayedSignals" SG_ 909 PWL_WinCurrentPos_FLWinPst 0;
BA_ "GenSigInactiveValue" SG_ 909 PWL_WinCurrentPos_FLWinPst 0;
BA_ "GenSigInvalidValue" SG_ 909 PWL_WinCurrentPos_FLWinPst 0;
BA_ "GenSigSendType" SG_ 909 PWL_WinCurrentPos_FLWinPst 1;
BA_ "GenSigStartValue" SG_ 909 PWL_WinCurrentPos_FLWinPst 255;
BA_ "GenSigTimeoutValue" SG_ 909 PWL_WinCurrentPos_FLWinPst 0;
BA_ "Remark" SG_ 909 PWL_WinCurrentPos_FLWinPst "";
BA_ "EventCommandSignal" SG_ 909 UINM_FrontLeftPowerReleaseReq 0;
BA_ "GatewayedSignals" SG_ 909 UINM_FrontLeftPowerReleaseReq 0;
BA_ "GenSigInactiveValue" SG_ 909 UINM_FrontLeftPowerReleaseReq 0;
BA_ "GenSigInvalidValue" SG_ 909 UINM_FrontLeftPowerReleaseReq 0;
BA_ "GenSigSendType" SG_ 909 UINM_FrontLeftPowerReleaseReq 1;
BA_ "GenSigStartValue" SG_ 909 UINM_FrontLeftPowerReleaseReq 0;
BA_ "GenSigTimeoutValue" SG_ 909 UINM_FrontLeftPowerReleaseReq 0;
BA_ "Remark" SG_ 909 UINM_FrontLeftPowerReleaseReq "";
BA_ "EventCommandSignal" SG_ 909 UINM_FrontLeftPowerReleaseFaultSt 0;
BA_ "GatewayedSignals" SG_ 909 UINM_FrontLeftPowerReleaseFaultSt 0;
BA_ "GenSigInactiveValue" SG_ 909 UINM_FrontLeftPowerReleaseFaultSt 0;
BA_ "GenSigInvalidValue" SG_ 909 UINM_FrontLeftPowerReleaseFaultSt 0;
BA_ "GenSigSendType" SG_ 909 UINM_FrontLeftPowerReleaseFaultSt 1;
BA_ "GenSigStartValue" SG_ 909 UINM_FrontLeftPowerReleaseFaultSt 0;
BA_ "GenSigTimeoutValue" SG_ 909 UINM_FrontLeftPowerReleaseFaultSt 0;
BA_ "Remark" SG_ 909 UINM_FrontLeftPowerReleaseFaultSt "";
BA_ "EventCommandSignal" SG_ 909 UINM_FrontRightPowerReleaseReq 0;
BA_ "GatewayedSignals" SG_ 909 UINM_FrontRightPowerReleaseReq 0;
BA_ "GenSigInactiveValue" SG_ 909 UINM_FrontRightPowerReleaseReq 0;
BA_ "GenSigInvalidValue" SG_ 909 UINM_FrontRightPowerReleaseReq 0;
BA_ "GenSigSendType" SG_ 909 UINM_FrontRightPowerReleaseReq 1;
BA_ "GenSigStartValue" SG_ 909 UINM_FrontRightPowerReleaseReq 0;
BA_ "GenSigTimeoutValue" SG_ 909 UINM_FrontRightPowerReleaseReq 0;
BA_ "Remark" SG_ 909 UINM_FrontRightPowerReleaseReq "";
BA_ "EventCommandSignal" SG_ 909 UINM_FrontRightPowerReleaseFaultSt 0;
BA_ "GatewayedSignals" SG_ 909 UINM_FrontRightPowerReleaseFaultSt 0;
BA_ "GenSigInactiveValue" SG_ 909 UINM_FrontRightPowerReleaseFaultSt 0;
BA_ "GenSigInvalidValue" SG_ 909 UINM_FrontRightPowerReleaseFaultSt 0;
BA_ "GenSigSendType" SG_ 909 UINM_FrontRightPowerReleaseFaultSt 1;
BA_ "GenSigStartValue" SG_ 909 UINM_FrontRightPowerReleaseFaultSt 0;
BA_ "GenSigTimeoutValue" SG_ 909 UINM_FrontRightPowerReleaseFaultSt 0;
BA_ "Remark" SG_ 909 UINM_FrontRightPowerReleaseFaultSt "";
BA_ "EventCommandSignal" SG_ 909 UINM_RearLeftPowerReleaseFaultSt 0;
BA_ "GatewayedSignals" SG_ 909 UINM_RearLeftPowerReleaseFaultSt 0;
BA_ "GenSigInactiveValue" SG_ 909 UINM_RearLeftPowerReleaseFaultSt 0;
BA_ "GenSigInvalidValue" SG_ 909 UINM_RearLeftPowerReleaseFaultSt 0;
BA_ "GenSigSendType" SG_ 909 UINM_RearLeftPowerReleaseFaultSt 1;
BA_ "GenSigStartValue" SG_ 909 UINM_RearLeftPowerReleaseFaultSt 0;
BA_ "GenSigTimeoutValue" SG_ 909 UINM_RearLeftPowerReleaseFaultSt 0;
BA_ "Remark" SG_ 909 UINM_RearLeftPowerReleaseFaultSt "";
BA_ "EventCommandSignal" SG_ 909 UINM_RearLeftPowerReleaseReq 0;
BA_ "GatewayedSignals" SG_ 909 UINM_RearLeftPowerReleaseReq 0;
BA_ "GenSigInactiveValue" SG_ 909 UINM_RearLeftPowerReleaseReq 0;
BA_ "GenSigInvalidValue" SG_ 909 UINM_RearLeftPowerReleaseReq 0;
BA_ "GenSigSendType" SG_ 909 UINM_RearLeftPowerReleaseReq 1;
BA_ "GenSigStartValue" SG_ 909 UINM_RearLeftPowerReleaseReq 0;
BA_ "GenSigTimeoutValue" SG_ 909 UINM_RearLeftPowerReleaseReq 0;
BA_ "Remark" SG_ 909 UINM_RearLeftPowerReleaseReq "";
BA_ "EventCommandSignal" SG_ 909 UINM_RearRightPowerReleaseFaultSt 0;
BA_ "GatewayedSignals" SG_ 909 UINM_RearRightPowerReleaseFaultSt 0;
BA_ "GenSigInactiveValue" SG_ 909 UINM_RearRightPowerReleaseFaultSt 0;
BA_ "GenSigInvalidValue" SG_ 909 UINM_RearRightPowerReleaseFaultSt 0;
BA_ "GenSigSendType" SG_ 909 UINM_RearRightPowerReleaseFaultSt 1;
BA_ "GenSigStartValue" SG_ 909 UINM_RearRightPowerReleaseFaultSt 0;
BA_ "GenSigTimeoutValue" SG_ 909 UINM_RearRightPowerReleaseFaultSt 0;
BA_ "Remark" SG_ 909 UINM_RearRightPowerReleaseFaultSt "";
BA_ "EventCommandSignal" SG_ 909 UINM_RearRightPowerReleaseReq 0;
BA_ "GatewayedSignals" SG_ 909 UINM_RearRightPowerReleaseReq 0;
BA_ "GenSigInactiveValue" SG_ 909 UINM_RearRightPowerReleaseReq 0;
BA_ "GenSigInvalidValue" SG_ 909 UINM_RearRightPowerReleaseReq 0;
BA_ "GenSigSendType" SG_ 909 UINM_RearRightPowerReleaseReq 1;
BA_ "GenSigStartValue" SG_ 909 UINM_RearRightPowerReleaseReq 0;
BA_ "GenSigTimeoutValue" SG_ 909 UINM_RearRightPowerReleaseReq 0;
BA_ "Remark" SG_ 909 UINM_RearRightPowerReleaseReq "";
BA_ "EventCommandSignal" SG_ 909 BMS_BattSOCAccurate 0;
BA_ "GatewayedSignals" SG_ 909 BMS_BattSOCAccurate 0;
BA_ "GenSigInactiveValue" SG_ 909 BMS_BattSOCAccurate 0;
BA_ "GenSigInvalidValue" SG_ 909 BMS_BattSOCAccurate 0;
BA_ "GenSigSendType" SG_ 909 BMS_BattSOCAccurate 1;
BA_ "GenSigStartValue" SG_ 909 BMS_BattSOCAccurate 5550;
BA_ "GenSigTimeoutValue" SG_ 909 BMS_BattSOCAccurate 0;
BA_ "Remark" SG_ 909 BMS_BattSOCAccurate "";
BA_ "EventCommandSignal" SG_ 909 PWL_WinCurrentPos_RRWinPst 0;
BA_ "GatewayedSignals" SG_ 909 PWL_WinCurrentPos_RRWinPst 0;
BA_ "GenSigInactiveValue" SG_ 909 PWL_WinCurrentPos_RRWinPst 0;
BA_ "GenSigInvalidValue" SG_ 909 PWL_WinCurrentPos_RRWinPst 0;
BA_ "GenSigSendType" SG_ 909 PWL_WinCurrentPos_RRWinPst 1;
BA_ "GenSigStartValue" SG_ 909 PWL_WinCurrentPos_RRWinPst 255;
BA_ "GenSigTimeoutValue" SG_ 909 PWL_WinCurrentPos_RRWinPst 0;
BA_ "Remark" SG_ 909 PWL_WinCurrentPos_RRWinPst "";
BA_ "EventCommandSignal" SG_ 909 PWL_WinCurrentPos_RLWinPst 0;
BA_ "GatewayedSignals" SG_ 909 PWL_WinCurrentPos_RLWinPst 0;
BA_ "GenSigInactiveValue" SG_ 909 PWL_WinCurrentPos_RLWinPst 0;
BA_ "GenSigInvalidValue" SG_ 909 PWL_WinCurrentPos_RLWinPst 0;
BA_ "GenSigSendType" SG_ 909 PWL_WinCurrentPos_RLWinPst 1;
BA_ "GenSigStartValue" SG_ 909 PWL_WinCurrentPos_RLWinPst 255;
BA_ "GenSigTimeoutValue" SG_ 909 PWL_WinCurrentPos_RLWinPst 0;
BA_ "Remark" SG_ 909 PWL_WinCurrentPos_RLWinPst "";
BA_ "EventCommandSignal" SG_ 909 ACEleclocksSt 0;
BA_ "GatewayedSignals" SG_ 909 ACEleclocksSt 0;
BA_ "GenSigInactiveValue" SG_ 909 ACEleclocksSt 0;
BA_ "GenSigInvalidValue" SG_ 909 ACEleclocksSt 0;
BA_ "GenSigSendType" SG_ 909 ACEleclocksSt 1;
BA_ "GenSigStartValue" SG_ 909 ACEleclocksSt 0;
BA_ "GenSigTimeoutValue" SG_ 909 ACEleclocksSt 0;
BA_ "Remark" SG_ 909 ACEleclocksSt "";
BA_ "EventCommandSignal" SG_ 909 DSASBM_MotResp 0;
BA_ "GatewayedSignals" SG_ 909 DSASBM_MotResp 0;
BA_ "GenSigInactiveValue" SG_ 909 DSASBM_MotResp 0;
BA_ "GenSigInvalidValue" SG_ 909 DSASBM_MotResp 0;
BA_ "GenSigSendType" SG_ 909 DSASBM_MotResp 1;
BA_ "GenSigStartValue" SG_ 909 DSASBM_MotResp 0;
BA_ "GenSigTimeoutValue" SG_ 909 DSASBM_MotResp 0;
BA_ "Remark" SG_ 909 DSASBM_MotResp "";
BA_ "EventCommandSignal" SG_ 792 UMM_SecondRHSeatSt 0;
BA_ "GatewayedSignals" SG_ 792 UMM_SecondRHSeatSt 0;
BA_ "GenSigInactiveValue" SG_ 792 UMM_SecondRHSeatSt 0;
BA_ "GenSigInvalidValue" SG_ 792 UMM_SecondRHSeatSt 0;
BA_ "GenSigSendType" SG_ 792 UMM_SecondRHSeatSt 1;
BA_ "GenSigStartValue" SG_ 792 UMM_SecondRHSeatSt 0;
BA_ "GenSigTimeoutValue" SG_ 792 UMM_SecondRHSeatSt 0;
BA_ "Remark" SG_ 792 UMM_SecondRHSeatSt "";
BA_ "EventCommandSignal" SG_ 792 UMM_SecondLHSeatSt 0;
BA_ "GatewayedSignals" SG_ 792 UMM_SecondLHSeatSt 0;
BA_ "GenSigInactiveValue" SG_ 792 UMM_SecondLHSeatSt 0;
BA_ "GenSigInvalidValue" SG_ 792 UMM_SecondLHSeatSt 0;
BA_ "GenSigSendType" SG_ 792 UMM_SecondLHSeatSt 1;
BA_ "GenSigStartValue" SG_ 792 UMM_SecondLHSeatSt 0;
BA_ "GenSigTimeoutValue" SG_ 792 UMM_SecondLHSeatSt 0;
BA_ "Remark" SG_ 792 UMM_SecondLHSeatSt "";
BA_ "EventCommandSignal" SG_ 792 LCK_PowerFillerCapAngle 0;
BA_ "GatewayedSignals" SG_ 792 LCK_PowerFillerCapAngle 0;
BA_ "GenSigInactiveValue" SG_ 792 LCK_PowerFillerCapAngle 0;
BA_ "GenSigInvalidValue" SG_ 792 LCK_PowerFillerCapAngle 0;
BA_ "GenSigSendType" SG_ 792 LCK_PowerFillerCapAngle 1;
BA_ "GenSigStartValue" SG_ 792 LCK_PowerFillerCapAngle 0;
BA_ "GenSigTimeoutValue" SG_ 792 LCK_PowerFillerCapAngle 0;
BA_ "Remark" SG_ 792 LCK_PowerFillerCapAngle "";
BA_ "EventCommandSignal" SG_ 792 EL_ReverseLightSt 0;
BA_ "GatewayedSignals" SG_ 792 EL_ReverseLightSt 0;
BA_ "GenSigInactiveValue" SG_ 792 EL_ReverseLightSt 0;
BA_ "GenSigInvalidValue" SG_ 792 EL_ReverseLightSt 0;
BA_ "GenSigSendType" SG_ 792 EL_ReverseLightSt 1;
BA_ "GenSigStartValue" SG_ 792 EL_ReverseLightSt 0;
BA_ "GenSigTimeoutValue" SG_ 792 EL_ReverseLightSt 0;
BA_ "Remark" SG_ 792 EL_ReverseLightSt "";
BA_ "EventCommandSignal" SG_ 792 EL_ReverseLightFaultSt 0;
BA_ "GatewayedSignals" SG_ 792 EL_ReverseLightFaultSt 0;
BA_ "GenSigInactiveValue" SG_ 792 EL_ReverseLightFaultSt 0;
BA_ "GenSigInvalidValue" SG_ 792 EL_ReverseLightFaultSt 0;
BA_ "GenSigSendType" SG_ 792 EL_ReverseLightFaultSt 1;
BA_ "GenSigStartValue" SG_ 792 EL_ReverseLightFaultSt 0;
BA_ "GenSigTimeoutValue" SG_ 792 EL_ReverseLightFaultSt 0;
BA_ "Remark" SG_ 792 EL_ReverseLightFaultSt "";
BA_ "EventCommandSignal" SG_ 792 EL_RLPositionLightSt 0;
BA_ "GatewayedSignals" SG_ 792 EL_RLPositionLightSt 0;
BA_ "GenSigInactiveValue" SG_ 792 EL_RLPositionLightSt 0;
BA_ "GenSigInvalidValue" SG_ 792 EL_RLPositionLightSt 0;
BA_ "GenSigSendType" SG_ 792 EL_RLPositionLightSt 1;
BA_ "GenSigStartValue" SG_ 792 EL_RLPositionLightSt 0;
BA_ "GenSigTimeoutValue" SG_ 792 EL_RLPositionLightSt 0;
BA_ "Remark" SG_ 792 EL_RLPositionLightSt "";
BA_ "EventCommandSignal" SG_ 792 EL_RLPositionLightFaultSt 0;
BA_ "GatewayedSignals" SG_ 792 EL_RLPositionLightFaultSt 0;
BA_ "GenSigInactiveValue" SG_ 792 EL_RLPositionLightFaultSt 0;
BA_ "GenSigInvalidValue" SG_ 792 EL_RLPositionLightFaultSt 0;
BA_ "GenSigSendType" SG_ 792 EL_RLPositionLightFaultSt 1;
BA_ "GenSigStartValue" SG_ 792 EL_RLPositionLightFaultSt 0;
BA_ "GenSigTimeoutValue" SG_ 792 EL_RLPositionLightFaultSt 0;
BA_ "Remark" SG_ 792 EL_RLPositionLightFaultSt "";
BA_ "EventCommandSignal" SG_ 792 EL_RRPositionLightSt 0;
BA_ "GatewayedSignals" SG_ 792 EL_RRPositionLightSt 0;
BA_ "GenSigInactiveValue" SG_ 792 EL_RRPositionLightSt 0;
BA_ "GenSigInvalidValue" SG_ 792 EL_RRPositionLightSt 0;
BA_ "GenSigSendType" SG_ 792 EL_RRPositionLightSt 1;
BA_ "GenSigStartValue" SG_ 792 EL_RRPositionLightSt 0;
BA_ "GenSigTimeoutValue" SG_ 792 EL_RRPositionLightSt 0;
BA_ "Remark" SG_ 792 EL_RRPositionLightSt "";
BA_ "EventCommandSignal" SG_ 792 EL_RRPositionLightFaultSt 0;
BA_ "GatewayedSignals" SG_ 792 EL_RRPositionLightFaultSt 0;
BA_ "GenSigInactiveValue" SG_ 792 EL_RRPositionLightFaultSt 0;
BA_ "GenSigInvalidValue" SG_ 792 EL_RRPositionLightFaultSt 0;
BA_ "GenSigSendType" SG_ 792 EL_RRPositionLightFaultSt 1;
BA_ "GenSigStartValue" SG_ 792 EL_RRPositionLightFaultSt 0;
BA_ "GenSigTimeoutValue" SG_ 792 EL_RRPositionLightFaultSt 0;
BA_ "Remark" SG_ 792 EL_RRPositionLightFaultSt "";
BA_ "EventCommandSignal" SG_ 792 EL_RearFogLightSt 0;
BA_ "GatewayedSignals" SG_ 792 EL_RearFogLightSt 0;
BA_ "GenSigInactiveValue" SG_ 792 EL_RearFogLightSt 0;
BA_ "GenSigInvalidValue" SG_ 792 EL_RearFogLightSt 0;
BA_ "GenSigSendType" SG_ 792 EL_RearFogLightSt 1;
BA_ "GenSigStartValue" SG_ 792 EL_RearFogLightSt 0;
BA_ "GenSigTimeoutValue" SG_ 792 EL_RearFogLightSt 0;
BA_ "Remark" SG_ 792 EL_RearFogLightSt "";
BA_ "EventCommandSignal" SG_ 792 EL_RearFogLightFaultSt 0;
BA_ "GatewayedSignals" SG_ 792 EL_RearFogLightFaultSt 0;
BA_ "GenSigInactiveValue" SG_ 792 EL_RearFogLightFaultSt 0;
BA_ "GenSigInvalidValue" SG_ 792 EL_RearFogLightFaultSt 0;
BA_ "GenSigSendType" SG_ 792 EL_RearFogLightFaultSt 1;
BA_ "GenSigStartValue" SG_ 792 EL_RearFogLightFaultSt 0;
BA_ "GenSigTimeoutValue" SG_ 792 EL_RearFogLightFaultSt 0;
BA_ "Remark" SG_ 792 EL_RearFogLightFaultSt "";
BA_ "EventCommandSignal" SG_ 860 VCU_7_CRC 0;
BA_ "GatewayedSignals" SG_ 860 VCU_7_CRC 0;
BA_ "GenSigInactiveValue" SG_ 860 VCU_7_CRC 0;
BA_ "GenSigInvalidValue" SG_ 860 VCU_7_CRC 0;
BA_ "GenSigSendType" SG_ 860 VCU_7_CRC 1;
BA_ "GenSigStartValue" SG_ 860 VCU_7_CRC 0;
BA_ "GenSigTimeoutValue" SG_ 860 VCU_7_CRC 0;
BA_ "Remark" SG_ 860 VCU_7_CRC "涉及ID管理表";
BA_ "EventCommandSignal" SG_ 860 VCU_7_Counter 0;
BA_ "GatewayedSignals" SG_ 860 VCU_7_Counter 0;
BA_ "GenSigInactiveValue" SG_ 860 VCU_7_Counter 0;
BA_ "GenSigInvalidValue" SG_ 860 VCU_7_Counter 0;
BA_ "GenSigSendType" SG_ 860 VCU_7_Counter 1;
BA_ "GenSigStartValue" SG_ 860 VCU_7_Counter 0;
BA_ "GenSigTimeoutValue" SG_ 860 VCU_7_Counter 0;
BA_ "Remark" SG_ 860 VCU_7_Counter "涉及ID管理表";
BA_ "EventCommandSignal" SG_ 860 VCU_RoadMod 0;
BA_ "GatewayedSignals" SG_ 860 VCU_RoadMod 0;
BA_ "GenSigInactiveValue" SG_ 860 VCU_RoadMod 0;
BA_ "GenSigInvalidValue" SG_ 860 VCU_RoadMod 0;
BA_ "GenSigSendType" SG_ 860 VCU_RoadMod 1;
BA_ "GenSigStartValue" SG_ 860 VCU_RoadMod 0;
BA_ "GenSigTimeoutValue" SG_ 860 VCU_RoadMod 0;
BA_ "Remark" SG_ 860 VCU_RoadMod "涉及ID管理表";
BA_ "EventCommandSignal" SG_ 860 VCU_GearLvl 0;
BA_ "GatewayedSignals" SG_ 860 VCU_GearLvl 0;
BA_ "GenSigInactiveValue" SG_ 860 VCU_GearLvl 0;
BA_ "GenSigInvalidValue" SG_ 860 VCU_GearLvl 0;
BA_ "GenSigSendType" SG_ 860 VCU_GearLvl 1;
BA_ "GenSigStartValue" SG_ 860 VCU_GearLvl 0;
BA_ "GenSigTimeoutValue" SG_ 860 VCU_GearLvl 0;
BA_ "Remark" SG_ 860 VCU_GearLvl "涉及ID管理表";
BA_ "EventCommandSignal" SG_ 860 VCU_VehDrvMod 0;
BA_ "GatewayedSignals" SG_ 860 VCU_VehDrvMod 0;
BA_ "GenSigInactiveValue" SG_ 860 VCU_VehDrvMod 0;
BA_ "GenSigInvalidValue" SG_ 860 VCU_VehDrvMod 0;
BA_ "GenSigSendType" SG_ 860 VCU_VehDrvMod 1;
BA_ "GenSigStartValue" SG_ 860 VCU_VehDrvMod 0;
BA_ "GenSigTimeoutValue" SG_ 860 VCU_VehDrvMod 0;
BA_ "Remark" SG_ 860 VCU_VehDrvMod "涉及ID管理表";
BA_ "EventCommandSignal" SG_ 860 VCU_VehRdySt 0;
BA_ "GatewayedSignals" SG_ 860 VCU_VehRdySt 0;
BA_ "GenSigInactiveValue" SG_ 860 VCU_VehRdySt 0;
BA_ "GenSigInvalidValue" SG_ 860 VCU_VehRdySt 0;
BA_ "GenSigSendType" SG_ 860 VCU_VehRdySt 1;
BA_ "GenSigStartValue" SG_ 860 VCU_VehRdySt 0;
BA_ "GenSigTimeoutValue" SG_ 860 VCU_VehRdySt 0;
BA_ "Remark" SG_ 860 VCU_VehRdySt "涉及ID管理表";
BA_ "EventCommandSignal" SG_ 860 VCU_PlgConnSt 0;
BA_ "GatewayedSignals" SG_ 860 VCU_PlgConnSt 0;
BA_ "GenSigInactiveValue" SG_ 860 VCU_PlgConnSt 0;
BA_ "GenSigInvalidValue" SG_ 860 VCU_PlgConnSt 0;
BA_ "GenSigSendType" SG_ 860 VCU_PlgConnSt 1;
BA_ "GenSigStartValue" SG_ 860 VCU_PlgConnSt 0;
BA_ "GenSigTimeoutValue" SG_ 860 VCU_PlgConnSt 0;
BA_ "Remark" SG_ 860 VCU_PlgConnSt "涉及ID管理表";
BA_ "EventCommandSignal" SG_ 860 VCU_GearLvlDisp 0;
BA_ "GatewayedSignals" SG_ 860 VCU_GearLvlDisp 0;
BA_ "GenSigInactiveValue" SG_ 860 VCU_GearLvlDisp 0;
BA_ "GenSigInvalidValue" SG_ 860 VCU_GearLvlDisp 0;
BA_ "GenSigSendType" SG_ 860 VCU_GearLvlDisp 1;
BA_ "GenSigStartValue" SG_ 860 VCU_GearLvlDisp 0;
BA_ "GenSigTimeoutValue" SG_ 860 VCU_GearLvlDisp 0;
BA_ "Remark" SG_ 860 VCU_GearLvlDisp "涉及ID管理表";
BA_ "EventCommandSignal" SG_ 860 VCU_SuspModeReq 0;
BA_ "GatewayedSignals" SG_ 860 VCU_SuspModeReq 0;
BA_ "GenSigInactiveValue" SG_ 860 VCU_SuspModeReq 0;
BA_ "GenSigInvalidValue" SG_ 860 VCU_SuspModeReq 0;
BA_ "GenSigSendType" SG_ 860 VCU_SuspModeReq 1;
BA_ "GenSigStartValue" SG_ 860 VCU_SuspModeReq 0;
BA_ "GenSigTimeoutValue" SG_ 860 VCU_SuspModeReq 0;
BA_ "Remark" SG_ 860 VCU_SuspModeReq "涉及ID管理表";
BA_ "EventCommandSignal" SG_ 860 VCU_SuspModeReqEnable 0;
BA_ "GatewayedSignals" SG_ 860 VCU_SuspModeReqEnable 0;
BA_ "GenSigInactiveValue" SG_ 860 VCU_SuspModeReqEnable 0;
BA_ "GenSigInvalidValue" SG_ 860 VCU_SuspModeReqEnable 0;
BA_ "GenSigSendType" SG_ 860 VCU_SuspModeReqEnable 1;
BA_ "GenSigStartValue" SG_ 860 VCU_SuspModeReqEnable 0;
BA_ "GenSigTimeoutValue" SG_ 860 VCU_SuspModeReqEnable 0;
BA_ "Remark" SG_ 860 VCU_SuspModeReqEnable "涉及ID管理表";
BA_ "EventCommandSignal" SG_ 860 VCU_GearPosition 0;
BA_ "GatewayedSignals" SG_ 860 VCU_GearPosition 0;
BA_ "GenSigInactiveValue" SG_ 860 VCU_GearPosition 0;
BA_ "GenSigInvalidValue" SG_ 860 VCU_GearPosition 0;
BA_ "GenSigSendType" SG_ 860 VCU_GearPosition 1;
BA_ "GenSigStartValue" SG_ 860 VCU_GearPosition 0;
BA_ "GenSigTimeoutValue" SG_ 860 VCU_GearPosition 0;
BA_ "Remark" SG_ 860 VCU_GearPosition "涉及ID管理表";
BA_ "EventCommandSignal" SG_ 860 VCU_EcoPlusMod 0;
BA_ "GatewayedSignals" SG_ 860 VCU_EcoPlusMod 0;
BA_ "GenSigInactiveValue" SG_ 860 VCU_EcoPlusMod 0;
BA_ "GenSigInvalidValue" SG_ 860 VCU_EcoPlusMod 0;
BA_ "GenSigSendType" SG_ 860 VCU_EcoPlusMod 1;
BA_ "GenSigStartValue" SG_ 860 VCU_EcoPlusMod 0;
BA_ "GenSigTimeoutValue" SG_ 860 VCU_EcoPlusMod 0;
BA_ "Remark" SG_ 860 VCU_EcoPlusMod "涉及ID管理表";
BA_ "EventCommandSignal" SG_ 860 ICC_RoadMod 0;
BA_ "GatewayedSignals" SG_ 860 ICC_RoadMod 0;
BA_ "GenSigInactiveValue" SG_ 860 ICC_RoadMod 0;
BA_ "GenSigInvalidValue" SG_ 860 ICC_RoadMod 0;
BA_ "GenSigSendType" SG_ 860 ICC_RoadMod 1;
BA_ "GenSigStartValue" SG_ 860 ICC_RoadMod 0;
BA_ "GenSigTimeoutValue" SG_ 860 ICC_RoadMod 0;
BA_ "Remark" SG_ 860 ICC_RoadMod "涉及ID管理表";
BA_ "EventCommandSignal" SG_ 860 VCU_TrailerModeSt 0;
BA_ "GatewayedSignals" SG_ 860 VCU_TrailerModeSt 0;
BA_ "GenSigInactiveValue" SG_ 860 VCU_TrailerModeSt 0;
BA_ "GenSigInvalidValue" SG_ 860 VCU_TrailerModeSt 0;
BA_ "GenSigSendType" SG_ 860 VCU_TrailerModeSt 1;
BA_ "GenSigStartValue" SG_ 860 VCU_TrailerModeSt 0;
BA_ "GenSigTimeoutValue" SG_ 860 VCU_TrailerModeSt 0;
BA_ "Remark" SG_ 860 VCU_TrailerModeSt "涉及ID管理表";
BA_ "EventCommandSignal" SG_ 860 VCU_BMS_BattSocDisp 0;
BA_ "GatewayedSignals" SG_ 860 VCU_BMS_BattSocDisp 0;
BA_ "GenSigInactiveValue" SG_ 860 VCU_BMS_BattSocDisp 0;
BA_ "GenSigInvalidValue" SG_ 860 VCU_BMS_BattSocDisp 16383;
BA_ "GenSigSendType" SG_ 860 VCU_BMS_BattSocDisp 1;
BA_ "GenSigStartValue" SG_ 860 VCU_BMS_BattSocDisp 16382;
BA_ "GenSigTimeoutValue" SG_ 860 VCU_BMS_BattSocDisp 16382;
BA_ "Remark" SG_ 860 VCU_BMS_BattSocDisp "涉及ID管理表";
BA_ "EventCommandSignal" SG_ 860 VCU_VehElcConspAccumAvg 0;
BA_ "GatewayedSignals" SG_ 860 VCU_VehElcConspAccumAvg 0;
BA_ "GenSigInactiveValue" SG_ 860 VCU_VehElcConspAccumAvg 0;
BA_ "GenSigInvalidValue" SG_ 860 VCU_VehElcConspAccumAvg 0;
BA_ "GenSigSendType" SG_ 860 VCU_VehElcConspAccumAvg 1;
BA_ "GenSigStartValue" SG_ 860 VCU_VehElcConspAccumAvg 1023;
BA_ "GenSigTimeoutValue" SG_ 860 VCU_VehElcConspAccumAvg 1023;
BA_ "Remark" SG_ 860 VCU_VehElcConspAccumAvg "涉及ID管理表";
BA_ "EventCommandSignal" SG_ 860 ICC_360Switch 0;
BA_ "GatewayedSignals" SG_ 860 ICC_360Switch 0;
BA_ "GenSigInactiveValue" SG_ 860 ICC_360Switch 0;
BA_ "GenSigInvalidValue" SG_ 860 ICC_360Switch 0;
BA_ "GenSigSendType" SG_ 860 ICC_360Switch 1;
BA_ "GenSigStartValue" SG_ 860 ICC_360Switch 0;
BA_ "GenSigTimeoutValue" SG_ 860 ICC_360Switch 0;
BA_ "Remark" SG_ 860 ICC_360Switch "涉及ID管理表";
BA_ "EventCommandSignal" SG_ 431 VCU_TargetRecpTorqVD 0;
BA_ "GatewayedSignals" SG_ 431 VCU_TargetRecpTorqVD 0;
BA_ "GenSigInactiveValue" SG_ 431 VCU_TargetRecpTorqVD 0;
BA_ "GenSigInvalidValue" SG_ 431 VCU_TargetRecpTorqVD 0;
BA_ "GenSigSendType" SG_ 431 VCU_TargetRecpTorqVD 1;
BA_ "GenSigStartValue" SG_ 431 VCU_TargetRecpTorqVD 0;
BA_ "GenSigTimeoutValue" SG_ 431 VCU_TargetRecpTorqVD 0;
BA_ "Remark" SG_ 431 VCU_TargetRecpTorqVD "涉及ID管理表";
BA_ "EventCommandSignal" SG_ 431 VCU_AccDriverOrvd 0;
BA_ "GatewayedSignals" SG_ 431 VCU_AccDriverOrvd 0;
BA_ "GenSigInactiveValue" SG_ 431 VCU_AccDriverOrvd 0;
BA_ "GenSigInvalidValue" SG_ 431 VCU_AccDriverOrvd 0;
BA_ "GenSigSendType" SG_ 431 VCU_AccDriverOrvd 1;
BA_ "GenSigStartValue" SG_ 431 VCU_AccDriverOrvd 0;
BA_ "GenSigTimeoutValue" SG_ 431 VCU_AccDriverOrvd 0;
BA_ "Remark" SG_ 431 VCU_AccDriverOrvd "涉及ID管理表";
BA_ "EventCommandSignal" SG_ 431 VCU_AccDriverOrvdVD 0;
BA_ "GatewayedSignals" SG_ 431 VCU_AccDriverOrvdVD 0;
BA_ "GenSigInactiveValue" SG_ 431 VCU_AccDriverOrvdVD 0;
BA_ "GenSigInvalidValue" SG_ 431 VCU_AccDriverOrvdVD 0;
BA_ "GenSigSendType" SG_ 431 VCU_AccDriverOrvdVD 1;
BA_ "GenSigStartValue" SG_ 431 VCU_AccDriverOrvdVD 0;
BA_ "GenSigTimeoutValue" SG_ 431 VCU_AccDriverOrvdVD 0;
BA_ "Remark" SG_ 431 VCU_AccDriverOrvdVD "涉及ID管理表";
BA_ "EventCommandSignal" SG_ 431 VCU_TargetRecpTorq 0;
BA_ "GatewayedSignals" SG_ 431 VCU_TargetRecpTorq 0;
BA_ "GenSigInactiveValue" SG_ 431 VCU_TargetRecpTorq 0;
BA_ "GenSigInvalidValue" SG_ 431 VCU_TargetRecpTorq 0;
BA_ "GenSigSendType" SG_ 431 VCU_TargetRecpTorq 1;
BA_ "GenSigStartValue" SG_ 431 VCU_TargetRecpTorq 0;
BA_ "GenSigTimeoutValue" SG_ 431 VCU_TargetRecpTorq 0;
BA_ "Remark" SG_ 431 VCU_TargetRecpTorq "涉及ID管理表";
BA_ "EventCommandSignal" SG_ 431 VCU_TargetRecpTorqFA 0;
BA_ "GatewayedSignals" SG_ 431 VCU_TargetRecpTorqFA 0;
BA_ "GenSigInactiveValue" SG_ 431 VCU_TargetRecpTorqFA 0;
BA_ "GenSigInvalidValue" SG_ 431 VCU_TargetRecpTorqFA 0;
BA_ "GenSigSendType" SG_ 431 VCU_TargetRecpTorqFA 1;
BA_ "GenSigStartValue" SG_ 431 VCU_TargetRecpTorqFA 0;
BA_ "GenSigTimeoutValue" SG_ 431 VCU_TargetRecpTorqFA 0;
BA_ "Remark" SG_ 431 VCU_TargetRecpTorqFA "涉及ID管理表";
BA_ "EventCommandSignal" SG_ 431 VCU_TargetRecpTorqRA 0;
BA_ "GatewayedSignals" SG_ 431 VCU_TargetRecpTorqRA 0;
BA_ "GenSigInactiveValue" SG_ 431 VCU_TargetRecpTorqRA 0;
BA_ "GenSigInvalidValue" SG_ 431 VCU_TargetRecpTorqRA 0;
BA_ "GenSigSendType" SG_ 431 VCU_TargetRecpTorqRA 1;
BA_ "GenSigStartValue" SG_ 431 VCU_TargetRecpTorqRA 0;
BA_ "GenSigTimeoutValue" SG_ 431 VCU_TargetRecpTorqRA 0;
BA_ "Remark" SG_ 431 VCU_TargetRecpTorqRA "涉及ID管理表";
BA_ "EventCommandSignal" SG_ 431 VCU_TorqDriverReqFA 0;
BA_ "GatewayedSignals" SG_ 431 VCU_TorqDriverReqFA 0;
BA_ "GenSigInactiveValue" SG_ 431 VCU_TorqDriverReqFA 0;
BA_ "GenSigInvalidValue" SG_ 431 VCU_TorqDriverReqFA 0;
BA_ "GenSigSendType" SG_ 431 VCU_TorqDriverReqFA 1;
BA_ "GenSigStartValue" SG_ 431 VCU_TorqDriverReqFA 0;
BA_ "GenSigTimeoutValue" SG_ 431 VCU_TorqDriverReqFA 0;
BA_ "Remark" SG_ 431 VCU_TorqDriverReqFA "涉及ID管理表";
BA_ "EventCommandSignal" SG_ 431 VCU_TorqDriverReqRA 0;
BA_ "GatewayedSignals" SG_ 431 VCU_TorqDriverReqRA 0;
BA_ "GenSigInactiveValue" SG_ 431 VCU_TorqDriverReqRA 0;
BA_ "GenSigInvalidValue" SG_ 431 VCU_TorqDriverReqRA 0;
BA_ "GenSigSendType" SG_ 431 VCU_TorqDriverReqRA 1;
BA_ "GenSigStartValue" SG_ 431 VCU_TorqDriverReqRA 0;
BA_ "GenSigTimeoutValue" SG_ 431 VCU_TorqDriverReqRA 0;
BA_ "Remark" SG_ 431 VCU_TorqDriverReqRA "涉及ID管理表";
BA_ "EventCommandSignal" SG_ 431 VCU_VehActDrvTorqFA 0;
BA_ "GatewayedSignals" SG_ 431 VCU_VehActDrvTorqFA 0;
BA_ "GenSigInactiveValue" SG_ 431 VCU_VehActDrvTorqFA 0;
BA_ "GenSigInvalidValue" SG_ 431 VCU_VehActDrvTorqFA 0;
BA_ "GenSigSendType" SG_ 431 VCU_VehActDrvTorqFA 1;
BA_ "GenSigStartValue" SG_ 431 VCU_VehActDrvTorqFA 0;
BA_ "GenSigTimeoutValue" SG_ 431 VCU_VehActDrvTorqFA 0;
BA_ "Remark" SG_ 431 VCU_VehActDrvTorqFA "涉及ID管理表";
BA_ "EventCommandSignal" SG_ 431 VCU_VehActDrvTorqRA 0;
BA_ "GatewayedSignals" SG_ 431 VCU_VehActDrvTorqRA 0;
BA_ "GenSigInactiveValue" SG_ 431 VCU_VehActDrvTorqRA 0;
BA_ "GenSigInvalidValue" SG_ 431 VCU_VehActDrvTorqRA 0;
BA_ "GenSigSendType" SG_ 431 VCU_VehActDrvTorqRA 1;
BA_ "GenSigStartValue" SG_ 431 VCU_VehActDrvTorqRA 0;
BA_ "GenSigTimeoutValue" SG_ 431 VCU_VehActDrvTorqRA 0;
BA_ "Remark" SG_ 431 VCU_VehActDrvTorqRA "涉及ID管理表";
BA_ "EventCommandSignal" SG_ 431 VCU_TargetRecpTorqFAVD 0;
BA_ "GatewayedSignals" SG_ 431 VCU_TargetRecpTorqFAVD 0;
BA_ "GenSigInactiveValue" SG_ 431 VCU_TargetRecpTorqFAVD 0;
BA_ "GenSigInvalidValue" SG_ 431 VCU_TargetRecpTorqFAVD 0;
BA_ "GenSigSendType" SG_ 431 VCU_TargetRecpTorqFAVD 1;
BA_ "GenSigStartValue" SG_ 431 VCU_TargetRecpTorqFAVD 0;
BA_ "GenSigTimeoutValue" SG_ 431 VCU_TargetRecpTorqFAVD 0;
BA_ "Remark" SG_ 431 VCU_TargetRecpTorqFAVD "涉及ID管理表";
BA_ "EventCommandSignal" SG_ 431 VCU_TargetRecpTorqRAVD 0;
BA_ "GatewayedSignals" SG_ 431 VCU_TargetRecpTorqRAVD 0;
BA_ "GenSigInactiveValue" SG_ 431 VCU_TargetRecpTorqRAVD 0;
BA_ "GenSigInvalidValue" SG_ 431 VCU_TargetRecpTorqRAVD 0;
BA_ "GenSigSendType" SG_ 431 VCU_TargetRecpTorqRAVD 1;
BA_ "GenSigStartValue" SG_ 431 VCU_TargetRecpTorqRAVD 0;
BA_ "GenSigTimeoutValue" SG_ 431 VCU_TargetRecpTorqRAVD 0;
BA_ "Remark" SG_ 431 VCU_TargetRecpTorqRAVD "涉及ID管理表";
BA_ "EventCommandSignal" SG_ 431 VCU_TorqDriverReqFAVD 0;
BA_ "GatewayedSignals" SG_ 431 VCU_TorqDriverReqFAVD 0;
BA_ "GenSigInactiveValue" SG_ 431 VCU_TorqDriverReqFAVD 0;
BA_ "GenSigInvalidValue" SG_ 431 VCU_TorqDriverReqFAVD 0;
BA_ "GenSigSendType" SG_ 431 VCU_TorqDriverReqFAVD 1;
BA_ "GenSigStartValue" SG_ 431 VCU_TorqDriverReqFAVD 0;
BA_ "GenSigTimeoutValue" SG_ 431 VCU_TorqDriverReqFAVD 0;
BA_ "Remark" SG_ 431 VCU_TorqDriverReqFAVD "涉及ID管理表";
BA_ "EventCommandSignal" SG_ 431 VCU_TorqDriverReqRAVD 0;
BA_ "GatewayedSignals" SG_ 431 VCU_TorqDriverReqRAVD 0;
BA_ "GenSigInactiveValue" SG_ 431 VCU_TorqDriverReqRAVD 0;
BA_ "GenSigInvalidValue" SG_ 431 VCU_TorqDriverReqRAVD 0;
BA_ "GenSigSendType" SG_ 431 VCU_TorqDriverReqRAVD 1;
BA_ "GenSigStartValue" SG_ 431 VCU_TorqDriverReqRAVD 0;
BA_ "GenSigTimeoutValue" SG_ 431 VCU_TorqDriverReqRAVD 0;
BA_ "Remark" SG_ 431 VCU_TorqDriverReqRAVD "涉及ID管理表";
BA_ "EventCommandSignal" SG_ 431 VCU_VehActDrvTorqFAVD 0;
BA_ "GatewayedSignals" SG_ 431 VCU_VehActDrvTorqFAVD 0;
BA_ "GenSigInactiveValue" SG_ 431 VCU_VehActDrvTorqFAVD 0;
BA_ "GenSigInvalidValue" SG_ 431 VCU_VehActDrvTorqFAVD 0;
BA_ "GenSigSendType" SG_ 431 VCU_VehActDrvTorqFAVD 1;
BA_ "GenSigStartValue" SG_ 431 VCU_VehActDrvTorqFAVD 0;
BA_ "GenSigTimeoutValue" SG_ 431 VCU_VehActDrvTorqFAVD 0;
BA_ "Remark" SG_ 431 VCU_VehActDrvTorqFAVD "涉及ID管理表";
BA_ "EventCommandSignal" SG_ 431 VCU_VehActDrvTorqRAVD 0;
BA_ "GatewayedSignals" SG_ 431 VCU_VehActDrvTorqRAVD 0;
BA_ "GenSigInactiveValue" SG_ 431 VCU_VehActDrvTorqRAVD 0;
BA_ "GenSigInvalidValue" SG_ 431 VCU_VehActDrvTorqRAVD 0;
BA_ "GenSigSendType" SG_ 431 VCU_VehActDrvTorqRAVD 1;
BA_ "GenSigStartValue" SG_ 431 VCU_VehActDrvTorqRAVD 0;
BA_ "GenSigTimeoutValue" SG_ 431 VCU_VehActDrvTorqRAVD 0;
BA_ "Remark" SG_ 431 VCU_VehActDrvTorqRAVD "涉及ID管理表";
BA_ "EventCommandSignal" SG_ 431 VCU_BcsDecelReq 0;
BA_ "GatewayedSignals" SG_ 431 VCU_BcsDecelReq 0;
BA_ "GenSigInactiveValue" SG_ 431 VCU_BcsDecelReq 0;
BA_ "GenSigInvalidValue" SG_ 431 VCU_BcsDecelReq 0;
BA_ "GenSigSendType" SG_ 431 VCU_BcsDecelReq 1;
BA_ "GenSigStartValue" SG_ 431 VCU_BcsDecelReq 15;
BA_ "GenSigTimeoutValue" SG_ 431 VCU_BcsDecelReq 0;
BA_ "Remark" SG_ 431 VCU_BcsDecelReq "涉及ID管理表";
BA_ "EventCommandSignal" SG_ 431 VCU_BcsDecelVD 0;
BA_ "GatewayedSignals" SG_ 431 VCU_BcsDecelVD 0;
BA_ "GenSigInactiveValue" SG_ 431 VCU_BcsDecelVD 0;
BA_ "GenSigInvalidValue" SG_ 431 VCU_BcsDecelVD 0;
BA_ "GenSigSendType" SG_ 431 VCU_BcsDecelVD 1;
BA_ "GenSigStartValue" SG_ 431 VCU_BcsDecelVD 0;
BA_ "GenSigTimeoutValue" SG_ 431 VCU_BcsDecelVD 0;
BA_ "Remark" SG_ 431 VCU_BcsDecelVD "涉及ID管理表";
BA_ "EventCommandSignal" SG_ 431 VCU_RecpTorqRL 0;
BA_ "GatewayedSignals" SG_ 431 VCU_RecpTorqRL 0;
BA_ "GenSigInactiveValue" SG_ 431 VCU_RecpTorqRL 0;
BA_ "GenSigInvalidValue" SG_ 431 VCU_RecpTorqRL 0;
BA_ "GenSigSendType" SG_ 431 VCU_RecpTorqRL 1;
BA_ "GenSigStartValue" SG_ 431 VCU_RecpTorqRL 0;
BA_ "GenSigTimeoutValue" SG_ 431 VCU_RecpTorqRL 0;
BA_ "Remark" SG_ 431 VCU_RecpTorqRL "涉及ID管理表";
BA_ "EventCommandSignal" SG_ 431 VCU_RecpTorqRLVD 0;
BA_ "GatewayedSignals" SG_ 431 VCU_RecpTorqRLVD 0;
BA_ "GenSigInactiveValue" SG_ 431 VCU_RecpTorqRLVD 0;
BA_ "GenSigInvalidValue" SG_ 431 VCU_RecpTorqRLVD 0;
BA_ "GenSigSendType" SG_ 431 VCU_RecpTorqRLVD 1;
BA_ "GenSigStartValue" SG_ 431 VCU_RecpTorqRLVD 0;
BA_ "GenSigTimeoutValue" SG_ 431 VCU_RecpTorqRLVD 0;
BA_ "Remark" SG_ 431 VCU_RecpTorqRLVD "涉及ID管理表";
BA_ "EventCommandSignal" SG_ 431 VCU_RecpTorqRR 0;
BA_ "GatewayedSignals" SG_ 431 VCU_RecpTorqRR 0;
BA_ "GenSigInactiveValue" SG_ 431 VCU_RecpTorqRR 0;
BA_ "GenSigInvalidValue" SG_ 431 VCU_RecpTorqRR 0;
BA_ "GenSigSendType" SG_ 431 VCU_RecpTorqRR 1;
BA_ "GenSigStartValue" SG_ 431 VCU_RecpTorqRR 0;
BA_ "GenSigTimeoutValue" SG_ 431 VCU_RecpTorqRR 0;
BA_ "Remark" SG_ 431 VCU_RecpTorqRR "涉及ID管理表";
BA_ "EventCommandSignal" SG_ 431 VCU_RecpTorqRRVD 0;
BA_ "GatewayedSignals" SG_ 431 VCU_RecpTorqRRVD 0;
BA_ "GenSigInactiveValue" SG_ 431 VCU_RecpTorqRRVD 0;
BA_ "GenSigInvalidValue" SG_ 431 VCU_RecpTorqRRVD 0;
BA_ "GenSigSendType" SG_ 431 VCU_RecpTorqRRVD 1;
BA_ "GenSigStartValue" SG_ 431 VCU_RecpTorqRRVD 0;
BA_ "GenSigTimeoutValue" SG_ 431 VCU_RecpTorqRRVD 0;
BA_ "Remark" SG_ 431 VCU_RecpTorqRRVD "涉及ID管理表";
BA_ "EventCommandSignal" SG_ 431 VCU_ADSNetErrorFb 0;
BA_ "GatewayedSignals" SG_ 431 VCU_ADSNetErrorFb 0;
BA_ "GenSigInactiveValue" SG_ 431 VCU_ADSNetErrorFb 0;
BA_ "GenSigInvalidValue" SG_ 431 VCU_ADSNetErrorFb 0;
BA_ "GenSigSendType" SG_ 431 VCU_ADSNetErrorFb 1;
BA_ "GenSigStartValue" SG_ 431 VCU_ADSNetErrorFb 0;
BA_ "GenSigTimeoutValue" SG_ 431 VCU_ADSNetErrorFb 0;
BA_ "Remark" SG_ 431 VCU_ADSNetErrorFb "涉及ID管理表";
BA_ "EventCommandSignal" SG_ 431 VCU_NetModeResp 0;
BA_ "GatewayedSignals" SG_ 431 VCU_NetModeResp 0;
BA_ "GenSigInactiveValue" SG_ 431 VCU_NetModeResp 0;
BA_ "GenSigInvalidValue" SG_ 431 VCU_NetModeResp 0;
BA_ "GenSigSendType" SG_ 431 VCU_NetModeResp 1;
BA_ "GenSigStartValue" SG_ 431 VCU_NetModeResp 0;
BA_ "GenSigTimeoutValue" SG_ 431 VCU_NetModeResp 0;
BA_ "Remark" SG_ 431 VCU_NetModeResp "涉及ID管理表";
BA_ "EventCommandSignal" SG_ 431 VCU_PwrLimDrv_kW 0;
BA_ "GatewayedSignals" SG_ 431 VCU_PwrLimDrv_kW 0;
BA_ "GenSigInactiveValue" SG_ 431 VCU_PwrLimDrv_kW 0;
BA_ "GenSigInvalidValue" SG_ 431 VCU_PwrLimDrv_kW 0;
BA_ "GenSigSendType" SG_ 431 VCU_PwrLimDrv_kW 1;
BA_ "GenSigStartValue" SG_ 431 VCU_PwrLimDrv_kW 1024;
BA_ "GenSigTimeoutValue" SG_ 431 VCU_PwrLimDrv_kW 0;
BA_ "Remark" SG_ 431 VCU_PwrLimDrv_kW "涉及ID管理表";
BA_ "EventCommandSignal" SG_ 431 VCU_PwrLimRegen_kW 0;
BA_ "GatewayedSignals" SG_ 431 VCU_PwrLimRegen_kW 0;
BA_ "GenSigInactiveValue" SG_ 431 VCU_PwrLimRegen_kW 0;
BA_ "GenSigInvalidValue" SG_ 431 VCU_PwrLimRegen_kW 0;
BA_ "GenSigSendType" SG_ 431 VCU_PwrLimRegen_kW 1;
BA_ "GenSigStartValue" SG_ 431 VCU_PwrLimRegen_kW 1024;
BA_ "GenSigTimeoutValue" SG_ 431 VCU_PwrLimRegen_kW 0;
BA_ "Remark" SG_ 431 VCU_PwrLimRegen_kW "涉及ID管理表";
BA_ "EventCommandSignal" SG_ 431 VCU_PwrLimDrv_kWVD 0;
BA_ "GatewayedSignals" SG_ 431 VCU_PwrLimDrv_kWVD 0;
BA_ "GenSigInactiveValue" SG_ 431 VCU_PwrLimDrv_kWVD 0;
BA_ "GenSigInvalidValue" SG_ 431 VCU_PwrLimDrv_kWVD 0;
BA_ "GenSigSendType" SG_ 431 VCU_PwrLimDrv_kWVD 1;
BA_ "GenSigStartValue" SG_ 431 VCU_PwrLimDrv_kWVD 0;
BA_ "GenSigTimeoutValue" SG_ 431 VCU_PwrLimDrv_kWVD 0;
BA_ "Remark" SG_ 431 VCU_PwrLimDrv_kWVD "涉及ID管理表";
BA_ "EventCommandSignal" SG_ 431 VCU_PwrLimRegen_kWVD 0;
BA_ "GatewayedSignals" SG_ 431 VCU_PwrLimRegen_kWVD 0;
BA_ "GenSigInactiveValue" SG_ 431 VCU_PwrLimRegen_kWVD 0;
BA_ "GenSigInvalidValue" SG_ 431 VCU_PwrLimRegen_kWVD 0;
BA_ "GenSigSendType" SG_ 431 VCU_PwrLimRegen_kWVD 1;
BA_ "GenSigStartValue" SG_ 431 VCU_PwrLimRegen_kWVD 0;
BA_ "GenSigTimeoutValue" SG_ 431 VCU_PwrLimRegen_kWVD 0;
BA_ "Remark" SG_ 431 VCU_PwrLimRegen_kWVD "涉及ID管理表";
BA_ "EventCommandSignal" SG_ 431 VCU_PtTqActvStsFL 0;
BA_ "GatewayedSignals" SG_ 431 VCU_PtTqActvStsFL 0;
BA_ "GenSigInactiveValue" SG_ 431 VCU_PtTqActvStsFL 0;
BA_ "GenSigInvalidValue" SG_ 431 VCU_PtTqActvStsFL 0;
BA_ "GenSigSendType" SG_ 431 VCU_PtTqActvStsFL 1;
BA_ "GenSigStartValue" SG_ 431 VCU_PtTqActvStsFL 0;
BA_ "GenSigTimeoutValue" SG_ 431 VCU_PtTqActvStsFL 0;
BA_ "Remark" SG_ 431 VCU_PtTqActvStsFL "涉及ID管理表";
BA_ "EventCommandSignal" SG_ 431 VCU_PtTqActvStsFR 0;
BA_ "GatewayedSignals" SG_ 431 VCU_PtTqActvStsFR 0;
BA_ "GenSigInactiveValue" SG_ 431 VCU_PtTqActvStsFR 0;
BA_ "GenSigInvalidValue" SG_ 431 VCU_PtTqActvStsFR 0;
BA_ "GenSigSendType" SG_ 431 VCU_PtTqActvStsFR 1;
BA_ "GenSigStartValue" SG_ 431 VCU_PtTqActvStsFR 0;
BA_ "GenSigTimeoutValue" SG_ 431 VCU_PtTqActvStsFR 0;
BA_ "Remark" SG_ 431 VCU_PtTqActvStsFR "涉及ID管理表";
BA_ "EventCommandSignal" SG_ 431 VCU_PtTqActvStsRL 0;
BA_ "GatewayedSignals" SG_ 431 VCU_PtTqActvStsRL 0;
BA_ "GenSigInactiveValue" SG_ 431 VCU_PtTqActvStsRL 0;
BA_ "GenSigInvalidValue" SG_ 431 VCU_PtTqActvStsRL 0;
BA_ "GenSigSendType" SG_ 431 VCU_PtTqActvStsRL 1;
BA_ "GenSigStartValue" SG_ 431 VCU_PtTqActvStsRL 0;
BA_ "GenSigTimeoutValue" SG_ 431 VCU_PtTqActvStsRL 0;
BA_ "Remark" SG_ 431 VCU_PtTqActvStsRL "涉及ID管理表";
BA_ "EventCommandSignal" SG_ 431 VCU_PtTqActvStsRR 0;
BA_ "GatewayedSignals" SG_ 431 VCU_PtTqActvStsRR 0;
BA_ "GenSigInactiveValue" SG_ 431 VCU_PtTqActvStsRR 0;
BA_ "GenSigInvalidValue" SG_ 431 VCU_PtTqActvStsRR 0;
BA_ "GenSigSendType" SG_ 431 VCU_PtTqActvStsRR 1;
BA_ "GenSigStartValue" SG_ 431 VCU_PtTqActvStsRR 0;
BA_ "GenSigTimeoutValue" SG_ 431 VCU_PtTqActvStsRR 0;
BA_ "Remark" SG_ 431 VCU_PtTqActvStsRR "涉及ID管理表";
BA_ "EventCommandSignal" SG_ 430 SRS_1_CRC_1 0;
BA_ "GatewayedSignals" SG_ 430 SRS_1_CRC_1 0;
BA_ "GenSigInactiveValue" SG_ 430 SRS_1_CRC_1 0;
BA_ "GenSigInvalidValue" SG_ 430 SRS_1_CRC_1 0;
BA_ "GenSigSendType" SG_ 430 SRS_1_CRC_1 1;
BA_ "GenSigStartValue" SG_ 430 SRS_1_CRC_1 0;
BA_ "GenSigTimeoutValue" SG_ 430 SRS_1_CRC_1 0;
BA_ "Remark" SG_ 430 SRS_1_CRC_1 "";
BA_ "EventCommandSignal" SG_ 430 SRS_1_Counter_1 0;
BA_ "GatewayedSignals" SG_ 430 SRS_1_Counter_1 0;
BA_ "GenSigInactiveValue" SG_ 430 SRS_1_Counter_1 0;
BA_ "GenSigInvalidValue" SG_ 430 SRS_1_Counter_1 0;
BA_ "GenSigSendType" SG_ 430 SRS_1_Counter_1 1;
BA_ "GenSigStartValue" SG_ 430 SRS_1_Counter_1 0;
BA_ "GenSigTimeoutValue" SG_ 430 SRS_1_Counter_1 0;
BA_ "Remark" SG_ 430 SRS_1_Counter_1 "";
BA_ "EventCommandSignal" SG_ 430 SRS_CrashOutputSt 0;
BA_ "GatewayedSignals" SG_ 430 SRS_CrashOutputSt 0;
BA_ "GenSigInactiveValue" SG_ 430 SRS_CrashOutputSt 0;
BA_ "GenSigInvalidValue" SG_ 430 SRS_CrashOutputSt 0;
BA_ "GenSigSendType" SG_ 430 SRS_CrashOutputSt 1;
BA_ "GenSigStartValue" SG_ 430 SRS_CrashOutputSt 0;
BA_ "GenSigTimeoutValue" SG_ 430 SRS_CrashOutputSt 0;
BA_ "Remark" SG_ 430 SRS_CrashOutputSt "";
BA_ "EventCommandSignal" SG_ 430 SRS_Front_CrashOutputSt 0;
BA_ "GatewayedSignals" SG_ 430 SRS_Front_CrashOutputSt 0;
BA_ "GenSigInactiveValue" SG_ 430 SRS_Front_CrashOutputSt 0;
BA_ "GenSigInvalidValue" SG_ 430 SRS_Front_CrashOutputSt 0;
BA_ "GenSigSendType" SG_ 430 SRS_Front_CrashOutputSt 1;
BA_ "GenSigStartValue" SG_ 430 SRS_Front_CrashOutputSt 0;
BA_ "GenSigTimeoutValue" SG_ 430 SRS_Front_CrashOutputSt 0;
BA_ "Remark" SG_ 430 SRS_Front_CrashOutputSt "";
BA_ "EventCommandSignal" SG_ 430 SRS_DriverSide_CrashOutputSt 0;
BA_ "GatewayedSignals" SG_ 430 SRS_DriverSide_CrashOutputSt 0;
BA_ "GenSigInactiveValue" SG_ 430 SRS_DriverSide_CrashOutputSt 0;
BA_ "GenSigInvalidValue" SG_ 430 SRS_DriverSide_CrashOutputSt 0;
BA_ "GenSigSendType" SG_ 430 SRS_DriverSide_CrashOutputSt 1;
BA_ "GenSigStartValue" SG_ 430 SRS_DriverSide_CrashOutputSt 0;
BA_ "GenSigTimeoutValue" SG_ 430 SRS_DriverSide_CrashOutputSt 0;
BA_ "Remark" SG_ 430 SRS_DriverSide_CrashOutputSt "";
BA_ "EventCommandSignal" SG_ 430 SRS_PassengerSide_CrashOutputSt 0;
BA_ "GatewayedSignals" SG_ 430 SRS_PassengerSide_CrashOutputSt 0;
BA_ "GenSigInactiveValue" SG_ 430 SRS_PassengerSide_CrashOutputSt 0;
BA_ "GenSigInvalidValue" SG_ 430 SRS_PassengerSide_CrashOutputSt 0;
BA_ "GenSigSendType" SG_ 430 SRS_PassengerSide_CrashOutputSt 1;
BA_ "GenSigStartValue" SG_ 430 SRS_PassengerSide_CrashOutputSt 0;
BA_ "GenSigTimeoutValue" SG_ 430 SRS_PassengerSide_CrashOutputSt 0;
BA_ "Remark" SG_ 430 SRS_PassengerSide_CrashOutputSt "";
BA_ "EventCommandSignal" SG_ 430 SRS_Rear_CrashOutputSt 0;
BA_ "GatewayedSignals" SG_ 430 SRS_Rear_CrashOutputSt 0;
BA_ "GenSigInactiveValue" SG_ 430 SRS_Rear_CrashOutputSt 0;
BA_ "GenSigInvalidValue" SG_ 430 SRS_Rear_CrashOutputSt 0;
BA_ "GenSigSendType" SG_ 430 SRS_Rear_CrashOutputSt 1;
BA_ "GenSigStartValue" SG_ 430 SRS_Rear_CrashOutputSt 0;
BA_ "GenSigTimeoutValue" SG_ 430 SRS_Rear_CrashOutputSt 0;
BA_ "Remark" SG_ 430 SRS_Rear_CrashOutputSt "";
BA_ "EventCommandSignal" SG_ 430 SRS_RolloverCrashOutputSt 0;
BA_ "GatewayedSignals" SG_ 430 SRS_RolloverCrashOutputSt 0;
BA_ "GenSigInactiveValue" SG_ 430 SRS_RolloverCrashOutputSt 0;
BA_ "GenSigInvalidValue" SG_ 430 SRS_RolloverCrashOutputSt 0;
BA_ "GenSigSendType" SG_ 430 SRS_RolloverCrashOutputSt 1;
BA_ "GenSigStartValue" SG_ 430 SRS_RolloverCrashOutputSt 0;
BA_ "GenSigTimeoutValue" SG_ 430 SRS_RolloverCrashOutputSt 0;
BA_ "Remark" SG_ 430 SRS_RolloverCrashOutputSt "";
BA_ "EventCommandSignal" SG_ 430 SRS_NearCrashOutputSt 0;
BA_ "GatewayedSignals" SG_ 430 SRS_NearCrashOutputSt 0;
BA_ "GenSigInactiveValue" SG_ 430 SRS_NearCrashOutputSt 0;
BA_ "GenSigInvalidValue" SG_ 430 SRS_NearCrashOutputSt 0;
BA_ "GenSigSendType" SG_ 430 SRS_NearCrashOutputSt 1;
BA_ "GenSigStartValue" SG_ 430 SRS_NearCrashOutputSt 0;
BA_ "GenSigTimeoutValue" SG_ 430 SRS_NearCrashOutputSt 0;
BA_ "Remark" SG_ 430 SRS_NearCrashOutputSt "";
BA_ "EventCommandSignal" SG_ 430 SRS_YawSnsCalibSt 0;
BA_ "GatewayedSignals" SG_ 430 SRS_YawSnsCalibSt 0;
BA_ "GenSigInactiveValue" SG_ 430 SRS_YawSnsCalibSt 0;
BA_ "GenSigInvalidValue" SG_ 430 SRS_YawSnsCalibSt 0;
BA_ "GenSigSendType" SG_ 430 SRS_YawSnsCalibSt 1;
BA_ "GenSigStartValue" SG_ 430 SRS_YawSnsCalibSt 0;
BA_ "GenSigTimeoutValue" SG_ 430 SRS_YawSnsCalibSt 0;
BA_ "Remark" SG_ 430 SRS_YawSnsCalibSt "";
BA_ "EventCommandSignal" SG_ 430 SRS_VehLongAccelVD 0;
BA_ "GatewayedSignals" SG_ 430 SRS_VehLongAccelVD 0;
BA_ "GenSigInactiveValue" SG_ 430 SRS_VehLongAccelVD 0;
BA_ "GenSigInvalidValue" SG_ 430 SRS_VehLongAccelVD 0;
BA_ "GenSigSendType" SG_ 430 SRS_VehLongAccelVD 1;
BA_ "GenSigStartValue" SG_ 430 SRS_VehLongAccelVD 0;
BA_ "GenSigTimeoutValue" SG_ 430 SRS_VehLongAccelVD 2;
BA_ "Remark" SG_ 430 SRS_VehLongAccelVD "";
BA_ "EventCommandSignal" SG_ 430 SRS_VehLatrlAccelVD 0;
BA_ "GatewayedSignals" SG_ 430 SRS_VehLatrlAccelVD 0;
BA_ "GenSigInactiveValue" SG_ 430 SRS_VehLatrlAccelVD 0;
BA_ "GenSigInvalidValue" SG_ 430 SRS_VehLatrlAccelVD 0;
BA_ "GenSigSendType" SG_ 430 SRS_VehLatrlAccelVD 1;
BA_ "GenSigStartValue" SG_ 430 SRS_VehLatrlAccelVD 0;
BA_ "GenSigTimeoutValue" SG_ 430 SRS_VehLatrlAccelVD 2;
BA_ "Remark" SG_ 430 SRS_VehLatrlAccelVD "";
BA_ "EventCommandSignal" SG_ 430 SRS_YawRateVD 0;
BA_ "GatewayedSignals" SG_ 430 SRS_YawRateVD 0;
BA_ "GenSigInactiveValue" SG_ 430 SRS_YawRateVD 0;
BA_ "GenSigInvalidValue" SG_ 430 SRS_YawRateVD 0;
BA_ "GenSigSendType" SG_ 430 SRS_YawRateVD 1;
BA_ "GenSigStartValue" SG_ 430 SRS_YawRateVD 0;
BA_ "GenSigTimeoutValue" SG_ 430 SRS_YawRateVD 2;
BA_ "Remark" SG_ 430 SRS_YawRateVD "";
BA_ "EventCommandSignal" SG_ 430 SRS_VehLongAccel 0;
BA_ "GatewayedSignals" SG_ 430 SRS_VehLongAccel 0;
BA_ "GenSigInactiveValue" SG_ 430 SRS_VehLongAccel 0;
BA_ "GenSigInvalidValue" SG_ 430 SRS_VehLongAccel 0;
BA_ "GenSigSendType" SG_ 430 SRS_VehLongAccel 1;
BA_ "GenSigStartValue" SG_ 430 SRS_VehLongAccel 2000;
BA_ "GenSigTimeoutValue" SG_ 430 SRS_VehLongAccel 2000;
BA_ "Remark" SG_ 430 SRS_VehLongAccel "";
BA_ "EventCommandSignal" SG_ 430 SRS_VehLatrlAccel 0;
BA_ "GatewayedSignals" SG_ 430 SRS_VehLatrlAccel 0;
BA_ "GenSigInactiveValue" SG_ 430 SRS_VehLatrlAccel 0;
BA_ "GenSigInvalidValue" SG_ 430 SRS_VehLatrlAccel 0;
BA_ "GenSigSendType" SG_ 430 SRS_VehLatrlAccel 1;
BA_ "GenSigStartValue" SG_ 430 SRS_VehLatrlAccel 2000;
BA_ "GenSigTimeoutValue" SG_ 430 SRS_VehLatrlAccel 2000;
BA_ "Remark" SG_ 430 SRS_VehLatrlAccel "";
BA_ "EventCommandSignal" SG_ 430 SRS_YawRate 0;
BA_ "GatewayedSignals" SG_ 430 SRS_YawRate 0;
BA_ "GenSigInactiveValue" SG_ 430 SRS_YawRate 0;
BA_ "GenSigInvalidValue" SG_ 430 SRS_YawRate 0;
BA_ "GenSigSendType" SG_ 430 SRS_YawRate 1;
BA_ "GenSigStartValue" SG_ 430 SRS_YawRate 18000;
BA_ "GenSigTimeoutValue" SG_ 430 SRS_YawRate 18000;
BA_ "Remark" SG_ 430 SRS_YawRate "";
BA_ "EventCommandSignal" SG_ 831 VCU_ChgActiveSt 0;
BA_ "GatewayedSignals" SG_ 831 VCU_ChgActiveSt 0;
BA_ "GenSigInactiveValue" SG_ 831 VCU_ChgActiveSt 0;
BA_ "GenSigInvalidValue" SG_ 831 VCU_ChgActiveSt 0;
BA_ "GenSigSendType" SG_ 831 VCU_ChgActiveSt 1;
BA_ "GenSigStartValue" SG_ 831 VCU_ChgActiveSt 0;
BA_ "GenSigTimeoutValue" SG_ 831 VCU_ChgActiveSt 0;
BA_ "Remark" SG_ 831 VCU_ChgActiveSt "涉及ID管理表";
BA_ "EventCommandSignal" SG_ 290 IPDS_FrontRadarPowerSup 1;
BA_ "GatewayedSignals" SG_ 290 IPDS_FrontRadarPowerSup 0;
BA_ "GenSigInactiveValue" SG_ 290 IPDS_FrontRadarPowerSup 0;
BA_ "GenSigInvalidValue" SG_ 290 IPDS_FrontRadarPowerSup 0;
BA_ "GenSigSendType" SG_ 290 IPDS_FrontRadarPowerSup 0;
BA_ "GenSigStartValue" SG_ 290 IPDS_FrontRadarPowerSup 3;
BA_ "GenSigTimeoutValue" SG_ 290 IPDS_FrontRadarPowerSup 0;
BA_ "Remark" SG_ 290 IPDS_FrontRadarPowerSup "";
BA_ "EventCommandSignal" SG_ 290 IPDS_FLRadarPowerSup 1;
BA_ "GatewayedSignals" SG_ 290 IPDS_FLRadarPowerSup 0;
BA_ "GenSigInactiveValue" SG_ 290 IPDS_FLRadarPowerSup 0;
BA_ "GenSigInvalidValue" SG_ 290 IPDS_FLRadarPowerSup 0;
BA_ "GenSigSendType" SG_ 290 IPDS_FLRadarPowerSup 0;
BA_ "GenSigStartValue" SG_ 290 IPDS_FLRadarPowerSup 3;
BA_ "GenSigTimeoutValue" SG_ 290 IPDS_FLRadarPowerSup 0;
BA_ "Remark" SG_ 290 IPDS_FLRadarPowerSup "";
BA_ "EventCommandSignal" SG_ 290 IPDS_FRRadarPowerSup 1;
BA_ "GatewayedSignals" SG_ 290 IPDS_FRRadarPowerSup 0;
BA_ "GenSigInactiveValue" SG_ 290 IPDS_FRRadarPowerSup 0;
BA_ "GenSigInvalidValue" SG_ 290 IPDS_FRRadarPowerSup 0;
BA_ "GenSigSendType" SG_ 290 IPDS_FRRadarPowerSup 0;
BA_ "GenSigStartValue" SG_ 290 IPDS_FRRadarPowerSup 3;
BA_ "GenSigTimeoutValue" SG_ 290 IPDS_FRRadarPowerSup 0;
BA_ "Remark" SG_ 290 IPDS_FRRadarPowerSup "";
BA_ "EventCommandSignal" SG_ 290 IPDS_HDMapPowerSup 1;
BA_ "GatewayedSignals" SG_ 290 IPDS_HDMapPowerSup 0;
BA_ "GenSigInactiveValue" SG_ 290 IPDS_HDMapPowerSup 0;
BA_ "GenSigInvalidValue" SG_ 290 IPDS_HDMapPowerSup 0;
BA_ "GenSigSendType" SG_ 290 IPDS_HDMapPowerSup 0;
BA_ "GenSigStartValue" SG_ 290 IPDS_HDMapPowerSup 3;
BA_ "GenSigTimeoutValue" SG_ 290 IPDS_HDMapPowerSup 0;
BA_ "Remark" SG_ 290 IPDS_HDMapPowerSup "";
BA_ "EventCommandSignal" SG_ 290 IPDS_Lidar1PowerSup 1;
BA_ "GatewayedSignals" SG_ 290 IPDS_Lidar1PowerSup 0;
BA_ "GenSigInactiveValue" SG_ 290 IPDS_Lidar1PowerSup 0;
BA_ "GenSigInvalidValue" SG_ 290 IPDS_Lidar1PowerSup 0;
BA_ "GenSigSendType" SG_ 290 IPDS_Lidar1PowerSup 0;
BA_ "GenSigStartValue" SG_ 290 IPDS_Lidar1PowerSup 3;
BA_ "GenSigTimeoutValue" SG_ 290 IPDS_Lidar1PowerSup 0;
BA_ "Remark" SG_ 290 IPDS_Lidar1PowerSup "";
BA_ "EventCommandSignal" SG_ 290 IPDS_RearRadarPowerSup 1;
BA_ "GatewayedSignals" SG_ 290 IPDS_RearRadarPowerSup 0;
BA_ "GenSigInactiveValue" SG_ 290 IPDS_RearRadarPowerSup 0;
BA_ "GenSigInvalidValue" SG_ 290 IPDS_RearRadarPowerSup 0;
BA_ "GenSigSendType" SG_ 290 IPDS_RearRadarPowerSup 0;
BA_ "GenSigStartValue" SG_ 290 IPDS_RearRadarPowerSup 3;
BA_ "GenSigTimeoutValue" SG_ 290 IPDS_RearRadarPowerSup 0;
BA_ "Remark" SG_ 290 IPDS_RearRadarPowerSup "";
VAL_ 371 ADC_SteerTqSt 0 "No request" 1 "Ready" 2 "Active" 3 "Reserved"  ;
VAL_ 371 ADC_TqEvsSteerReq 0 "Normal" 1 "Emergency"  ;
VAL_ 371 ADC_SteerTqAvl 0 "Not available" 1 "Available"  ;
VAL_ 371 ADC_DycEscTarTqVld 0 "Invalid" 1 "Valid"  ;
VAL_ 371 ADC_DycEscTarTqEna 0 "disable" 1 "enable"  ;
VAL_ 371 ADC_RoadTyp 0 "Flat road" 1 "Bumpy road" 2 "Gravel road" 3 "Reserved" 4 "Reserved" 5 "Reserved" 6 "Reserved" 7 "Invalid"  ;
VAL_ 371 ADC_RiWhlRoadFeature 0 "No Object" 1 "Speed Bump" 2 "Manhole cover" 3 "High-speed vibration zone" 4 "Continuous Speed Bumps" 5 "Bridge joint" 6 "Cement joint" 7 "Pit" 8 "Others" 15 "Invalid"  ;
VAL_ 371 ADC_SuspensionStatus 0 "No request" 1 "Auto_Disable" 2 "Manual_Disable" 3 "Disable" 4 "Reserved" 5 "Reserved" 6 "Reserved" 7 "Reserved"  ;
VAL_ 371 ADC_LeWhlRoadSts 0 "Unknown" 1 "flat" 2 "concave" 3 "convex"  ;
VAL_ 371 ADC_LeWhlRoadFeature 0 "No Object" 1 "Speed Bump" 2 "Manhole cover" 3 "High-speed vibration zone" 4 "Continuous Speed Bumps" 5 "Bridge joint" 6 "Cement joint" 7 "Pit" 8 "Others" 15 "Invalid"  ;
VAL_ 371 ADC_RiWhlRoadSts 0 "Unknown" 1 "flat" 2 "concave" 3 "convex"  ;
VAL_ 371 ADC_CDCCtrlEnable 0 "disable" 1 "enable"  ;
VAL_ 371 ADC_RoadInfoAvl 0 "Not Available" 1 "Available"  ;
VAL_ 371 ADC_RoadFeatureDetFalutSts 0 "No error" 1 "Error"  ;
VAL_ 371 ADC_RoadFeatureDetWorkSts 0 "Invalid" 1 "Valid" 2 "Inhibit" 3 "Reserve"  ;
VAL_ 371 ADC_LeWhlRoadFeature2 0 "No Object" 1 "Speed Bump" 2 "Manhole cover" 3 "High-speed vibration zone" 4 "Continuous Speed Bumps" 5 "Bridge joint" 6 "Cement joint" 7 "Pit" 8 "Others" 15 "Invalid"  ;
VAL_ 371 ADC_LeWhlRoadFeature3 0 "No Object" 1 "Speed Bump" 2 "Manhole cover" 3 "High-speed vibration zone" 4 "Continuous Speed Bumps" 5 "Bridge joint" 6 "Cement joint" 7 "Pit" 8 "Others" 15 "Invalid"  ;
VAL_ 371 ADC_RiWhlRoadFeature2 0 "No Object" 1 "Speed Bump" 2 "Manhole cover" 3 "High-speed vibration zone" 4 "Continuous Speed Bumps" 5 "Bridge joint" 6 "Cement joint" 7 "Pit" 8 "Others" 15 "Invalid"  ;
VAL_ 371 ADC_RiWhlRoadFeature3 0 "No Object" 1 "Speed Bump" 2 "Manhole cover" 3 "High-speed vibration zone" 4 "Continuous Speed Bumps" 5 "Bridge joint" 6 "Cement joint" 7 "Pit" 8 "Others" 15 "Invalid"  ;
VAL_ 371 ADC_LeWhlRoadHei2 0 "Default" 1 "<-10cm" 2 "-10~-5cm" 3 "-5~0cm" 4 "0~5cm" 5 "5~10cm" 6 "＞10cm" 7 "Invalid"  ;
VAL_ 371 ADC_LeWhlRoadHei3 0 "Default" 1 "<-10cm" 2 "-10~-5cm" 3 "-5~0cm" 4 "0~5cm" 5 "5~10cm" 6 "＞10cm" 7 "Invalid"  ;
VAL_ 371 ADC_RiWhlRoadHei2 0 "Default" 1 "<-10cm" 2 "-10~-5cm" 3 "-5~0cm" 4 "0~5cm" 5 "5~10cm" 6 "＞10cm" 7 "Invalid"  ;
VAL_ 371 ADC_RiWhlRoadHei3 0 "Default" 1 "<-10cm" 2 "-10~-5cm" 3 "-5~0cm" 4 "0~5cm" 5 "5~10cm" 6 "＞10cm" 7 "Invalid"  ;
VAL_ 371 ADC_LeWhlLgtDst2 63 "Invalid"  ;
VAL_ 371 ADC_LeWhlLgtDst3 63 "Invalid"  ;
VAL_ 371 ADC_RiWhlLgtDst2 63 "Invalid"  ;
VAL_ 371 ADC_RiWhlLgtDst3 63 "Invalid"  ;
VAL_ 371 ADC_AS_SuspHeiAdj 0 "Invalid" 1 "PAS Request to Very high level" 2 "PAS Request to High level" 3 "PAS Request to Normal level" 4 "PAS Request to Low level" 5 "PAS Request to Very low level" 6 "Reserve" 7 "Reserve"  ;
VAL_ 371 ADC_AS_SuspHeiAdjVld 0 "Invalid" 1 "Valid"  ;
VAL_ 371 ADC_AS_SusStfnAdj 0 "No request" 1 "Soft" 2 "Hard"  ;
VAL_ 371 ADC_AS_SusStfnAdjVld 0 "Invalid" 1 "Valid"  ;
VAL_ 371 ADC_CDCModReq 0 "No request" 1 "comfort（low）" 2 "comfort（middle）" 3 "comfort（high）" 4 "sport（low）" 5 "sport（middle）" 6 "sport（high）" 7 "reserve"  ;
VAL_ 371 ADC_CDCModReqVld 0 "Invalid" 1 "Valid"  ;
VAL_ 371 ADC_AS_LevelingAdj 0 "Not request" 1 "Level 1" 2 "Level 2" 3 "Level 3"  ;
VAL_ 371 ADC_AS_LevelingAdjVld 0 "Invalid" 1 "Valid"  ;
VAL_ 371 ADC_SdcPreAdjFL1 0 "No Request" 1 "Soft1" 2 "Soft2" 3 "Soft3" 4 "Hard1" 5 "Hard2" 6 "Hard3"  ;
VAL_ 371 ADC_SdcPreAdjFR1 0 "No Request" 1 "Soft1" 2 "Soft2" 3 "Soft3" 4 "Hard1" 5 "Hard2" 6 "Hard3"  ;
VAL_ 371 ADC_SdcPreAdjVld 0 "Invalid" 1 "Valid"  ;
VAL_ 1359 CCU_NMCBV 0 "Node has not woken up the    network(passive wakeup);" 1 "Node has woken up the network(active wakeup)" 0 "NM PDU contains no Partial Network request information" 1 "NM PDU contains Partial Network request information"  ;
VAL_ 1359 CCU_NMWakeupOrigin 0 "Reserved" 1 "CAN channel 0" 2 "CAN channel 1" 3 "CAN channel 2" 4 "CAN channel 3" 5 "CAN channel 4" 6 "CAN channel 5" 7 "CAN channel 6" 8 "CAN channel 7" 9 "CAN channel 8" 10 "CAN channel 9" 11 "CAN channel 10" 12 "CAN channel 11" 13 "CAN channel 12" 14 "CAN channel 13" 15 "CAN channel 14" 16 "CAN channel 15" 17 "Reserved" 18 "Reserved" 19 "Reserved" 20 "AcoreRequest" 21 "Reserved" 22 "Reserved" 23 "Reserved" 24 "Reserved" 25 "Reserved" 26 "Reserved" 27 "Reserved" 28 "Reserved" 29 "Reserved" 30 "Reserved" 31 "Reserved" 32 "Reserved" 33 "Reserved" 34 "Reserved" 35 "Reserved" 36 "Reserved" 37 "Reserved" 38 "Reserved" 39 "Reserved" 40 "Reserved" 41 "Reserved" 42 "Reserved" 43 "Reserved" 44 "Reserved" 45 "Reserved" 46 "Reserved" 47 "Reserved" 48 "Reserved" 49 "Reserved" 50 "UsageModeSt" 51 "NMiDPSNMKeepAwakeFlag" 52 "NMEEMKeepAwakeFlag" 53 "NMEEMKeepAwakeFlag_Aux" 54 "NMVCUGlobalKeepAwakeFlag" 55 "NMVCUChargingKeepAwakeFlag（新能源，VCU_hcu）" 56 "DoIPActiveLineStatus" 57 "NMBMSGlobalKeepAwakeFlag" 58 "NMBMSChargingKeepAwakeFlag" 59 "NMBMSThermalRunawayKeepAwakeFlag（新能源，BMS）" 60 "Reserved" 61 "NMBMSThermalRunawayKeepAwakeFlag （动力，VCU_slccu）" 62 "NMVCUChargingKeepAwakeFlag（动力，VCU_slccu）" 63 "NMVCU2GlobalKeepAwakeFlag" 64 "NMVHMKeepAwakeFlag" 65 "Reserved" 66 "CSM_RC_KeepAwake" 67 "NMHVACKeepAwakeFlag（新能源，TMS）" 68 "Reserved" 69 "Reserved" 70 "BDC_NMBDCKeepAwakeFlag" 71 "NMTMSChargingKeepAwakeFlag" 72 "NMTMSGlobalKeepAwakeFlag" 73 "Reserved" 74 "Reserved" 75 "Reserved" 76 "Reserved" 77 "Reserved" 78 "Reserved" 79 "Reserved" 80 "Reserved" 81 "Reserved" 82 "Reserved" 83 "Reserved" 84 "Reserved" 85 "Reserved" 86 "Reserved" 87 "Reserved" 88 "Reserved" 89 "NMWCCDownloadRequest_RT1" 90 "CAN7_DiagMSG_ID ！" 91 "CAN7_DiagMSG_ID" 92 "Reserved" 93 "Reserved" 94 "Reserved" 95 "Reserved" 96 "Reserved" 97 "Reserved" 98 "Reserved" 99 "Reserved" 100 "NMATWSKeepAwakeFlag" 101 "NMExteriorLightKeepAwakeFlag" 102 "NMLockingKeepAwakeFlag" 103 "NMPWLKeepAwakeFlag" 104 "NMSunRoofKeepAwakeFlag" 105 "NMPLGKeepAwakeFlag" 106 "NMPowerOperatedDoorKeepAwakeFlag" 107 "MR_NMMirrorKeepAwakeFlag" 108 "NMSeatControlKeepAwakeFlag" 109 "NMHVACKeepAwakeFlag" 110 "NMHVACRLSLinAwakeFlag" 111 "NMAQCKeepAwakeFlag" 112 "NMTPMSKeepAwakeFlag" 113 "ILC_NMKeepAwakeFlag" 114 "NMESMKeepAwakeFlag" 115 "NMKAEKeepAwakeFlag" 116 "NMVRMPNCCharingKeepAwakeFlag" 140 "NMWCCDownloadReques_RT2"  ;
VAL_ 1359 CCU_PNCInformation0 0 "No request" 1 "Request" 0 "No request" 1 "Request" 0 "No request" 1 "Request" 0 "No request" 1 "Request" 1 "Request" 0 "No request" 1 "Request" 0 "No request" 1 "Request"  ;
VAL_ 1359 CCU_PNCInformation1 0 "No request" 1 "Request" 0 "No request" 1 "Request"  ;
VAL_ 905 ICM_SetIACCSt 0 "Not active" 1 "Active"  ;
VAL_ 516 VCU_MaxDriveTorqVD 0 "Not valid" 1 "Valid"  ;
VAL_ 516 VCU_RecpTorqVD 0 "Invalid;" 1 "Valid;"  ;
VAL_ 516 VCU_MaxRecpTorqVD 0 "Invalid" 1 "Valid"  ;
VAL_ 516 VCU_CrntGearLvl 0 "Invalid" 1 "'D' Drive gear" 2 "'N' Neutral gear" 3 "'R' Reverse gear" 4 "'P' Park gear" 5 "Not used" 6 "Not used" 7 "Not used"  ;
VAL_ 516 VCU_CrntGearLvlVD 1 "Valid;" 0 "Not valid.;"  ;
VAL_ 516 VCU_BrkPedPstVD 0 "Not valid" 1 "Valid"  ;
VAL_ 516 VCU_GearIntervern 0 "with not intervention" 1 "with intervention"  ;
VAL_ 516 VCU_AccPedalVirtPstVD 0 "Not valid" 1 "Valid"  ;
VAL_ 516 VCU_AccPedalVirtPst 511 "error;" 510 "Init;"  ;
VAL_ 516 VCU_BrkPedalSt 0 "Not pressed                                                                     1"  ;
VAL_ 516 VCU_BrkPedalStVD 0 "Not Valid                                                                           1"  ;
VAL_ 516 VCU_ACCLimitOperatingSt 0 "Not active" 1 "active"  ;
VAL_ 516 VCU_AccButtInfo 0 "not press" 1 "press" 0 "not press" 1 "press" 0 "not press" 1 "press" 0 "not press" 1 "press" 0 "not press" 1 "press" 0 "Normal" 1 "Abnormal"  ;
VAL_ 516 VCU_ACCmaxSpdLimit 0 "No Limit" 1 "10 Km/h" 2 "20 Km/h" 3 "30 Km/h" 4 "40 Km/h" 5 "50 Km/h" 6 "60 Km/h" 7 "70 Km/h" 8 "80 Km/h" 9 "90 Km/h" 10 "100 Km/h" 11 "110 Km/h" 12 "120 Km/h" 13 "130 Km/h" 14 "140 Km/h" 15 "Reserved"  ;
VAL_ 516 VCU_RecpTorqFAVD 1 "Valid;" 0 "Invalid;"  ;
VAL_ 516 VCU_RecpTorqRAVD 1 "Valid;" 0 "Invalid;"  ;
VAL_ 516 VCU_MaxRecpTorqFAVD 1 "Valid;" 0 "Not valid;"  ;
VAL_ 516 VCU_MaxRecpTorqRAVD 1 "Valid;" 0 "Not valid;"  ;
VAL_ 516 VCU_BcsDecelEnable 0 "Not active" 1 "Active"  ;
VAL_ 516 VCU_CrntGearNoTrans 4 "'P' Park gear;" 3 "'R' Reverse gear;" 2 "'N' Neutral gear;" 1 "'D' Drive gear;" 0 "Invalid;"  ;
VAL_ 516 VCU_EzTSt 0 "Invalid" 1 "Off" 2 "Standby" 3 "Active"  ;
VAL_ 516 VCU_ITASSt 0 "invalid" 1 "Off" 2 "Standby" 3 "Active" 4 "Rampoff Request" 5 "Rampoff2" 6 "Reserved" 7 "Reserved"  ;
VAL_ 909 LCK_HoodAjarSt 0 "Closed" 1 "Opened"  ;
VAL_ 909 LCK_FrontLeftDoorAjarSt 0 "Closed" 1 "Opened"  ;
VAL_ 909 LCK_FrontRightDoorAjarSt 0 "Closed" 1 "Opened"  ;
VAL_ 909 LCK_RearLeftDoorAjarSt 0 "Closed" 1 "Opened"  ;
VAL_ 909 LCK_RearRightDoorAjarSt 0 "Closed" 1 "Opened"  ;
VAL_ 909 LCK_TrunkAjarSt 0 "Closed" 1 "Opened"  ;
VAL_ 909 LCK_FrontLeftDoorLockSt 0 "Locked" 1 "Unlocked"  ;
VAL_ 909 LCK_FrontRightDoorLockSt 0 "Locked" 1 "Unlocked"  ;
VAL_ 909 LCK_RearLeftDoorLockSt 0 "Locked" 1 "Unlocked"  ;
VAL_ 909 LCK_RearRightDoorLockSt 0 "Locked" 1 "Unlocked"  ;
VAL_ 909 LCK_RearLeftChildSaftyLockSt 0 "Locked" 1 "Unlocked"  ;
VAL_ 909 LCK_RearRightChildSaftyLockSt 0 "Locked" 1 "Unlocked"  ;
VAL_ 909 EMS_EngStForPHEV 0 "Standby" 1 "Ready" 2 "Cranking" 3 "Running" 4 "Stopping" 5 "Stopped" 6 "Aotostopping"  ;
VAL_ 909 WCM_Reminder 0 "No_warning" 1 "Phone_left_in_car"  ;
VAL_ 909 WCM_ChargingSt 0 "Standby" 1 "Charging" 2 "Charging completed (available when Rx support)" 3 "Not standby"  ;
VAL_ 909 LCK_FrontLeftDoorHandlePosition 0 "FullyClosed" 100 "FullyOpened" 254 "Uninitialized" 255 "Unknown"  ;
VAL_ 909 LCK_FrontRightDoorHandlePosition 0 "FullyClosed" 100 "FullyOpened" 254 "Uninitialized" 255 "Unknown"  ;
VAL_ 909 LCK_RearLeftDoorHandlePosition 0 "FullyClosed" 100 "FullyOpened" 254 "Uninitialized" 255 "Unknown"  ;
VAL_ 909 LCK_RearRightDoorHandlePosition 0 "FullyClosed" 100 "FullyOpened" 254 "Uninitialized" 255 "Unknown"  ;
VAL_ 909 WW_RWPMotorSt 0 "Off" 1 "Reserve" 2 "Stall protection" 3 "Failure" 4 "Low speed" 5 "High speed" 6 "Hard stopped" 7 "Interval delaying"  ;
VAL_ 909 LCK_FillerCapASt 0 "Closed" 1 "Opened"  ;
VAL_ 909 LCK_FillerCapBSt 0 "Closed" 1 "Opened"  ;
VAL_ 909 MR_LeftMirrorFoldUnfoldSt 0 "Unknown" 1 "Mirror fold" 2 "Mirror unfold" 3 "Reserved"  ;
VAL_ 909 SBM_SwapHvBattModeSt 0 "default" 1 "Station open the door for veichle go in" 2 "Station find Vehicle stop OK" 3 "Station prepare to swap" 4 "Station begin to swap" 5 "Station finish assembling" 6 "Station complete to swap" 7 "Station pause swapping" 8 "Station open the door for veichle go out"  ;
VAL_ 909 SBM_SwapStaDiagCode 0 "Normal" 1 "Fault,BT cominication error" 2 "Fault,SWAP station error" 3 "Fault,vehile error"  ;
VAL_ 909 SBM_SwapHvBattModeFaultSt 0 "default" 1 "Normal" 2 "Error,can recovery" 3 "Error,can not recover"  ;
VAL_ 909 IPDS_HDMapPowerSt 0 "Not Active" 1 "Active"  ;
VAL_ 909 IPDS_KL15L1PowerSt 0 "Not Active" 1 "Active"  ;
VAL_ 909 IPDS_SRSECUPowerSt 0 "Not Active" 1 "Active"  ;
VAL_ 909 IPDS_HODPowerSt 0 "Not Active" 1 "Active"  ;
VAL_ 909 KAE_BLEOption 0 "Not active" 1 "Active"  ;
VAL_ 909 KAE_UWBOption 0 "Not active" 1 "Active"  ;
VAL_ 909 PWL_WinCurrentPos_FLWinPst 255 "Undefined window position"  ;
VAL_ 909 UINM_FrontLeftPowerReleaseReq 0 "NoReq" 1 "Release"  ;
VAL_ 909 UINM_FrontLeftPowerReleaseFaultSt 0 "noraml" 1 "fault"  ;
VAL_ 909 UINM_FrontRightPowerReleaseReq 0 "NoReq" 1 "Release"  ;
VAL_ 909 UINM_FrontRightPowerReleaseFaultSt 0 "noraml" 1 "fault"  ;
VAL_ 909 UINM_RearLeftPowerReleaseFaultSt 0 "noraml" 1 "fault"  ;
VAL_ 909 UINM_RearLeftPowerReleaseReq 0 "NoReq" 1 "Release"  ;
VAL_ 909 UINM_RearRightPowerReleaseFaultSt 0 "noraml" 1 "fault"  ;
VAL_ 909 UINM_RearRightPowerReleaseReq 0 "NoReq" 1 "Release"  ;
VAL_ 909 PWL_WinCurrentPos_RRWinPst 255 "Undefined window position"  ;
VAL_ 909 PWL_WinCurrentPos_RLWinPst 255 "Undefined window position"  ;
VAL_ 909 ACEleclocksSt 0 "init" 1 "Uncloked" 2 "Locked" 3 "Error,bosh open" 4 "Error,bosh close"  ;
VAL_ 909 DSASBM_MotResp 0 "No Action" 1 "Executing Retraction Assistance" 2 "Executing Clearance Removal 1" 3 "Executing Clearance Removal 2" 4 "Executing Dynamic Support 1" 5 "Executing Dynamic Support 2" 6 "Executing Pre-crash Protection" 7 "Executing Vibration Warning 1" 8 "Executing Vibration Warning 2" 9 "Reserved" 10 "Retraction Assistance Completed" 11 "Clearance Removal Completed" 12 "Executing Dynamic Support 3" 13 "Executing Dynamic Support 4" 14 "Executing Vibration Notification" 15 "Reserved"  ;
VAL_ 792 UMM_SecondRHSeatSt 0 "Undefined" 1 "Off" 2 "On" 3 "Failure"  ;
VAL_ 792 UMM_SecondLHSeatSt 0 "Undefined" 1 "Off" 2 "On" 3 "Failure"  ;
VAL_ 792 LCK_PowerFillerCapAngle 0 "FullyClosed" 255 "Unknown"  ;
VAL_ 792 EL_ReverseLightSt 0 "OFF" 1 "ON"  ;
VAL_ 792 EL_ReverseLightFaultSt 0 "Not fault" 1 "Fault"  ;
VAL_ 792 EL_RLPositionLightSt 0 "OFF" 1 "ON"  ;
VAL_ 792 EL_RLPositionLightFaultSt 0 "Not fault" 1 "Fault"  ;
VAL_ 792 EL_RRPositionLightSt 0 "OFF" 1 "ON"  ;
VAL_ 792 EL_RRPositionLightFaultSt 0 "Not fault" 1 "Fault"  ;
VAL_ 792 EL_RearFogLightSt 0 "OFF" 1 "ON"  ;
VAL_ 792 EL_RearFogLightFaultSt 0 "Not fault" 1 "Fault"  ;
VAL_ 860 VCU_RoadMod 0 "Invalid" 1 "Mud Mode" 2 "Snow Mode" 3 "Sand Mode" 4 "Offroad Mode" 5 "Slippery Mode" 7 "Off"  ;
VAL_ 860 VCU_GearLvl 0 "Invalid" 1 "'D' Drive gear" 2 "'N' Neutral gear" 3 "'R' Reverse gear" 4 "'P' Park gear" 5 "Not used" 6 "Not used" 7 "Not used" 8 "Not used" 9 "Not used" 10 "Not used" 11 "Not used" 12 "Not used" 13 "Not used" 14 "Not used" 15 "Not used"  ;
VAL_ 860 VCU_VehDrvMod 7 "Individual；" 6 "reserved；" 5 "SPORT Mode;" 4 "Driving Mode;超跑模式" 3 "Comfort Mode;" 2 "ECO Mode;" 1 "reserved；" 0 "Invalid;"  ;
VAL_ 860 VCU_VehRdySt 0 "Not ready" 1 "Ready"  ;
VAL_ 860 VCU_PlgConnSt 0 "Not connected" 1 "Plug connector connected"  ;
VAL_ 860 VCU_GearLvlDisp 0 "Invalid" 1 "'D' Drive gear" 2 "'N' Neutral gear" 3 "'R' Reverse gear" 4 "'P' Park gear" 5 "Reserved" 6 "Reserved" 7 "Reserved" 8 "Reserved" 9 "Reserved" 10 "Reserved" 11 "Reserved" 12 "Reserved" 13 "Reserved" 14 "Reserved" 15 "Reserved"  ;
VAL_ 860 VCU_SuspModeReq 0 "not request" 1 "comfort mode" 2 "normal mode(reserved)" 3 "sport mode"  ;
VAL_ 860 VCU_SuspModeReqEnable 0 "disable" 1 "enable"  ;
VAL_ 860 VCU_GearPosition 7 "Request to remove anti-theft" 6 "EPB Locking failure, return 'N' gear;" 5 "'D' Drive gear;" 4 "'R' Reverse gear;" 3 "'N' Neutral gear;" 2 "'P' Park gear;" 1 "P_Pending;" 0 "Undefined;"  ;
VAL_ 860 VCU_EcoPlusMod 0 "No command" 1 "ON" 2 "OFF" 3 "reserved"  ;
VAL_ 860 ICC_RoadMod 0 "Invalid" 1 "Highway" 2 "Auto Mode" 3 "Snow Mode" 4 "Mud Mode" 5 "Sand Mode" 6 "Ruggged Mode" 7 "Wade Mode" 8 "Expert Mode"  ;
VAL_ 860 VCU_TrailerModeSt 0 "No command" 1 "Trailer Mode is close and TRM is nunconnected" 2 "Trailer Mode is open but TRM is nunconnected" 3 "Trailer Mode is open and TRM is connected" 4 "Trailer Mode is close but TRM is connected" 5 "Trailer Mode is open but TRM connection is status unkown" 6 "Trailer Mode is close but TRM connection is status unkown" 7 "Trailer Mode is Not available"  ;
VAL_ 860 VCU_BMS_BattSocDisp 16382 "Init;" 16383 "error"  ;
VAL_ 860 ICC_360Switch 0 "No Request" 1 "ON" 2 "OFF" 3 "Reserved"  ;
VAL_ 431 VCU_TargetRecpTorqVD 1 "Valid;" 0 "Invalid;"  ;
VAL_ 431 VCU_AccDriverOrvd 0 "No override" 1 "Driver override"  ;
VAL_ 431 VCU_AccDriverOrvdVD 0 "Invalid" 1 "Valid"  ;
VAL_ 431 VCU_TargetRecpTorqFAVD 1 "Valid;" 0 "Invalid;"  ;
VAL_ 431 VCU_TargetRecpTorqRAVD 1 "Valid;" 0 "Invalid;"  ;
VAL_ 431 VCU_TorqDriverReqFAVD 1 "Valid;" 0 "Invalid;"  ;
VAL_ 431 VCU_TorqDriverReqRAVD 1 "Valid;" 0 "Invalid;"  ;
VAL_ 431 VCU_VehActDrvTorqFAVD 1 "Valid;" 0 "Invalid;"  ;
VAL_ 431 VCU_VehActDrvTorqRAVD 1 "Valid;" 0 "Invalid;"  ;
VAL_ 431 VCU_BcsDecelVD 0 "Invalid" 1 "Valid"  ;
VAL_ 431 VCU_RecpTorqRLVD 1 "Valid;" 0 "Invalid;"  ;
VAL_ 431 VCU_RecpTorqRRVD 1 "Valid;" 0 "Invalid;"  ;
VAL_ 431 VCU_ADSNetErrorFb 0 "No Error" 1 "Main Net E2E Error" 2 "Sub Net E2E Error" 3 "Both Net E2E Error" 4 "Reserved" 5 "Reserved" 6 "Reserved" 7 "Reserved"  ;
VAL_ 431 VCU_NetModeResp 0 "None" 1 "Main/sub Net active" 2 "Main/sub Net active with error" 3 "Reserved"  ;
VAL_ 431 VCU_PwrLimDrv_kWVD 0 "Not valid" 1 "Valid"  ;
VAL_ 431 VCU_PwrLimRegen_kWVD 0 "Not valid" 1 "Valid"  ;
VAL_ 431 VCU_PtTqActvStsFL 0 "Not responsed" 1 "Responsed"  ;
VAL_ 431 VCU_PtTqActvStsFR 0 "Not responsed" 1 "Responsed"  ;
VAL_ 431 VCU_PtTqActvStsRL 0 "Not responsed" 1 "Responsed"  ;
VAL_ 431 VCU_PtTqActvStsRR 0 "Not responsed" 1 "Responsed"  ;
VAL_ 430 SRS_CrashOutputSt 0 "No crash,"  ;
VAL_ 430 SRS_Front_CrashOutputSt 0 "No crash,"  ;
VAL_ 430 SRS_DriverSide_CrashOutputSt 0 "No crash,"  ;
VAL_ 430 SRS_PassengerSide_CrashOutputSt 0 "No crash,"  ;
VAL_ 430 SRS_Rear_CrashOutputSt 0 "No crash,"  ;
VAL_ 430 SRS_RolloverCrashOutputSt 0 "No crash,"  ;
VAL_ 430 SRS_NearCrashOutputSt 0 "No crash," 1 "(transition lasts for 2sec)"  ;
VAL_ 430 SRS_YawSnsCalibSt 0 "Sensor Not Calibrated" 1 "Sensor Calibrated"  ;
VAL_ 430 SRS_VehLongAccelVD 0 "Initializing" 1 "Valid" 2 "Invalid" 3 "Reserved"  ;
VAL_ 430 SRS_VehLatrlAccelVD 0 "Initializing" 1 "Valid" 2 "Invalid" 3 "Reserved"  ;
VAL_ 430 SRS_YawRateVD 0 "Initializing" 1 "Valid" 2 "Invalid" 3 "Reserved"  ;
VAL_ 831 VCU_ChgActiveSt 0 "not charging" 1 "charging"  ;
VAL_ 290 IPDS_FrontRadarPowerSup 0 "Not Active" 1 "Active" 2 "PreOFF" 3 "Invalid"  ;
VAL_ 290 IPDS_FLRadarPowerSup 0 "Not Active" 1 "Active" 2 "PreOFF" 3 "Invalid"  ;
VAL_ 290 IPDS_FRRadarPowerSup 0 "Not Active" 1 "Active" 2 "PreOFF" 3 "Invalid"  ;
VAL_ 290 IPDS_HDMapPowerSup 0 "Not Active" 1 "Active" 2 "PreOFF" 3 "Invalid"  ;
VAL_ 290 IPDS_Lidar1PowerSup 0 "Not Active" 1 "Active" 2 "PreOFF" 3 "Invalid"  ;
VAL_ 290 IPDS_RearRadarPowerSup 0 "Not Active" 1 "Active" 2 "PreOFF" 3 "Invalid"  ;
